VERSION ""

NS_ :

BS_:

BU_: SteeringControlModule SteeringController SteeringColumnUnit RearAxleSteeringController Engine ChassisController

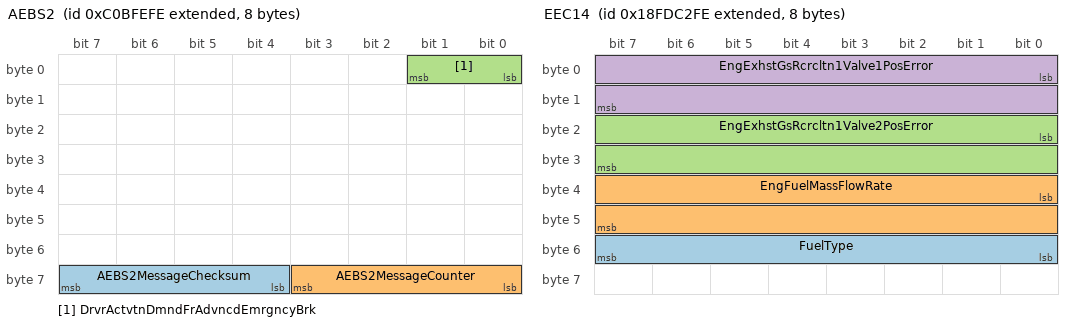
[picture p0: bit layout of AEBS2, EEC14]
BO_ 2349596414 AEBS2: 8 Vector__XXX
 SG_ AEBS2MessageChecksum : 60|4@1+ (1,0) [0|15] "" Vector__XXX
 SG_ AEBS2MessageCounter : 56|4@1+ (1,0) [0|15] "" Vector__XXX
 SG_ DrvrActvtnDmndFrAdvncdEmrgncyBrk : 0|2@1+ (1,0) [0|3] "" Vector__XXX

BO_ 2566767358 EEC14: 8 Vector__XXX
 SG_ FuelType : 48|8@1+ (1,0) [0|255] "" Vector__XXX
 SG_ EngFuelMassFlowRate : 32|16@1+ (0.005,0) [0|321.275] "g/s" Vector__XXX
 SG_ EngExhstGsRcrcltn1Valve2PosError : 16|16@1+ (0.004,-125) [-125|132.02] "%" Vector__XXX
 SG_ EngExhstGsRcrcltn1Valve1PosError : 0|16@1+ (0.004,-125) [-125|132.02] "%" Vector__XXX

BO_ 2566706686 AT1P1I: 8 Vector__XXX
 SG_ Aftrtrtmnt1DslExhstFldPumpHeater : 0|8@1+ (0.4,0) [0|100] "%" Vector__XXX

BO_ 2566705406 EPSI: 8 Vector__XXX
 SG_ Aftertreatment2ParticulateSensor : 16|16@1+ (0.0125,0) [0|803.1875] "mg/m^3" Vector__XXX
 SG_ Aftertreatment1ParticulateSensor : 0|16@1+ (0.0125,0) [0|803.1875] "mg/m^3" Vector__XXX

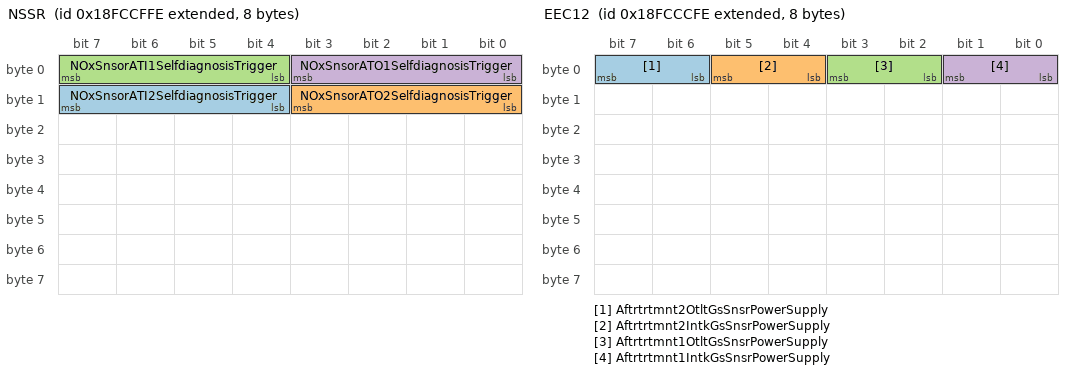
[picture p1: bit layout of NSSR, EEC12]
BO_ 2566705150 NSSR: 8 Vector__XXX
 SG_ NOxSnsorATI2SelfdiagnosisTrigger : 12|4@1+ (1,0) [0|15] "" Vector__XXX
 SG_ NOxSnsorATO2SelfdiagnosisTrigger : 8|4@1+ (1,0) [0|15] "" Vector__XXX
 SG_ NOxSnsorATI1SelfdiagnosisTrigger : 4|4@1+ (1,0) [0|15] "" Vector__XXX
 SG_ NOxSnsorATO1SelfdiagnosisTrigger : 0|4@1+ (1,0) [0|15] "" Vector__XXX

BO_ 2566704382 EEC12: 8 Vector__XXX
 SG_ Aftrtrtmnt2OtltGsSnsrPowerSupply : 6|2@1+ (1,0) [0|3] "" Vector__XXX
 SG_ Aftrtrtmnt2IntkGsSnsrPowerSupply : 4|2@1+ (1,0) [0|3] "" Vector__XXX
 SG_ Aftrtrtmnt1OtltGsSnsrPowerSupply : 2|2@1+ (1,0) [0|3] "" Vector__XXX
 SG_ Aftrtrtmnt1IntkGsSnsrPowerSupply : 0|2@1+ (1,0) [0|3] "" Vector__XXX

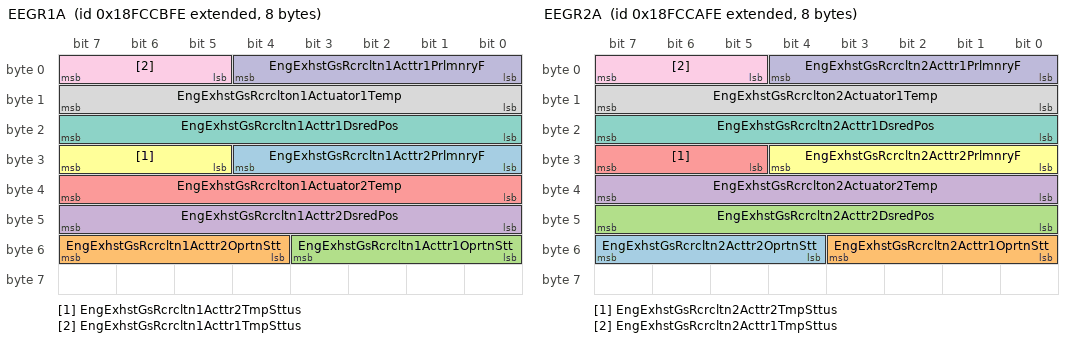
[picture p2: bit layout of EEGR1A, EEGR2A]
BO_ 2566704126 EEGR1A: 8 Vector__XXX
 SG_ EngExhstGsRcrcltn1Acttr2PrlmnryF : 24|5@1+ (1,0) [0|31] "" Vector__XXX
 SG_ EngExhstGsRcrcltn1Acttr2OprtnStt : 52|4@1+ (1,0) [0|15] "" Vector__XXX
 SG_ EngExhstGsRcrcltn1Acttr1OprtnStt : 48|4@1+ (1,0) [0|15] "" Vector__XXX
 SG_ EngExhstGsRcrcltn1Acttr2DsredPos : 40|8@1+ (0.4,0) [0|100] "%" Vector__XXX
 SG_ EngExhstGsRcrclton1Actuator2Temp : 32|8@1+ (1,-40) [-40|210] "deg C" Vector__XXX
 SG_ EngExhstGsRcrcltn1Acttr2TmpSttus : 29|3@1+ (1,0) [0|7] "" Vector__XXX
 SG_ EngExhstGsRcrcltn1Acttr1DsredPos : 16|8@1+ (0.4,0) [0|100] "%" Vector__XXX
 SG_ EngExhstGsRcrclton1Actuator1Temp : 8|8@1+ (1,-40) [-40|210] "deg C" Vector__XXX
 SG_ EngExhstGsRcrcltn1Acttr1TmpSttus : 5|3@1+ (1,0) [0|7] "" Vector__XXX
 SG_ EngExhstGsRcrcltn1Acttr1PrlmnryF : 0|5@1+ (1,0) [0|31] "" Vector__XXX

BO_ 2566703870 EEGR2A: 8 Vector__XXX
 SG_ EngExhstGsRcrcltn2Acttr2OprtnStt : 52|4@1+ (1,0) [0|15] "" Vector__XXX
 SG_ EngExhstGsRcrcltn2Acttr1OprtnStt : 48|4@1+ (1,0) [0|15] "" Vector__XXX
 SG_ EngExhstGsRcrcltn2Acttr2DsredPos : 40|8@1+ (0.4,0) [0|100] "%" Vector__XXX
 SG_ EngExhstGsRcrclton2Actuator2Temp : 32|8@1+ (1,-40) [-40|210] "deg C" Vector__XXX
 SG_ EngExhstGsRcrcltn2Acttr2TmpSttus : 29|3@1+ (1,0) [0|7] "" Vector__XXX
 SG_ EngExhstGsRcrcltn2Acttr2PrlmnryF : 24|5@1+ (1,0) [0|31] "" Vector__XXX
 SG_ EngExhstGsRcrcltn2Acttr1DsredPos : 16|8@1+ (0.4,0) [0|100] "%" Vector__XXX
 SG_ EngExhstGsRcrclton2Actuator1Temp : 8|8@1+ (1,-40) [-40|210] "deg C" Vector__XXX
 SG_ EngExhstGsRcrcltn2Acttr1TmpSttus : 5|3@1+ (1,0) [0|7] "" Vector__XXX
 SG_ EngExhstGsRcrcltn2Acttr1PrlmnryF : 0|5@1+ (1,0) [0|31] "" Vector__XXX

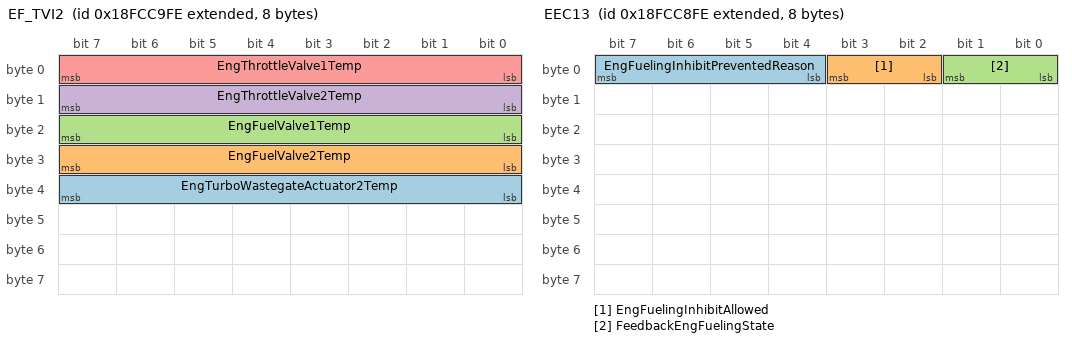
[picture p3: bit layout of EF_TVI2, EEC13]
BO_ 2566703614 EF_TVI2: 8 Vector__XXX
 SG_ EngTurboWastegateActuator2Temp : 32|8@1+ (1,-40) [-40|210] "deg C" Vector__XXX
 SG_ EngFuelValve2Temp : 24|8@1+ (1,-40) [-40|210] "deg C" Vector__XXX
 SG_ EngFuelValve1Temp : 16|8@1+ (1,-40) [-40|210] "deg C" Vector__XXX
 SG_ EngThrottleValve2Temp : 8|8@1+ (1,-40) [-40|210] "deg C" Vector__XXX
 SG_ EngThrottleValve1Temp : 0|8@1+ (1,-40) [-40|210] "deg C" Vector__XXX

BO_ 2566703358 EEC13: 8 Vector__XXX
 SG_ EngFuelingInhibitPreventedReason : 4|4@1+ (1,0) [0|15] "" Vector__XXX
 SG_ EngFuelingInhibitAllowed : 2|2@1+ (1,0) [0|3] "" Vector__XXX
 SG_ FeedbackEngFuelingState : 0|2@1+ (1,0) [0|3] "" Vector__XXX

BO_ 2566702590 A1SCREGT2: 8 Vector__XXX
 SG_ Aftrtrtmnt1SCRIntrmdtGsTmpPrlmnr : 16|5@1+ (1,0) [0|31] "" Vector__XXX
 SG_ Aftrtrtmnt1SCRIntrmediateGasTemp : 0|16@1+ (0.03125,-273) [-273|1734.96875] "deg C" Vector__XXX

BO_ 2566702334 A2SCREGT2: 8 Vector__XXX
 SG_ Aftrtrtmnt2SCRIntrmdtGsTmpPrlmnr : 16|5@1+ (1,0) [0|31] "" Vector__XXX
 SG_ Aftrtrtmnt2SCRIntrmediateGasTemp : 0|16@1+ (0.03125,-273) [-273|1734.96875] "deg C" Vector__XXX

BO_ 2566702078 GFI4: 8 Vector__XXX
 SG_ SupplyGasMethanePercentage : 0|16@1+ (0.0025,0) [0|160.6375] "%" Vector__XXX

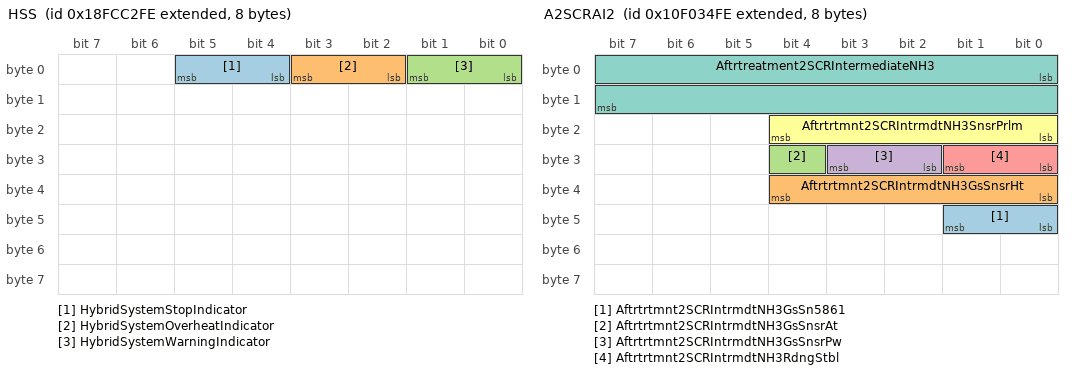
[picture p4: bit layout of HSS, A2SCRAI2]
BO_ 2566701822 HSS: 8 Vector__XXX
 SG_ HybridSystemStopIndicator : 4|2@1+ (1,0) [0|3] "" Vector__XXX
 SG_ HybridSystemOverheatIndicator : 2|2@1+ (1,0) [0|3] "" Vector__XXX
 SG_ HybridSystemWarningIndicator : 0|2@1+ (1,0) [0|3] "" Vector__XXX

BO_ 2431661310 A2SCRAI2: 8 Vector__XXX
 SG_ Aftrtrtmnt2SCRIntrmdtNH3GsSn5861 : 40|2@1+ (1,0) [0|3] "" Vector__XXX
 SG_ Aftrtrtmnt2SCRIntrmdtNH3GsSnsrHt : 32|5@1+ (1,0) [0|31] "" Vector__XXX
 SG_ Aftrtrtmnt2SCRIntrmdtNH3GsSnsrAt : 28|1@1+ (1,0) [0|1] "" Vector__XXX
 SG_ Aftrtrtmnt2SCRIntrmdtNH3GsSnsrPw : 26|2@1+ (1,0) [0|3] "" Vector__XXX
 SG_ Aftrtrtmnt2SCRIntrmdtNH3RdngStbl : 24|2@1+ (1,0) [0|3] "" Vector__XXX
 SG_ Aftrtrtmnt2SCRIntrmdtNH3SnsrPrlm : 16|5@1+ (1,0) [0|31] "" Vector__XXX
 SG_ Aftrtreatment2SCRIntermediateNH3 : 0|16@1+ (0.1,0) [0|6425.5] "m^3/h" Vector__XXX

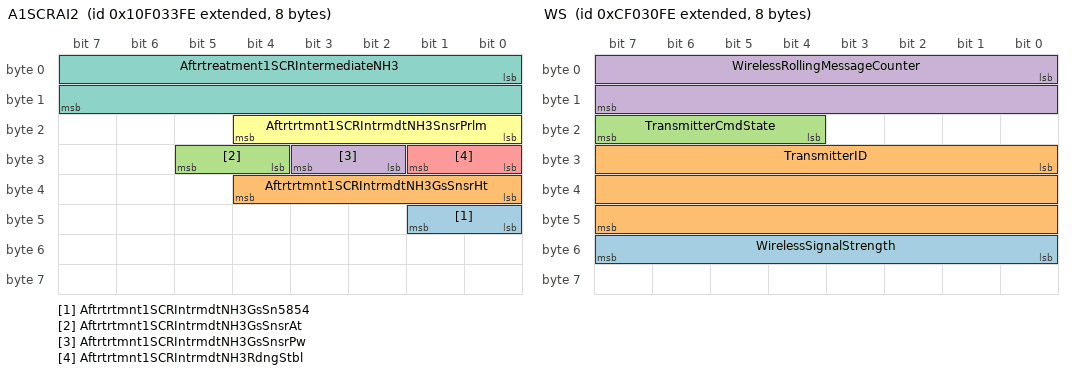
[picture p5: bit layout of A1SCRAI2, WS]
BO_ 2431661054 A1SCRAI2: 8 Vector__XXX
 SG_ Aftrtrtmnt1SCRIntrmdtNH3GsSn5854 : 40|2@1+ (1,0) [0|3] "" Vector__XXX
 SG_ Aftrtrtmnt1SCRIntrmdtNH3GsSnsrHt : 32|5@1+ (1,0) [0|31] "" Vector__XXX
 SG_ Aftrtrtmnt1SCRIntrmdtNH3GsSnsrAt : 28|2@1+ (1,0) [0|3] "" Vector__XXX
 SG_ Aftrtrtmnt1SCRIntrmdtNH3GsSnsrPw : 26|2@1+ (1,0) [0|3] "" Vector__XXX
 SG_ Aftrtrtmnt1SCRIntrmdtNH3RdngStbl : 24|2@1+ (1,0) [0|3] "" Vector__XXX
 SG_ Aftrtrtmnt1SCRIntrmdtNH3SnsrPrlm : 16|5@1+ (1,0) [0|31] "" Vector__XXX
 SG_ Aftrtreatment1SCRIntermediateNH3 : 0|16@1+ (0.3,0) [0|19276.5] "g/h" Vector__XXX

BO_ 2230334206 LDISP: 8 Vector__XXX
 SG_ LnrDsplcmntSnsrSnsrFigureOfMerit : 16|2@1+ (1,0) [0|3] "" Vector__XXX
 SG_ MeasuredLinearDisplacement : 0|16@1+ (0.1,0) [0|6425.5] "mm" Vector__XXX

BO_ 2230333950 WAND: 8 Vector__XXX
 SG_ WandSensorFigureOfMerit : 16|2@1+ (1,0) [0|3] "" Vector__XXX
 SG_ WandAngle : 0|16@1+ (0.002,-64) [-64|64.51] "deg" Vector__XXX

BO_ 2364551422 WS: 8 Vector__XXX
 SG_ WirelessSignalStrength : 48|8@1+ (0.5,0) [-125|0] "dBm" Vector__XXX
 SG_ TransmitterID : 24|24@1+ (1,0) [0|16449635] "" Vector__XXX
 SG_ TransmitterCmdState : 20|4@1+ (1,0) [0|15] "" Vector__XXX
 SG_ WirelessRollingMessageCounter : 0|16@1+ (1,0) [0|64255] "" Vector__XXX

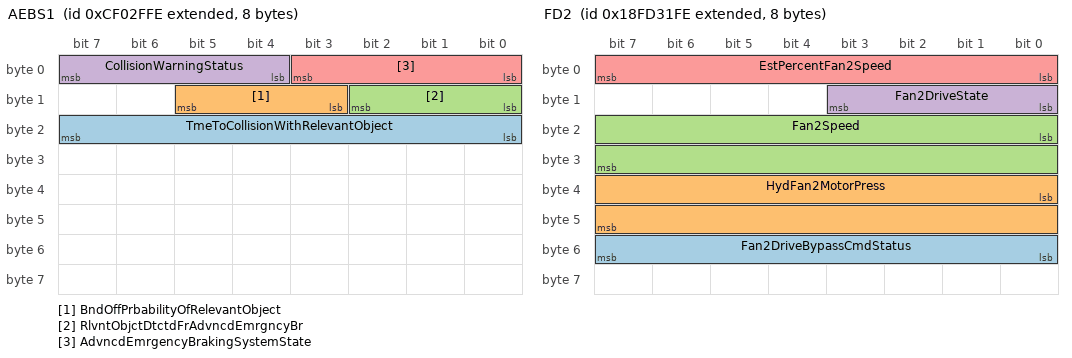
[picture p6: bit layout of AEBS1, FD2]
BO_ 2364551166 AEBS1: 8 Vector__XXX
 SG_ TmeToCollisionWithRelevantObject : 16|8@1+ (0.05,0) [0|12.5] "s" Vector__XXX
 SG_ BndOffPrbabilityOfRelevantObject : 11|3@1+ (1,0) [0|7] "" Vector__XXX
 SG_ RlvntObjctDtctdFrAdvncdEmrgncyBr : 8|3@1+ (1,0) [0|7] "" Vector__XXX
 SG_ CollisionWarningStatus : 4|4@1+ (1,0) [0|15] "" Vector__XXX
 SG_ AdvncdEmrgencyBrakingSystemState : 0|4@1+ (1,0) [0|15] "" Vector__XXX

BO_ 2566730238 FD2: 8 Vector__XXX
 SG_ Fan2DriveBypassCmdStatus : 48|8@1+ (0.4,0) [0|100] "%" Vector__XXX
 SG_ HydFan2MotorPress : 32|16@1+ (0.5,0) [0|32127.5] "kPa" Vector__XXX
 SG_ Fan2Speed : 16|16@1+ (0.125,0) [0|8031.875] "rpm" Vector__XXX
 SG_ Fan2DriveState : 8|4@1+ (1,0) [0|15] "" Vector__XXX
 SG_ EstPercentFan2Speed : 0|8@1+ (0.4,0) [0|100] "%" Vector__XXX

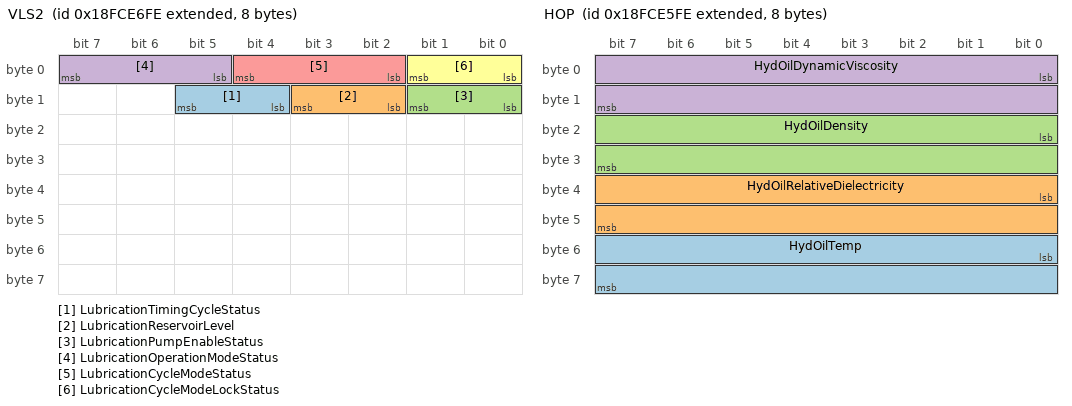
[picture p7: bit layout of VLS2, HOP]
BO_ 2566711038 VLS2: 8 Vector__XXX
 SG_ LubricationTimingCycleStatus : 12|2@1+ (1,0) [0|3] "" Vector__XXX
 SG_ LubricationReservoirLevel : 10|2@1+ (1,0) [0|3] "" Vector__XXX
 SG_ LubricationPumpEnableStatus : 8|2@1+ (1,0) [0|3] "" Vector__XXX
 SG_ LubricationOperationModeStatus : 5|3@1+ (1,0) [0|7] "" Vector__XXX
 SG_ LubricationCycleModeStatus : 2|3@1+ (1,0) [0|7] "" Vector__XXX
 SG_ LubricationCycleModeLockStatus : 0|2@1+ (1,0) [0|3] "" Vector__XXX

BO_ 2566710782 HOP: 8 Vector__XXX
 SG_ HydOilTemp : 48|16@1+ (0.03125,-273) [-273|1734.96875] "deg C" Vector__XXX
 SG_ HydOilRelativeDielectricity : 32|16@1+ (0.0001220703125,0) [0|7.844] "" Vector__XXX
 SG_ HydOilDensity : 16|16@1+ (3.052E-005,0) [0|1.961] "g/cc" Vector__XXX
 SG_ HydOilDynamicViscosity : 0|16@1+ (0.015625,0) [0|1003.984375] "Cp" Vector__XXX

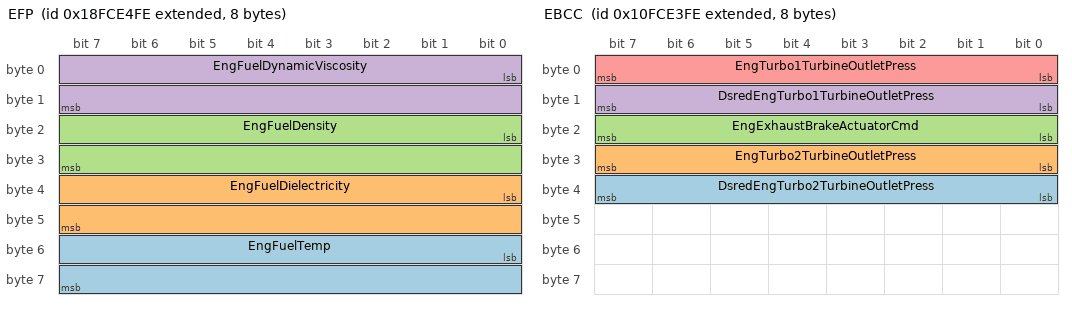
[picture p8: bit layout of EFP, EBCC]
BO_ 2566710526 EFP: 8 Vector__XXX
 SG_ EngFuelTemp : 48|16@1+ (0.03125,-273) [-273|1734.96875] "deg C" Vector__XXX
 SG_ EngFuelDielectricity : 32|16@1+ (0.0001220703125,0) [0|7.844] "" Vector__XXX
 SG_ EngFuelDensity : 16|16@1+ (3.052E-005,0) [0|1.961] "g/cc" Vector__XXX
 SG_ EngFuelDynamicViscosity : 0|16@1+ (0.015625,0) [0|1003.984375] "Cp" Vector__XXX

BO_ 2432492542 EBCC: 8 Vector__XXX
 SG_ DsredEngTurbo2TurbineOutletPress : 32|8@1+ (2,0) [0|500] "kPa" Vector__XXX
 SG_ EngTurbo2TurbineOutletPress : 24|8@1+ (2,0) [0|500] "kPa" Vector__XXX
 SG_ EngExhaustBrakeActuatorCmd : 16|8@1+ (0.4,0) [0|100] "%" Vector__XXX
 SG_ DsredEngTurbo1TurbineOutletPress : 8|8@1+ (2,0) [0|500] "kPa" Vector__XXX
 SG_ EngTurbo1TurbineOutletPress : 0|8@1+ (2,0) [0|500] "kPa" Vector__XXX

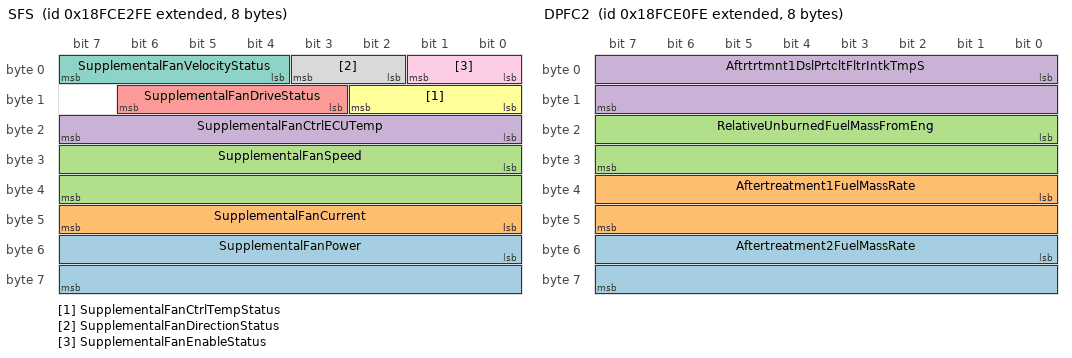
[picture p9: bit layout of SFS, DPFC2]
BO_ 2566710014 SFS: 8 Vector__XXX
 SG_ SupplementalFanPower : 48|16@1+ (0.5,0) [0|32127.5] "W" Vector__XXX
 SG_ SupplementalFanCurrent : 40|8@1+ (1,-125) [-125|125] "A" Vector__XXX
 SG_ SupplementalFanSpeed : 24|16@1+ (0.5,0) [0|32127.5] "rpm" Vector__XXX
 SG_ SupplementalFanCtrlECUTemp : 16|8@1+ (1,-40) [-40|210] "deg C" Vector__XXX
 SG_ SupplementalFanDriveStatus : 11|4@1+ (1,0) [0|15] "" Vector__XXX
 SG_ SupplementalFanCtrlTempStatus : 8|3@1+ (1,0) [0|7] "" Vector__XXX
 SG_ SupplementalFanVelocityStatus : 4|4@1+ (1,0) [0|15] "" Vector__XXX
 SG_ SupplementalFanDirectionStatus : 2|2@1+ (1,0) [0|3] "" Vector__XXX
 SG_ SupplementalFanEnableStatus : 0|2@1+ (1,0) [0|3] "" Vector__XXX

BO_ 2566709758 LFE2: 8 Vector__XXX
 SG_ HighResolutionEngFuelRate : 0|32@1+ (0.001,0) [0|4211081.215] "L/h" Vector__XXX

BO_ 2566709502 DPFC2: 8 Vector__XXX
 SG_ Aftertreatment2FuelMassRate : 48|16@1+ (0.05,0) [0|3212.75] "g/m" Vector__XXX
 SG_ Aftertreatment1FuelMassRate : 32|16@1+ (0.05,0) [0|3212.75] "g/m" Vector__XXX
 SG_ RelativeUnburnedFuelMassFromEng : 16|16@1+ (0.0025,0) [0|160.6375] "%" Vector__XXX
 SG_ Aftrtrtmnt1DslPrtcltFltrIntkTmpS : 0|16@1+ (0.03125,-273) [-273|1734.96875] "deg C" Vector__XXX

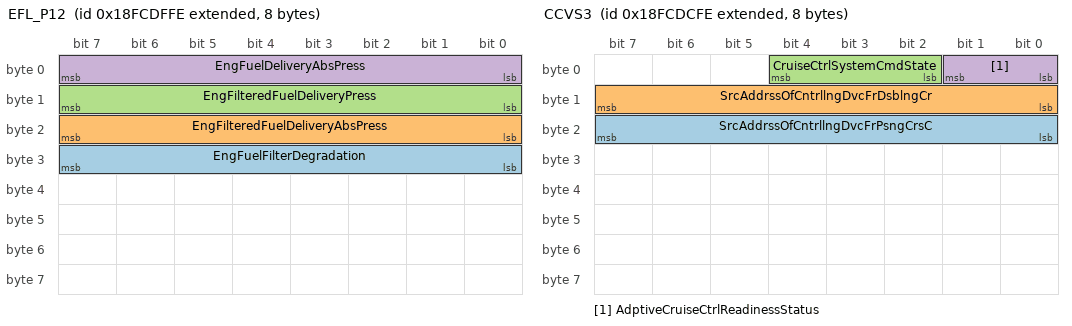
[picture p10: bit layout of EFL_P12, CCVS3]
BO_ 2566709246 EFL_P12: 8 Vector__XXX
 SG_ EngFuelFilterDegradation : 24|8@1+ (1,0) [0|250] "%" Vector__XXX
 SG_ EngFilteredFuelDeliveryAbsPress : 16|8@1+ (4,0) [0|1000] "kPa" Vector__XXX
 SG_ EngFilteredFuelDeliveryPress : 8|8@1+ (4,0) [0|1000] "kPa" Vector__XXX
 SG_ EngFuelDeliveryAbsPress : 0|8@1+ (4,0) [0|1000] "kPa" Vector__XXX

BO_ 2566708990 AT1AC3: 8 Vector__XXX
 SG_ Aftertreatment1SecondAirAbsPress : 0|16@1+ (0.1,0) [0|6425.5] "kPa" Vector__XXX

BO_ 2566708734 AT2AC3: 8 Vector__XXX
 SG_ Aftertreatment2SecondAirAbsPress : 0|16@1+ (0.1,0) [0|6425.5] "kPa" Vector__XXX

BO_ 2566708478 CCVS3: 8 Vector__XXX
 SG_ SrcAddrssOfCntrllngDvcFrPsngCrsC : 16|8@1+ (1,0) [0|255] "" Vector__XXX
 SG_ SrcAddrssOfCntrllngDvcFrDsblngCr : 8|8@1+ (1,0) [0|255] "" Vector__XXX
 SG_ CruiseCtrlSystemCmdState : 2|3@1+ (1,0) [0|7] "" Vector__XXX
 SG_ AdptiveCruiseCtrlReadinessStatus : 0|2@1+ (1,0) [0|3] "" Vector__XXX

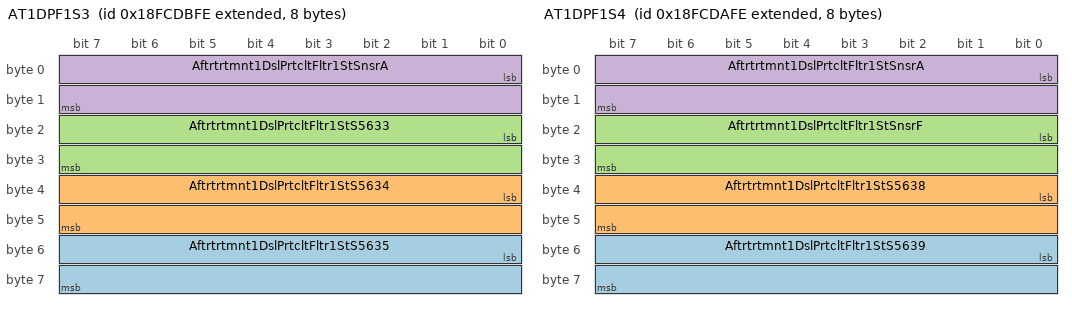
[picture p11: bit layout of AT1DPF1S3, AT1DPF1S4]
BO_ 2566708222 AT1DPF1S3: 8 Vector__XXX
 SG_ Aftrtrtmnt1DslPrtcltFltr1StS5635 : 48|16@1+ (0.1,0) [0|6425.5] "MHz" Vector__XXX
 SG_ Aftrtrtmnt1DslPrtcltFltr1StS5634 : 32|16@1+ (0.1,0) [0|6425.5] "MHz" Vector__XXX
 SG_ Aftrtrtmnt1DslPrtcltFltr1StS5633 : 16|16@1+ (0.1,0) [0|6425.5] "MHz" Vector__XXX
 SG_ Aftrtrtmnt1DslPrtcltFltr1StSnsrA : 0|16@1+ (0.1,0) [0|6425.5] "MHz" Vector__XXX

BO_ 2566707966 AT1DPF1S4: 8 Vector__XXX
 SG_ Aftrtrtmnt1DslPrtcltFltr1StS5639 : 48|16@1+ (0.0025,0) [0|160.6375] "%" Vector__XXX
 SG_ Aftrtrtmnt1DslPrtcltFltr1StS5638 : 32|16@1+ (0.1,0) [0|6425.5] "MHz" Vector__XXX
 SG_ Aftrtrtmnt1DslPrtcltFltr1StSnsrF : 16|16@1+ (0.0025,0) [0|160.6375] "%" Vector__XXX
 SG_ Aftrtrtmnt1DslPrtcltFltr1StSnsrA : 0|16@1+ (0.1,0) [0|6425.5] "MHz" Vector__XXX

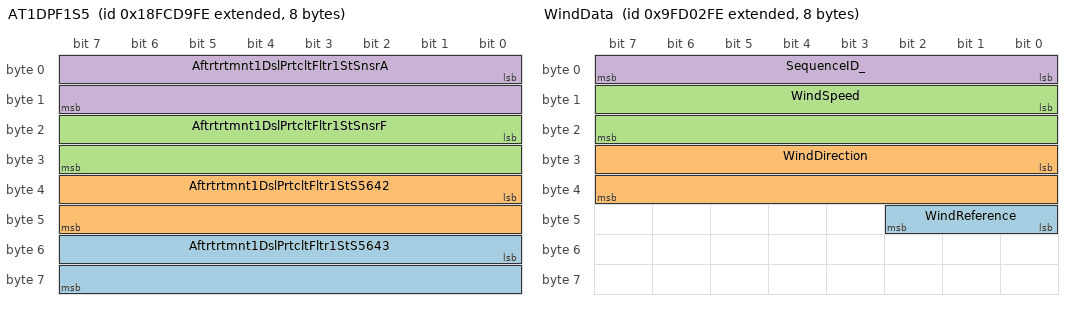
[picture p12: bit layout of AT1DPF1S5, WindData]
BO_ 2566707710 AT1DPF1S5: 8 Vector__XXX
 SG_ Aftrtrtmnt1DslPrtcltFltr1StS5643 : 48|16@1+ (0.0025,0) [0|160.6375] "%" Vector__XXX
 SG_ Aftrtrtmnt1DslPrtcltFltr1StS5642 : 32|16@1+ (0.1,0) [0|6425.5] "MHz" Vector__XXX
 SG_ Aftrtrtmnt1DslPrtcltFltr1StSnsrF : 16|16@1+ (0.0025,0) [0|160.6375] "%" Vector__XXX
 SG_ Aftrtrtmnt1DslPrtcltFltr1StSnsrA : 0|16@1+ (0.1,0) [0|6425.5] "MHz" Vector__XXX

BO_ 2315059966 WindData: 8 Vector__XXX
 SG_ WindReference : 40|3@1+ (1,0) [0|7] "" Vector__XXX
 SG_ WindDirection : 24|16@1+ (0.0001,0) [0|6.28318] "rad" Vector__XXX
 SG_ WindSpeed : 8|16@1+ (0.01,0) [0|655.32] "m/s" Vector__XXX
 SG_ SequenceID_ : 0|8@1+ (1,0) [0|252] "" Vector__XXX

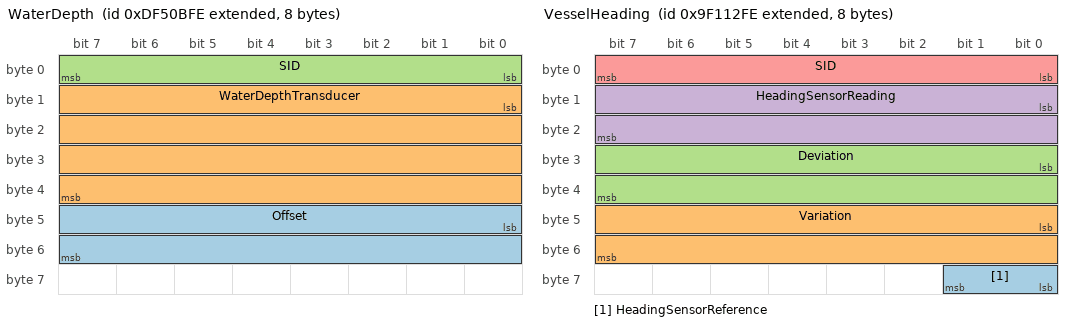
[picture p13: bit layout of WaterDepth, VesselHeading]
BO_ 2381646846 WaterDepth: 8 Vector__XXX
 SG_ Offset : 40|16@1- (0.001,0) [-32.764|32.764] "m" Vector__XXX
 SG_ WaterDepthTransducer : 8|32@1+ (0.01,0) [0|42950000] "m" Vector__XXX
 SG_ SID : 0|8@1+ (1,0) [0|252] "" Vector__XXX

BO_ 2315129598 VesselSpeedComponents: 12 Vector__XXX
 SG_ SternSpeedGroundreferenced : 80|16@1- (0.001,0) [-32.764|32.764] "m/s" Vector__XXX
 SG_ SternSpeedWaterreferenced : 64|16@1- (0.001,0) [-32.764|32.764] "m/s" Vector__XXX
 SG_ TransverseSpeedGroundreferenced : 48|16@1- (0.001,0) [-32.764|32.764] "m/s" Vector__XXX
 SG_ LngtudinalSpeedGroundreferenced : 32|16@1- (0.001,0) [-32.764|32.764] "m/s" Vector__XXX
 SG_ TransverseSpeedWaterreferenced : 16|16@1- (0.001,0) [-32.764|32.764] "m/s" Vector__XXX
 SG_ LngitudinalSpeedWaterreferenced : 0|16@1- (0.001,0) [-32.764|32.764] "m/s" Vector__XXX

BO_ 2314277630 VesselHeading: 8 Vector__XXX
 SG_ HeadingSensorReference : 56|2@1+ (1,0) [0|3] "" Vector__XXX
 SG_ Variation : 40|16@1- (0.0001,0) [-3.14159|3.14159] "rad" Vector__XXX
 SG_ Deviation : 24|16@1- (0.0001,0) [-3.14159|3.14159] "rad" Vector__XXX
 SG_ HeadingSensorReading : 8|16@1+ (0.0001,0) [0|6.28318] "rad" Vector__XXX
 SG_ SID : 0|8@1+ (1,0) [0|252] "" Vector__XXX

BO_ 2583172606 UserDatumSettings: 37 Vector__XXX
 SG_ DatumName : 288|8@1+ (1,0) [0|255] "ASCII" Vector__XXX
 SG_ EllipsoidFlatteningInverse : 256|32@1- (1,0) [-3.4E+038|3.4E+038] "" Vector__XXX
 SG_ EllipsoidSemimajorAxis : 224|32@1- (0.01,0) [-21470000|21470000] "m" Vector__XXX
 SG_ Scale : 192|32@1- (1,0) [-3.4E+038|3.4E+038] "" Vector__XXX
 SG_ RotationInZ : 160|32@1- (1,0) [-3.4E+038|3.4E+038] "" Vector__XXX
 SG_ RotationInY : 128|32@1- (1,0) [-3.4E+038|3.4E+038] "" Vector__XXX
 SG_ RotationInX : 96|32@1- (1,0) [-3.4E+038|3.4E+038] "" Vector__XXX
 SG_ DeltaZ : 64|32@1- (0.01,0) [-21470000|21470000] "m" Vector__XXX
 SG_ DeltaY : 32|32@1- (0.01,0) [-21470000|21470000] "m" Vector__XXX
 SG_ DeltaX : 0|32@1- (0.01,0) [-21470000|21470000] "m" Vector__XXX

BO_ 2515667198 TripParametersVessel: 14 Vector__XXX
 SG_ TripRunTime : 80|32@1+ (0.001,0) [0|4295000] "sec" Vector__XXX
 SG_ EstFuelRemaining : 64|16@1+ (0.001,0) [0|65.532] "cu m" Vector__XXX
 SG_ DistanceToEmpty : 32|32@1+ (0.01,0) [0|42950000] "m" Vector__XXX
 SG_ TimeToEmpty : 0|32@1+ (0.001,0) [0|4295000] "sec" Vector__XXX

BO_ 2515667454 TripParametersEng: 9 Vector__XXX
 SG_ InstantaneousFuelEconomy : 56|16@1- (0.0001,0) [-3.2764|3.2764] "(cu m)/hr" Vector__XXX
 SG_ FuelRateEconomy : 40|16@1- (0.0001,0) [-3.2764|3.2764] "(cu m)/hr" Vector__XXX
 SG_ FuelRateAverage : 24|16@1- (0.0001,0) [-3.2764|3.2764] "(cu m)/hr" Vector__XXX
 SG_ TripFuelUsed : 8|16@1+ (0.001,0) [0|65.532] "cu m" Vector__XXX
 SG_ EngInstance : 0|8@1+ (1,0) [0|255] "" Vector__XXX

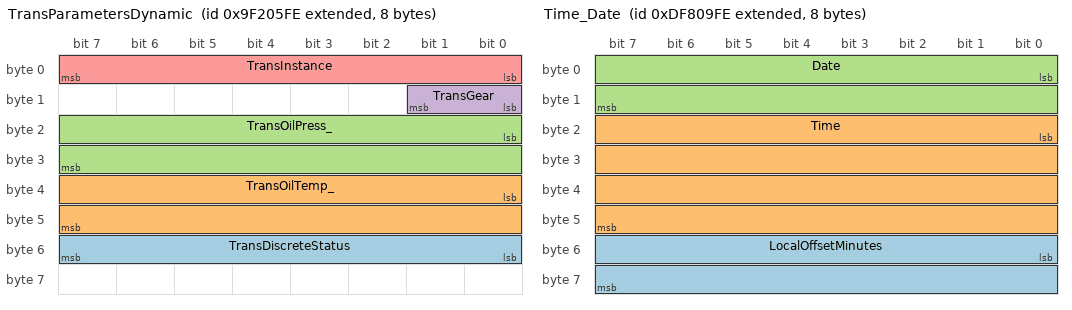
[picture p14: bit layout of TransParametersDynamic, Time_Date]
BO_ 2314339838 TransParametersDynamic: 8 Vector__XXX
 SG_ TransDiscreteStatus : 48|8@1+ (1,0) [0|255] "" Vector__XXX
 SG_ TransOilTemp_ : 32|16@1+ (0.1,0) [0|6553.2] "°K" Vector__XXX
 SG_ TransOilPress_ : 16|16@1+ (100,0) [0|6553200] "Pa" Vector__XXX
 SG_ TransGear : 8|2@1+ (1,0) [0|3] "" Vector__XXX
 SG_ TransInstance : 0|8@1+ (1,0) [0|255] "" Vector__XXX

BO_ 2314602750 TrackedTargetData: 27 Vector__XXX
 SG_ CPA : 112|32@1- (0.01,0) [-21470000|21470000] "m" Vector__XXX
 SG_ Speed : 96|16@1+ (0.01,0) [0|655.32] "m/s" Vector__XXX
 SG_ Course : 80|16@1+ (0.0001,0) [0|6.28318] "rad" Vector__XXX
 SG_ Distance : 48|32@1- (0.01,0) [-21470000|21470000] "m" Vector__XXX
 SG_ Bearing : 32|16@1+ (0.0001,0) [0|6.28318] "rad" Vector__XXX
 SG_ BearingReference : 28|2@1+ (1,0) [0|3] "" Vector__XXX
 SG_ TrackStatus : 24|4@1+ (1,0) [0|15] "" Vector__XXX
 SG_ TargetID : 8|16@1+ (1,0) [0|65532] "" Vector__XXX
 SG_ SequenceID_ : 0|8@1+ (1,0) [0|252] "" Vector__XXX
 SG_ Name : 208|8@1+ (1,0) [0|255] "ASCII" Vector__XXX
 SG_ UTCOfFix : 176|32@1+ (0.0001,0) [0|86401] "sec" Vector__XXX
 SG_ TCPA : 144|32@1- (0.001,0) [-2148000|2148000] "sec" Vector__XXX

BO_ 2381842942 Time_Date: 8 Vector__XXX
 SG_ LocalOffsetMinutes : 48|16@1- (1,0) [-32764|32764] "mins" Vector__XXX
 SG_ Time : 16|32@1+ (0.0001,0) [0|86401] "sec" Vector__XXX
 SG_ Date : 0|16@1+ (1,0) [0|65532] "day" Vector__XXX

BO_ 2381911550 TimeTo_FromMark: 10 Vector__XXX
 SG_ MarkID : 48|32@1+ (1,0) [0|4294967292] "" Vector__XXX
 SG_ MarkType : 40|4@1+ (1,0) [0|15] "" Vector__XXX
 SG_ TimeElapsedTogoToMark : 8|32@1- (0.001,0) [-2148000|2148000] "sec" Vector__XXX
 SG_ SID : 0|8@1+ (1,0) [0|252] "" Vector__XXX

BO_ 2583499006 TideStationData: 20 Vector__XXX
 SG_ StationIDString : 152|8@1+ (1,0) [0|255] "ASCII" Vector__XXX
 SG_ TideLevelStandardDeviation : 136|16@1+ (0.01,0) [0|655.32] "m" Vector__XXX
 SG_ TideLevel : 120|16@1- (0.001,0) [-32.764|32.764] "m" Vector__XXX
 SG_ StationLocationLongitude : 88|32@1- (1E-007,0) [-180|180] "deg" Vector__XXX
 SG_ StationLocationLatitude : 56|32@1- (1E-007,0) [-90|90] "deg" Vector__XXX
 SG_ MeasurementTime : 24|32@1+ (0.0001,0) [0|86401] "sec" Vector__XXX
 SG_ MeasurementDate : 8|16@1+ (1,0) [0|65532] "day" Vector__XXX
 SG_ TideTendency : 4|2@1+ (1,0) [0|3] "" Vector__XXX
 SG_ Mode : 0|4@1+ (1,0) [0|15] "" Vector__XXX

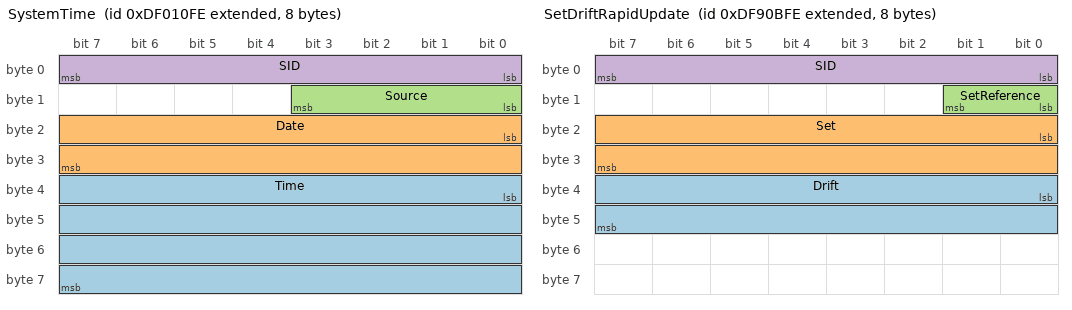
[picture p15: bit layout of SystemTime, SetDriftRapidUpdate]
BO_ 2381320446 SystemTime: 8 Vector__XXX
 SG_ Time : 32|32@1+ (0.0001,0) [0|86401] "sec" Vector__XXX
 SG_ Date : 16|16@1+ (1,0) [0|65532] "day" Vector__XXX
 SG_ Source : 8|4@1+ (1,0) [0|15] "" Vector__XXX
 SG_ SID : 0|8@1+ (1,0) [0|252] "" Vector__XXX

BO_ 2381451006 SwitchBankCtrl: 8 Vector__XXX
 SG_ Switch28 : 62|2@1+ (1,0) [0|3] "" Vector__XXX
 SG_ Switch27 : 60|2@1+ (1,0) [0|3] "" Vector__XXX
 SG_ Switch26 : 58|2@1+ (1,0) [0|3] "" Vector__XXX
 SG_ Switch25 : 56|2@1+ (1,0) [0|3] "" Vector__XXX
 SG_ Switch24 : 54|2@1+ (1,0) [0|3] "" Vector__XXX
 SG_ Switch23 : 52|2@1+ (1,0) [0|3] "" Vector__XXX
 SG_ Switch22 : 50|2@1+ (1,0) [0|3] "" Vector__XXX
 SG_ Switch21 : 48|2@1+ (1,0) [0|3] "" Vector__XXX
 SG_ Switch20 : 46|2@1+ (1,0) [0|3] "" Vector__XXX
 SG_ Switch19 : 44|2@1+ (1,0) [0|3] "" Vector__XXX
 SG_ Switch18 : 42|2@1+ (1,0) [0|3] "" Vector__XXX
 SG_ Switch17 : 40|2@1+ (1,0) [0|3] "" Vector__XXX
 SG_ Switch16 : 38|2@1+ (1,0) [0|3] "" Vector__XXX
 SG_ Switch15 : 36|2@1+ (1,0) [0|3] "" Vector__XXX
 SG_ Switch14 : 34|2@1+ (1,0) [0|3] "" Vector__XXX
 SG_ Switch13 : 32|2@1+ (1,0) [0|3] "" Vector__XXX
 SG_ Switch12 : 30|2@1+ (1,0) [0|3] "" Vector__XXX
 SG_ Switch11 : 28|2@1+ (1,0) [0|3] "" Vector__XXX
 SG_ Switch10 : 26|2@1+ (1,0) [0|3] "" Vector__XXX
 SG_ Switch9 : 24|2@1+ (1,0) [0|3] "" Vector__XXX
 SG_ Switch8 : 22|2@1+ (1,0) [0|3] "" Vector__XXX
 SG_ Switch7 : 20|2@1+ (1,0) [0|3] "" Vector__XXX
 SG_ Switch6 : 18|2@1+ (1,0) [0|3] "" Vector__XXX
 SG_ Switch5 : 16|2@1+ (1,0) [0|3] "" Vector__XXX
 SG_ Switch4 : 14|2@1+ (1,0) [0|3] "" Vector__XXX
 SG_ Switch3 : 12|2@1+ (1,0) [0|3] "" Vector__XXX
 SG_ Switch2 : 10|2@1+ (1,0) [0|3] "" Vector__XXX
 SG_ Switch1 : 8|2@1+ (1,0) [0|3] "" Vector__XXX
 SG_ SwitchBankInstance : 0|8@1+ (1,0) [0|252] "" Vector__XXX

BO_ 2314535934 Speed: 9 Vector__XXX
 SG_ SpeedGroundReferenced : 24|22@1+ (0.01,0) [0|655.32] "m/s" Vector__XXX
 SG_ SpeedWaterReferenced : 8|16@1+ (0.01,0) [0|655.32] "m/s" Vector__XXX
 SG_ SequenceID_ : 0|8@1+ (1,0) [0|252] "" Vector__XXX

BO_ 2315129086 SmallCraftStatus: 8 Vector__XXX
 SG_ StarboardTrimTab : 8|8@1- (1,0) [-124|124] "" Vector__XXX
 SG_ PortTrimTab : 0|8@1- (1,0) [-124|124] "" Vector__XXX

BO_ 2381908990 SetDriftRapidUpdate: 8 Vector__XXX
 SG_ Drift : 32|16@1+ (0.01,0) [0|655.32] "m/s" Vector__XXX
 SG_ Set : 16|16@1+ (0.0001,0) [0|6.28318] "rad" Vector__XXX
 SG_ SetReference : 8|2@1+ (1,0) [0|3] "" Vector__XXX
 SG_ SID : 0|8@1+ (1,0) [0|252] "" Vector__XXX

BO_ 2583499262 SalinityStationData: 22 Vector__XXX
 SG_ StationIDString : 168|8@1+ (1,0) [0|255] "ASCII" Vector__XXX
 SG_ WaterTemp : 152|16@1+ (0.01,0) [0|655.32] "°K" Vector__XXX
 SG_ Salinity : 120|32@1- (1,0) [-3.4E+038|3.4E+038] "" Vector__XXX
 SG_ StationLocationLongitude : 88|32@1- (1E-007,0) [-180|180] "deg" Vector__XXX
 SG_ StationLocationLatitude : 56|32@1- (1E-007,0) [-90|90] "deg" Vector__XXX
 SG_ MeasurementTime : 24|32@1+ (0.0001,0) [0|86401] "sec" Vector__XXX
 SG_ MeasurementDate : 8|16@1+ (1,0) [0|65532] "day" Vector__XXX
 SG_ Mode : 0|4@1+ (1,0) [0|15] "" Vector__XXX

BO_ 2650544894 RuteAndWPServiceWPListWPNamePos: 13 Vector__XXX
 SG_ WPName : 96|8@1+ (1,0) [0|255] "ASCII" Vector__XXX
 SG_ WPID : 80|16@1+ (1,0) [0|65532] "" Vector__XXX
 SG_ reserved : 64|16@1+ (1,0) [0|65532] "" Vector__XXX
 SG_ DatabaseID : 48|16@1+ (1,0) [0|65532] "" Vector__XXX
 SG_ NumberOfValidWPsInWPList : 32|16@1+ (1,0) [0|65532] "" Vector__XXX
 SG_ nItems : 16|16@1+ (1,0) [0|65532] "" Vector__XXX
 SG_ StartWPID : 0|16@1+ (1,0) [0|65532] "" Vector__XXX

BO_ 2650544382 RuteAndWPServiceDatabaseComment: 9 Vector__XXX
 SG_ CommentText : 64|8@1+ (1,0) [0|255] "ASCII" Vector__XXX
 SG_ DatabaseID : 48|16@1+ (1,0) [0|65532] "" Vector__XXX
 SG_ NumberOfDatabasesWithComments : 32|16@1+ (1,0) [0|65532] "" Vector__XXX
 SG_ nItems : 16|16@1+ (1,0) [0|65532] "" Vector__XXX
 SG_ StartDatabaseID : 0|16@1+ (1,0) [0|65532] "" Vector__XXX

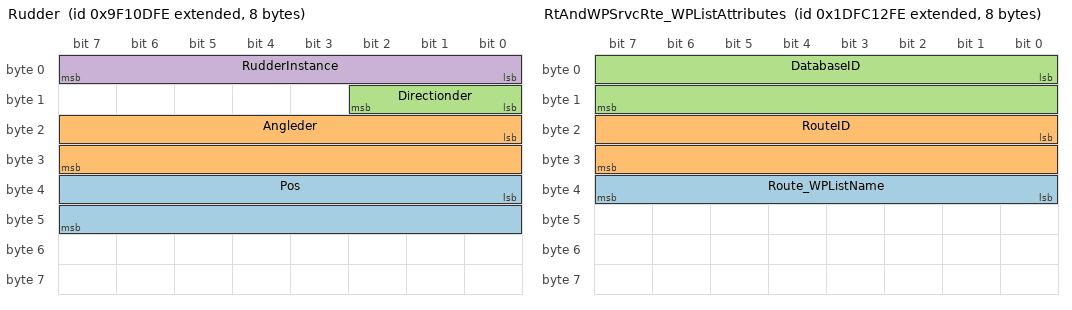
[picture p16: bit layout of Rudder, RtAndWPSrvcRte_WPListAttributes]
BO_ 2314276350 Rudder: 8 Vector__XXX
 SG_ Pos : 32|16@1- (0.0001,0) [-3.14159|3.14159] "rad" Vector__XXX
 SG_ Angleder : 16|16@1- (0.0001,0) [-3.14159|3.14159] "rad" Vector__XXX
 SG_ Directionder : 8|3@1+ (1,0) [0|7] "" Vector__XXX
 SG_ RudderInstance : 0|8@1+ (1,0) [0|255] "" Vector__XXX

BO_ 2650543614 RtAndWPSrvcXTELmtNvgationMethod: 15 Vector__XXX
 SG_ NavMethodInLegAfterWP : 112|2@1+ (1,0) [0|3] "" Vector__XXX
 SG_ XTELimitInLegAfterWP : 96|16@1- (1,0) [-32764|32764] "m" Vector__XXX
 SG_ RPS : 80|16@1+ (1,0) [0|65532] "" Vector__XXX
 SG_ RouteID : 64|16@1+ (1,0) [0|65532] "" Vector__XXX
 SG_ DatabaseID : 48|16@1+ (1,0) [0|65532] "" Vector__XXX
 SG_ NmbrOfWypntsWthASpcfcXTELmtNvMth : 32|16@1+ (1,0) [0|65532] "" Vector__XXX
 SG_ nItems : 16|16@1+ (1,0) [0|65532] "" Vector__XXX
 SG_ StartRPS : 0|16@1+ (1,0) [0|65532] "" Vector__XXX

BO_ 2650542846 RtAndWPSrvcRte_WPListAttributes: 8 Vector__XXX
 SG_ Route_WPListName : 32|8@1+ (1,0) [0|255] "ASCII" Vector__XXX
 SG_ RouteID : 16|16@1+ (1,0) [0|65532] "" Vector__XXX
 SG_ DatabaseID : 0|16@1+ (1,0) [0|65532] "" Vector__XXX

BO_ 2650543870 RouteAndWPServiceWPComment: 13 Vector__XXX
 SG_ Comment : 96|8@1+ (1,0) [0|255] "ASCII" Vector__XXX
 SG_ WPID_RPS : 80|16@1+ (1,0) [0|65532] "" Vector__XXX
 SG_ RouteID : 64|16@1+ (1,0) [0|65532] "" Vector__XXX
 SG_ DatabaseID : 48|16@1+ (1,0) [0|65532] "" Vector__XXX
 SG_ NumberOfWPsWithComments : 32|16@1+ (1,0) [0|65532] "" Vector__XXX
 SG_ nItems : 16|16@1+ (1,0) [0|65532] "" Vector__XXX
 SG_ StartID : 0|16@1+ (1,0) [0|65532] "" Vector__XXX

BO_ 2650543102 RouteAndWPServiceRouteWPNamePos: 13 Vector__XXX
 SG_ WPName : 96|8@1+ (1,0) [0|255] "ASCII" Vector__XXX
 SG_ WPID : 80|16@1+ (1,0) [0|65532] "" Vector__XXX
 SG_ RouteID : 64|16@1+ (1,0) [0|65532] "" Vector__XXX
 SG_ DatabaseID : 48|16@1+ (1,0) [0|65532] "" Vector__XXX
 SG_ NumberOfWPsInRoute : 32|16@1+ (1,0) [0|65532] "" Vector__XXX
 SG_ nItems : 16|16@1+ (1,0) [0|65532] "" Vector__XXX
 SG_ StartRPS : 0|16@1+ (1,0) [0|65532] "" Vector__XXX

BO_ 2650543358 RouteAndWPServiceRouteWPName: 13 Vector__XXX
 SG_ WPName : 96|8@1+ (1,0) [0|255] "ASCII" Vector__XXX
 SG_ WPID : 80|16@1+ (1,0) [0|65532] "" Vector__XXX
 SG_ RouteID : 64|16@1+ (1,0) [0|65532] "" Vector__XXX
 SG_ DatabaseID : 48|16@1+ (1,0) [0|65532] "" Vector__XXX
 SG_ NumberOfWPsInRoute : 32|16@1+ (1,0) [0|65532] "" Vector__XXX
 SG_ nItems : 16|16@1+ (1,0) [0|65532] "" Vector__XXX
 SG_ StartRPS : 0|16@1+ (1,0) [0|65532] "" Vector__XXX

BO_ 2650542590 RouteAndWPServiceRouteList: 11 Vector__XXX
 SG_ RouteName : 80|8@1+ (1,0) [0|255] "ASCII" Vector__XXX
 SG_ RouteID : 64|16@1+ (1,0) [0|65532] "" Vector__XXX
 SG_ DatabaseID : 48|16@1+ (1,0) [0|65532] "" Vector__XXX
 SG_ NmbrOfRoutesAvailableInDatabase : 32|16@1+ (1,0) [0|65532] "" Vector__XXX
 SG_ nItems : 16|16@1+ (1,0) [0|65532] "" Vector__XXX
 SG_ StartRouteID : 0|16@1+ (1,0) [0|65532] "" Vector__XXX

BO_ 2650544126 RouteAndWPServiceRouteComment: 11 Vector__XXX
 SG_ Comment : 80|8@1+ (1,0) [0|255] "ASCII" Vector__XXX
 SG_ RouteID : 64|16@1+ (1,0) [0|65532] "" Vector__XXX
 SG_ DatabaseID : 48|16@1+ (1,0) [0|65532] "" Vector__XXX
 SG_ NumberOfRoutesWithComments : 32|16@1+ (1,0) [0|65532] "" Vector__XXX
 SG_ nItems : 16|16@1+ (1,0) [0|65532] "" Vector__XXX
 SG_ StartRouteID : 0|16@1+ (1,0) [0|65532] "" Vector__XXX

BO_ 2650544638 RouteAndWPServiceRadiusOfTurn: 14 Vector__XXX
 SG_ RadiusOfTurn : 96|16@1- (1,0) [-32764|32764] "m" Vector__XXX
 SG_ RPS : 80|16@1+ (1,0) [0|65532] "" Vector__XXX
 SG_ RouteID : 64|16@1+ (1,0) [0|65532] "" Vector__XXX
 SG_ DatabaseID : 48|16@1+ (1,0) [0|65532] "" Vector__XXX
 SG_ NmbrOfWypntsWthASpcfcRdusOfTurn : 32|16@1+ (1,0) [0|65532] "" Vector__XXX
 SG_ nItems : 16|16@1+ (1,0) [0|65532] "" Vector__XXX
 SG_ StartRPS : 0|16@1+ (1,0) [0|65532] "" Vector__XXX

BO_ 2650542334 RouteAndWPServiceDatabaseList: 9 Vector__XXX
 SG_ DatabaseName : 64|8@1+ (1,0) [0|255] "ASCII" Vector__XXX
 SG_ DatabaseID : 48|16@1+ (1,0) [0|65532] "" Vector__XXX
 SG_ NumberOfDatabasesAvailable : 32|16@1+ (1,0) [0|65532] "" Vector__XXX
 SG_ nItems : 16|16@1+ (1,0) [0|65532] "" Vector__XXX
 SG_ StartDatabaseID : 0|16@1+ (1,0) [0|65532] "" Vector__XXX

BO_ 2314277886 RateOfTurn: 8 Vector__XXX
 SG_ RateOfTurn : 8|16@1- (1,0) [-32768|32767] "rad/s" Vector__XXX
 SG_ SequenceID_ : 0|8@1+ (1,0) [0|252] "" Vector__XXX

BO_ 2382039038 RadioFrequency_Mode_Power: 9 Vector__XXX
 SG_ RadioChannel : 64|8@1+ (1,0) [0|255] "ASCII" Vector__XXX
 SG_ TxFrequency : 32|32@1+ (10,0) [0|327040] "Hz" Vector__XXX
 SG_ RxFrequency : 0|32@1+ (10,0) [0|327040] "Hz" Vector__XXX

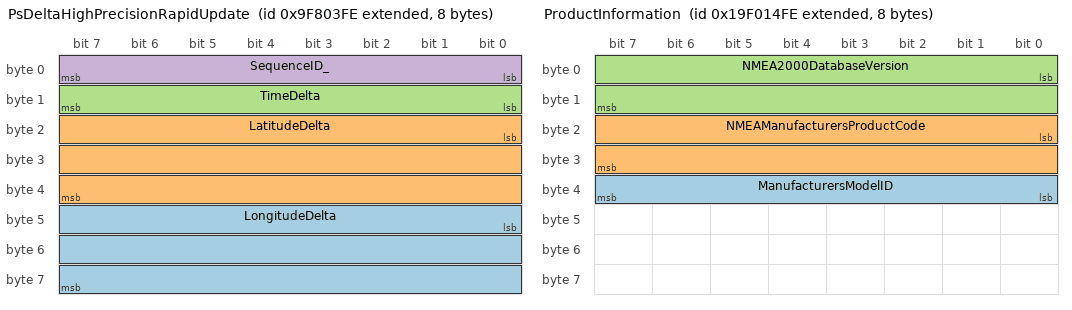
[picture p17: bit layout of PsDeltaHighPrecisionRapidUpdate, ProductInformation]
BO_ 2314732542 PsDeltaHighPrecisionRapidUpdate: 8 Vector__XXX
 SG_ LongitudeDelta : 40|24@1- (1E-005,0) [-83|83] "s('')" Vector__XXX
 SG_ LatitudeDelta : 16|24@1- (1E-005,0) [-83|83] "s('')" Vector__XXX
 SG_ TimeDelta : 8|8@1+ (0.005,0) [0|1.26] "sec" Vector__XXX
 SG_ SequenceID_ : 0|8@1+ (1,0) [0|252] "" Vector__XXX

BO_ 2582648062 ProductInformation: 8 Vector__XXX
 SG_ ManufacturersModelID : 32|8@1+ (1,0) [0|255] "ASCII" Vector__XXX
 SG_ NMEAManufacturersProductCode : 16|16@1+ (1,0) [0|65532] "" Vector__XXX
 SG_ NMEA2000DatabaseVersion : 0|16@1+ (1,0) [0|65532] "" Vector__XXX

BO_ 2314732030 PosRapidUpdate: 8 Vector__XXX
 SG_ Longitude_ : 32|32@1- (1E-007,0) [-180|180] "deg" Vector__XXX
 SG_ Latitude_ : 0|32@1- (1E-007,0) [-90|90] "deg" Vector__XXX

BO_ 2582576894 PGNLstTransmitPGNsGroupFunction: 8 Vector__XXX
 SG_ VrblNmbrOfFldsFldNmber2Repeated2 m1 : 32|24@1+ (1,0) [0|16777215] "" Vector__XXX
 SG_ FirstPGNSupported2 m1 : 8|24@1+ (1,0) [0|16777215] "" Vector__XXX
 SG_ VrblNmbrOfFldsFldNmber2Repeated m0 : 32|24@1+ (1,0) [0|16777215] "" Vector__XXX
 SG_ FirstPGNSupported m0 : 8|24@1+ (1,0) [0|16777215] "" Vector__XXX
 SG_ GrpFnctnTrnsmtAndReceivePGNList M : 0|8@1+ (1,0) [0|252] "" Vector__XXX

BO_ 2583234046 NavigationRoute_WPInformation: 11 Vector__XXX
 SG_ RouteName : 73|8@1+ (1,0) [0|255] "ASCII" Vector__XXX
 SG_ SpplmntaryRoute_WPDataAvailable : 68|2@1+ (1,0) [0|3] "" Vector__XXX
 SG_ NavigationDirectionInRoute : 64|4@1+ (1,0) [0|15] "" Vector__XXX
 SG_ RouteID : 48|16@1+ (1,0) [0|65532] "" Vector__XXX
 SG_ DatabaseID : 32|16@1+ (1,0) [0|65532] "" Vector__XXX
 SG_ nItems : 16|16@1+ (1,0) [0|65532] "" Vector__XXX
 SG_ StartRPS : 0|16@1+ (1,0) [0|65532] "" Vector__XXX

BO_ 2381907198 NavigationData: 34 Vector__XXX
 SG_ WaypointClosingVelocity : 256|16@1- (0.01,0) [-327.66|327.66] "m/s" Vector__XXX
 SG_ DestinationWptLongitude : 224|32@1- (1E-007,0) [-180|180] "deg" Vector__XXX
 SG_ DestinationWptLatitude : 192|32@1- (1E-007,0) [-90|90] "deg" Vector__XXX
 SG_ DestinationWaypointNumber : 160|32@1+ (1,0) [0|4294967292] "" Vector__XXX
 SG_ OriginWaypointNumber : 128|32@1+ (1,0) [0|4294967292] "" Vector__XXX
 SG_ BearingPosToDestinationWaypoint : 112|16@1+ (0.0001,0) [0|6.28318] "rad" Vector__XXX
 SG_ BaringiginToDestinationWaypoint : 96|16@1+ (0.0001,0) [0|6.28318] "rad" Vector__XXX
 SG_ ETADate : 80|16@1+ (1,0) [0|65532] "day" Vector__XXX
 SG_ ETATime : 48|32@1+ (0.0001,0) [0|86401] "sec" Vector__XXX
 SG_ CalculationType : 46|2@1+ (1,0) [0|3] "" Vector__XXX
 SG_ ArrivalCircleEntered : 44|2@1+ (1,0) [0|3] "" Vector__XXX
 SG_ PerpendicularCrossed : 42|2@1+ (1,0) [0|3] "" Vector__XXX
 SG_ Course_BearingRef : 40|2@1+ (1,0) [0|3] "" Vector__XXX
 SG_ DistanceToDestinationWaypoint : 8|32@1+ (0.01,0) [0|42950000] "m" Vector__XXX
 SG_ SID : 0|8@1+ (1,0) [0|252] "" Vector__XXX

BO_ 2381184766 NMEARqGroupFunction: 15 Vector__XXX
 SG_ NumberOfRqedCmdedParameters m2 : 48|8@1+ (1,0) [0|252] "" Vector__XXX
 SG_ VrblNmbrOfFldsFldNmber6Repeated3 m2 : 44|4@1+ (1,0) [0|15] "" Vector__XXX
 SG_ FirstParameterErrorCode m2 : 40|4@1+ (1,0) [0|15] "" Vector__XXX
 SG_ TransInterval_PriorityErrorCode m2 : 36|4@1+ (1,0) [0|15] "" Vector__XXX
 SG_ RqedCmdedPGNBeingAcknowledged m2 : 12|24@1+ (1,0) [0|16777215] "" Vector__XXX
 SG_ PGNErrorCode m2 : 8|4@1+ (1,0) [0|15] "" Vector__XXX
 SG_ VrblNmbrOfFldsFldNmber6Repeated2 m1 : 56|8@1+ (1,0) [0|252] "" Vector__XXX
 SG_ FeldNumberOfFirstCmdedParameter m1 : 48|8@1+ (1,0) [0|252] "" Vector__XXX
 SG_ NmbrOfPrsOfCmddPrmetersToFollow m1 : 40|8@1+ (1,0) [0|252] "" Vector__XXX
 SG_ PrioritySetting m1 : 32|4@1+ (1,0) [0|15] "" Vector__XXX
 SG_ CmdedPGN m1 : 8|24@1+ (1,0) [0|16777215] "" Vector__XXX
 SG_ VrblNmbrOfFldsFldNmber6Repeated m0 : 96|8@1+ (1,0) [0|252] "" Vector__XXX
 SG_ FieldNumberOfFirstRqedParameter m0 : 88|8@1+ (1,0) [0|252] "" Vector__XXX
 SG_ NmbrOfPrsOfRqParametersToFollow m0 : 80|8@1+ (1,0) [0|252] "" Vector__XXX
 SG_ TransIntervalOffset m0 : 64|16@1+ (0.01,0) [0|655.32] "sec" Vector__XXX
 SG_ TransInterval m0 : 32|32@1+ (0.001,0) [0|4295000] "sec" Vector__XXX
 SG_ RqedPGN m0 : 8|24@1+ (1,0) [0|16777215] "" Vector__XXX
 SG_ GroupFunctionRq_Cmd_Acknowledge M : 0|8@1+ (1,0) [0|252] "" Vector__XXX

BO_ 2583500030 MooredBuoyStationData: 35 Vector__XXX
 SG_ StationIDString : 272|8@1+ (1,0) [0|255] "ASCII" Vector__XXX
 SG_ WaterTemp : 256|16@1+ (0.01,0) [0|655.32] "°K" Vector__XXX
 SG_ AirTemp : 240|16@1+ (0.01,0) [0|655.32] "°K" Vector__XXX
 SG_ PressTendencyRate : 224|16@1- (10,0) [-327640|327640] "Pa/hr" Vector__XXX
 SG_ AtmosphericPress : 208|16@1+ (100,0) [0|6553200] "Pa" Vector__XXX
 SG_ DominateWavePeriod : 192|16@1+ (0.01,0) [0|655.32] "sec" Vector__XXX
 SG_ WaveHeight : 176|16@1+ (0.01,0) [0|655.32] "m" Vector__XXX
 SG_ WindGusts : 160|16@1+ (0.01,0) [0|655.32] "m/s" Vector__XXX
 SG_ WindReference : 152|3@1+ (1,0) [0|7] "" Vector__XXX
 SG_ WindDirection : 136|16@1+ (0.0001,0) [0|6.28318] "rad" Vector__XXX
 SG_ WindSpeed : 120|16@1+ (0.01,0) [0|655.32] "m/s" Vector__XXX
 SG_ StationLocationLongitude : 88|32@1- (1E-007,0) [-180|180] "deg" Vector__XXX
 SG_ StationLocationLatitude : 56|32@1- (1E-007,0) [-90|90] "deg" Vector__XXX
 SG_ MeasurementTime : 24|32@1+ (0.0001,0) [0|86401] "sec" Vector__XXX
 SG_ MeasurementDate : 8|16@1+ (1,0) [0|65532] "day" Vector__XXX
 SG_ Mode : 0|4@1+ (1,0) [0|15] "" Vector__XXX

BO_ 2583499774 MeteorologicalStationData: 27 Vector__XXX
 SG_ StationIDString : 203|8@1+ (1,0) [0|255] "ASCII" Vector__XXX
 SG_ AirTemp : 187|16@1+ (0.01,0) [0|655.32] "°K" Vector__XXX
 SG_ AtmosphericPress : 171|16@1+ (100,0) [0|6553200] "Pa" Vector__XXX
 SG_ WindGusts : 155|16@1+ (0.01,0) [0|655.32] "m/s" Vector__XXX
 SG_ WindReference : 152|3@1+ (1,0) [0|7] "" Vector__XXX
 SG_ WindDirection : 136|16@1+ (0.0001,0) [0|6.28318] "rad" Vector__XXX
 SG_ WindSpeed : 120|16@1+ (0.01,0) [0|655.32] "m/s" Vector__XXX
 SG_ StationLocationLongitude : 88|32@1- (1E-007,0) [-180|180] "deg" Vector__XXX
 SG_ StationLocationLatitude : 56|32@1- (1E-007,0) [-90|90] "deg" Vector__XXX
 SG_ MeasurementTime : 24|32@1+ (0.0001,0) [0|86401] "sec" Vector__XXX
 SG_ MeasurementDate : 8|16@1+ (1,0) [0|65532] "day" Vector__XXX
 SG_ Mode : 0|4@1+ (1,0) [0|15] "" Vector__XXX

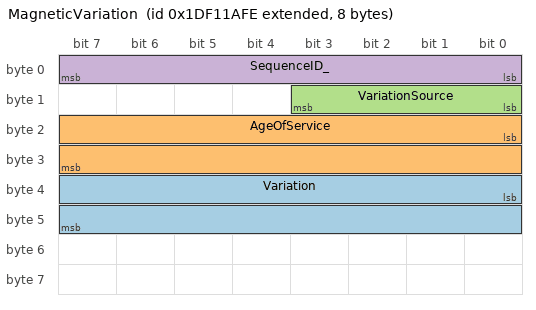
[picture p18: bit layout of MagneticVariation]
BO_ 2649823998 MagneticVariation: 8 Vector__XXX
 SG_ Variation : 32|16@1- (0.0001,0) [-3.14159|3.14159] "rad" Vector__XXX
 SG_ AgeOfService : 16|16@1+ (1,0) [0|65532] "day" Vector__XXX
 SG_ VariationSource : 8|4@1+ (1,0) [0|15] "" Vector__XXX
 SG_ SequenceID_ : 0|8@1+ (1,0) [0|252] "" Vector__XXX

BO_ 2382103806 LoranCTDData: 32 Vector__XXX
 SG_ Mode : 248|4@1+ (1,0) [0|15] "" Vector__XXX
 SG_ StationStatusZ : 244|4@1+ (1,0) [0|15] "" Vector__XXX
 SG_ StationStatusY : 240|4@1+ (1,0) [0|15] "" Vector__XXX
 SG_ StationStatusX : 236|4@1+ (1,0) [0|15] "" Vector__XXX
 SG_ StationStatusW : 232|4@1+ (1,0) [0|15] "" Vector__XXX
 SG_ StationStatusV : 228|4@1+ (1,0) [0|15] "" Vector__XXX
 SG_ StationStatusMaster : 224|4@1+ (1,0) [0|15] "" Vector__XXX
 SG_ ZSecondTD : 192|32@1- (1E-009,0) [-2.14|2.14] "sec" Vector__XXX
 SG_ YSecondTD : 160|32@1- (1E-009,0) [-2.14|2.14] "sec" Vector__XXX
 SG_ XSecondTD : 128|32@1- (1E-009,0) [-2.14|2.14] "sec" Vector__XXX
 SG_ WSecondTD : 96|32@1- (1E-009,0) [-2.14|2.14] "sec" Vector__XXX
 SG_ VSecondTD : 64|32@1- (1E-009,0) [-2.14|2.14] "sec" Vector__XXX
 SG_ MasterRange : 32|32@1- (1E-009,0) [-2.14|2.14] "sec" Vector__XXX
 SG_ GroupRepetitionInterval : 0|32@1- (1E-009,0) [-2.14|2.14] "sec" Vector__XXX

BO_ 2382104318 LoranCSignalData: 8 Vector__XXX
 SG_ StationIdentifier : 32|8@1+ (1,0) [0|255] "ASCII" Vector__XXX
 SG_ GroupRepetitionInterval : 0|32@1- (1E-009,0) [-2.14|2.14] "sec" Vector__XXX

BO_ 2382104062 LoranCRangeData: 32 Vector__XXX
 SG_ Mode : 248|4@1+ (1,0) [0|15] "" Vector__XXX
 SG_ StationStatusZ : 244|4@1+ (1,0) [0|15] "" Vector__XXX
 SG_ StationStatusY : 240|4@1+ (1,0) [0|15] "" Vector__XXX
 SG_ StationStatusX : 236|4@1+ (1,0) [0|15] "" Vector__XXX
 SG_ StationStatusW : 232|4@1+ (1,0) [0|15] "" Vector__XXX
 SG_ StationStatusV : 228|4@1+ (1,0) [0|15] "" Vector__XXX
 SG_ StationStatusMaster : 224|4@1+ (1,0) [0|15] "" Vector__XXX
 SG_ ZSecondRange : 192|32@1- (1E-009,0) [-2.14|2.14] "sec" Vector__XXX
 SG_ YSecondRange : 160|32@1- (1E-009,0) [-2.14|2.14] "sec" Vector__XXX
 SG_ XSecondRange : 128|32@1- (1E-009,0) [-2.14|2.14] "sec" Vector__XXX
 SG_ WSecondRange : 96|32@1- (1E-009,0) [-2.14|2.14] "sec" Vector__XXX
 SG_ VSecondRange : 64|32@1- (1E-009,0) [-2.14|2.14] "sec" Vector__XXX
 SG_ MasterRange : 32|32@1- (1E-009,0) [-2.14|2.14] "sec" Vector__XXX
 SG_ GroupRepetitionInterval : 0|32@1- (1E-009,0) [-2.14|2.14] "sec" Vector__XXX

BO_ 2314274302 Heading_TrackCtrl: 21 Vector__XXX
 SG_ VesselHeading : 152|16@1+ (0.0001,0) [0|6.28318] "rad" Vector__XXX
 SG_ OffTrackLimit : 136|16@1- (1,0) [-32764|32764] "m" Vector__XXX
 SG_ RateOfTurnder : 120|16@1- (1,0) [-1|1] "rad/s" Vector__XXX
 SG_ RadiusOfTurnder : 104|16@1- (1,0) [-32764|32764] "m" Vector__XXX
 SG_ OffHeadingLimit : 88|16@1+ (0.0001,0) [0|6.28318] "rad" Vector__XXX
 SG_ RudderLimit : 72|16@1+ (0.0001,0) [0|6.28318] "rad" Vector__XXX
 SG_ Track : 56|16@1+ (0.0001,0) [0|6.28318] "rad" Vector__XXX
 SG_ HeadingToSteer : 40|16@1+ (0.0001,0) [0|6.28318] "rad" Vector__XXX
 SG_ CmdedRudderAngle : 24|16@1- (0.0001,0) [-3.14159|3.14159] "rad" Vector__XXX
 SG_ CmdedRudderDirection : 21|3@1+ (1,0) [0|7] "" Vector__XXX
 SG_ HeadingReference : 14|2@1+ (1,0) [0|3] "" Vector__XXX
 SG_ TurnMode : 11|3@1+ (1,0) [0|7] "" Vector__XXX
 SG_ SteerMode : 8|3@1+ (1,0) [0|7] "" Vector__XXX
 SG_ Override : 6|2@1+ (1,0) [0|3] "" Vector__XXX
 SG_ OffTrackLimitExceeded : 4|2@1+ (1,0) [0|3] "" Vector__XXX
 SG_ OffHeadingLimitExceeded : 2|2@1+ (1,0) [0|3] "" Vector__XXX
 SG_ RudderLimitExceeded : 0|2@1+ (1,0) [0|3] "" Vector__XXX

BO_ 2583299582 GPSAlmanacData: 26 Vector__XXX
 SG_ ClockParameter2 : 195|11@1+ (1,0) [0|2047] "" Vector__XXX
 SG_ ClockParameter1 : 184|11@1+ (1,0) [0|2047] "" Vector__XXX
 SG_ MeanAnomaly : 160|24@1+ (1,0) [0|16777215] "" Vector__XXX
 SG_ LongitudeOfAscensionNode : 136|24@1+ (1,0) [0|16777215] "" Vector__XXX
 SG_ ArgumentOfPerigee : 112|24@1+ (1,0) [0|16777215] "" Vector__XXX
 SG_ RootOfSemimajorAxis : 88|24@1+ (1,0) [0|16777215] "" Vector__XXX
 SG_ RateOfRightAscension : 72|16@1+ (1,0) [0|65535] "" Vector__XXX
 SG_ InclinationAngle : 56|16@1+ (1,0) [0|65535] "" Vector__XXX
 SG_ AlmanacReferenceTime : 48|8@1+ (1,0) [0|255] "" Vector__XXX
 SG_ Eccentricity : 32|16@1+ (1,0) [0|65535] "" Vector__XXX
 SG_ SVHealthBits : 24|8@1+ (1,0) [0|255] "" Vector__XXX
 SG_ GPSWeekNumber : 8|16@1+ (1,0) [0|65532] "" Vector__XXX
 SG_ PRN : 0|8@1+ (1,0) [0|252] "" Vector__XXX

CM_ BO_ 2349596414 "Advanced Emergency Braking System message 2.";
CM_ SG_ 2349596414 AEBS2MessageChecksum "Used to check the message checksum of the transmitting (HMI) unit within the AEBS2 system.";
CM_ SG_ 2349596414 AEBS2MessageCounter "The message counter is increased with every transmitted AEBS2 message.  After reaching a value of 0xF the next value ...";
CM_ SG_ 2349596414 DrvrActvtnDmndFrAdvncdEmrgncyBrk "According to the Vienna world convetion on road traffic the driver must be provided with means to deactivate an ...";
CM_ SG_ 2566767358 FuelType "Type of fuel currently being utilized by the vehicle ...";
CM_ SG_ 2566767358 EngFuelMassFlowRate "Mass of fuel consumed by engine per unit of time.";
CM_ SG_ 2566767358 EngExhstGsRcrcltn1Valve2PosError "The position error of the Exhaust Gas Recirculation 1 valve 2, determined as the actual position (SPN 3821) minus the ...";
CM_ SG_ 2566767358 EngExhstGsRcrcltn1Valve1PosError "The position error of the Exhaust Gas Recirculation 1 valve, determined as the actual position (SPN 2791) minus the ...";
CM_ BO_ 2566706686 "Contains information on Diesel Exhaust Fluid Pumps ...";
CM_ SG_ 2566706686 Aftrtrtmnt1DslExhstFldPumpHeater "Percentage of heating applied to the aftertreatment 1 diesel exhaust fluid pump heater. A value of 0% means no heating ...";
CM_ SG_ 2566705406 Aftertreatment2ParticulateSensor "The particulate sensor measures the mass concentration of particulate matter in the exhaust downstream of the DPF in ...";
CM_ SG_ 2566705406 Aftertreatment1ParticulateSensor "The particulate sensor measures the mass concentration of particulate matter in the exhaust downstream of the DPF in ...";
CM_ BO_ 2566705150 "Request to initiate the self-diagnosis of the NOx sensors implemented in the system.";
CM_ SG_ 2566705150 NOxSnsorATI2SelfdiagnosisTrigger "Signal to trigger the self-diagnosis of NOx sensor ATI2 ...";
CM_ SG_ 2566705150 NOxSnsorATO2SelfdiagnosisTrigger "Signal to trigger the self-diagnosis of NOx sensor ATO2 ...";
CM_ SG_ 2566705150 NOxSnsorATI1SelfdiagnosisTrigger "Signal to trigger the self-diagnosis of NOx sensor ATI1 ...";
CM_ SG_ 2566705150 NOxSnsorATO1SelfdiagnosisTrigger "Signal to trigger the self-diagnosis of NOx sensor ATO1 ...";
CM_ BO_ 2566704382 "Engine Related Parameters ...";
CM_ SG_ 2566704382 Aftrtrtmnt2OtltGsSnsrPowerSupply "State signal which indicates when the Aftertreatment 2 Outlet Gas Sensor driver output is being driven.  On means the ...";
CM_ SG_ 2566704382 Aftrtrtmnt2IntkGsSnsrPowerSupply "State signal which indicates when the Aftertreatment 2 Intake Gas Sensor driver output is being driven.  On means the ...";
CM_ SG_ 2566704382 Aftrtrtmnt1OtltGsSnsrPowerSupply "State signal which indicates when the Aftertreatment 1 Outlet Gas Sensor driver output is being driven.  On means the ...";
CM_ SG_ 2566704382 Aftrtrtmnt1IntkGsSnsrPowerSupply "State signal which indicates when the Aftertreatment 1 Intake Gas Sensor driver output is being driven.  On means the ...";
CM_ BO_ 2566704126 "Engine Exhaust Gas Recirculation 1 Actuator related parameters ...";
CM_ SG_ 2566704126 EngExhstGsRcrcltn1Acttr2PrlmnryF "Used to identify the applicable J1939-73 FMI detected in the Engine Exhaust Gas Recirculation 1 Actuator 2 by the ...";
CM_ SG_ 2566704126 EngExhstGsRcrcltn1Acttr2OprtnStt "Used to identify the status of Exhaust Gas Recirculation 1 Actuator 2 ...";
CM_ SG_ 2566704126 EngExhstGsRcrcltn1Acttr1OprtnStt "Used to identify the status of Exhaust Gas Recirculation 1 Actuator 1 ...";
CM_ SG_ 2566704126 EngExhstGsRcrcltn1Acttr2DsredPos "The requested position of the Engine Exhaust Gas Recirculation 1 Actuator 2 by the engine ECU, where 0% represents ...";
CM_ SG_ 2566704126 EngExhstGsRcrclton1Actuator2Temp "Temperature of the Engine Exhaust Gas Recirculation 1 Actuator 2 drive circuitry.  Temperature excursions may affect ...";
CM_ SG_ 2566704126 EngExhstGsRcrcltn1Acttr2TmpSttus "Used to identify the status of the Engine Exhaust Gas Recirculation 1 Actuator 2 drive circuitry temperature.  Temperature ...";
CM_ SG_ 2566704126 EngExhstGsRcrcltn1Acttr1DsredPos "The requested position of the Engine Exhaust Gas Recirculation 1 Actuator 1 by the engine ECU, where 0% represents ...";
CM_ SG_ 2566704126 EngExhstGsRcrclton1Actuator1Temp "Temperature of the Engine Exhaust Gas Recirculation 1 Actuator 1 drive circuitry.  Temperature excursions may affect ...";
CM_ SG_ 2566704126 EngExhstGsRcrcltn1Acttr1TmpSttus "Used to identify the status of the Engine Exhaust Gas Recirculation 1 Actuator 1 drive circuitry temperature.  Temperature ...";
CM_ SG_ 2566704126 EngExhstGsRcrcltn1Acttr1PrlmnryF "Used to identify the applicable J1939-73 FMI detected in the Engine Exhaust Gas Recirculation 1 Actuator 1 by the ...";
CM_ BO_ 2566703870 "Engine Exhaust Gas Recirculation 2 Actuator related parameters ...";
CM_ SG_ 2566703870 EngExhstGsRcrcltn2Acttr2OprtnStt "Used to identify the status of Exhaust Gas Recirculation 2 Actuator 2 ...";
CM_ SG_ 2566703870 EngExhstGsRcrcltn2Acttr1OprtnStt "Used to identify the status of Exhaust Gas Recirculation 2 Actuator 1 ...";
CM_ SG_ 2566703870 EngExhstGsRcrcltn2Acttr2DsredPos "The requested position of the Engine Exhaust Gas Recirculation 2 Actuator 2 by the engine ECU, where 0% represents ...";
CM_ SG_ 2566703870 EngExhstGsRcrclton2Actuator2Temp "Temperature of the Engine Exhaust Gas Recirculation 2 Actuator 2 drive circuitry.  Temperature excursions may affect ...";
CM_ SG_ 2566703870 EngExhstGsRcrcltn2Acttr2TmpSttus "Used to identify the status of the Engine Exhaust Gas Recirculation 2 Actuator 2 drive circuitry temperature.  Temperature ...";
CM_ SG_ 2566703870 EngExhstGsRcrcltn2Acttr2PrlmnryF "Used to identify the applicable J1939-73 FMI detected in the Engine Exhaust Gas Recirculation 2 Actuator 2 by the ...";
CM_ SG_ 2566703870 EngExhstGsRcrcltn2Acttr1DsredPos "The requested position of the Engine Exhaust Gas Recirculation 2 Actuator 1 by the engine ECU, where 0% represents ...";
CM_ SG_ 2566703870 EngExhstGsRcrclton2Actuator1Temp "Temperature of the Engine Exhaust Gas Recirculation 2 Actuator 1 drive circuitry.  Temperature excursions may affect ...";
CM_ SG_ 2566703870 EngExhstGsRcrcltn2Acttr1TmpSttus "Used to identify the status of the Engine Exhaust Gas Recirculation 2 Actuator 1 drive circuitry temperature.  Temperature ...";
CM_ SG_ 2566703870 EngExhstGsRcrcltn2Acttr1PrlmnryF "Used to identify the applicable J1939-73 FMI detected in the Engine Exhaust Gas Recirculation 2 Actuator 1 by the ...";
CM_ BO_ 2566703614 "This PGN will be used to transmit the Feedback information from the Engine Throttle and Fuel Actuator.";
CM_ SG_ 2566703614 EngTurboWastegateActuator2Temp "Temperature of the Engine Turbocharger Wastegate Actuator 2 drive circuitry.  Temperature excursions may affect the ...";
CM_ SG_ 2566703614 EngFuelValve2Temp "Temperature of the Engine Fuel Valve 2 drive circuitry. Temperature excursions may affect the torque output.";
CM_ SG_ 2566703614 EngFuelValve1Temp "Temperature of the Engine Fuel Valve 1 drive circuitry. Temperature excursions may affect the torque output.";
CM_ SG_ 2566703614 EngThrottleValve2Temp "Temperature of the Engine Throttle Valve 2 drive circuitry.  Temperature excursions may affect the torque output.";
CM_ SG_ 2566703614 EngThrottleValve1Temp "Temperature of the Engine Throttle Valve 1 drive circuitry.  Temperature excursions may affect the torque output.";
CM_ SG_ 2566703358 EngFuelingInhibitPreventedReason "If Engine Fueling Inhibit Allowed (SPN 5795) indicates that the engine will not inhibit fueling, then this parameter will ...";
CM_ SG_ 2566703358 EngFuelingInhibitAllowed "This parameter is broadcast by the engine control system, and indicates to other devices on the network whether or not it ...";
CM_ SG_ 2566703358 FeedbackEngFuelingState "This parameter provides feedback to the network that SPN 5793 Desired Engine Fueling State was honored.";
CM_ BO_ 2566702590 "This message contains SCR catalyst gas temperature information for aftertreatment system 1 (or bank 1).";
CM_ SG_ 2566702590 Aftrtrtmnt1SCRIntrmdtGsTmpPrlmnr "Used to identify the applicable J1939-73 FMI detected in the aftertreatment SCR intermediate gas temperature sensor by ...";
CM_ SG_ 2566702590 Aftrtrtmnt1SCRIntrmediateGasTemp "Temperature of engine combustion byproducts at an intermediate point in the SCR component in exhaust bank 1.";
CM_ BO_ 2566702334 "This message contains SCR catalyst gas temperature information for aftertreatment system 2 (or bank 2).";
CM_ SG_ 2566702334 Aftrtrtmnt2SCRIntrmdtGsTmpPrlmnr "Used to identify the applicable J1939-73 FMI detected in the aftertreatment SCR intermediate gas temperature sensor by ...";
CM_ SG_ 2566702334 Aftrtrtmnt2SCRIntrmediateGasTemp "Temperature of engine combustion byproducts at an intermediate point in the SCR component in exhaust bank 2.";
CM_ BO_ 2566702078 "Gaseous fuel information 4 ...";
CM_ SG_ 2566702078 SupplyGasMethanePercentage "The percentage of methane in the gas supplied to the engine.";
CM_ BO_ 2566701822 "Status information of a hybrid system.";
CM_ SG_ 2566701822 HybridSystemStopIndicator "Signal from a hybrid system indicating that some aspect of its operation is not functioning correctly, and as a result, the ...";
CM_ SG_ 2566701822 HybridSystemOverheatIndicator "Signal from a hybrid system indicating that at least one of its monitored temperatures is above normal acceptable limits, ...";
CM_ SG_ 2566701822 HybridSystemWarningIndicator "Signal from a hybrid system indicating that some aspect of its operation is not functioning correctly, and as a result, hybrid ...";
CM_ BO_ 2431661310 "This message contains aftertreatment outlet ammonia information for aftertreatment system 2 (or bank 2).";
CM_ SG_ 2431661310 Aftrtrtmnt2SCRIntrmdtNH3GsSn5861 "Indicates the heater status in the warm-up process. Upon receiving a power-up command, the NH3 gas sensor ramps up ...";
CM_ SG_ 2431661310 Aftrtrtmnt2SCRIntrmdtNH3GsSnsrHt "Used to identify the applicable J1939-73 FMI detected in the heater of the SCR intermediate NH3 exhaust gas sensor by ...";
CM_ SG_ 2431661310 Aftrtrtmnt2SCRIntrmdtNH3GsSnsrAt "Indicates that the heater element of the aftertreatment SCR intermediate NH3 gas sensor is within the manufacturer’s ...";
CM_ SG_ 2431661310 Aftrtrtmnt2SCRIntrmdtNH3GsSnsrPw "Indicates that the power supplied to the aftertreatment SCR intermediate NH3 gas sensor is within the manufacturer’s ...";
CM_ SG_ 2431661310 Aftrtrtmnt2SCRIntrmdtNH3RdngStbl "Indicates that the NH3 reading of the aftertreatment SCR intermediate NH3 sensor is stable as determined by the ...";
CM_ SG_ 2431661310 Aftrtrtmnt2SCRIntrmdtNH3SnsrPrlm "Used to identify the applicable J1939-73 FMI detected in the aftertreatment SCR intermediate NH3 sensor by the ...";
CM_ SG_ 2431661310 Aftrtreatment2SCRIntermediateNH3 "The amount of NH3 in the exhaust exiting the aftertreatment system measured by a NH3 sensor at an intermediate point ...";
CM_ BO_ 2431661054 "This message contains aftertreatment outlet ammonia information for aftertreatment system 1 (or bank 1).";
CM_ SG_ 2431661054 Aftrtrtmnt1SCRIntrmdtNH3GsSn5854 "Indicates the heater status in the warm-up process. Upon receiving a power-up command, the NH3 gas sensor ramps up ...";
CM_ SG_ 2431661054 Aftrtrtmnt1SCRIntrmdtNH3GsSnsrHt "Used to identify the applicable J1939-73 FMI detected in the heater of the outlet NH3 exhaust gas sensor by the ...";
CM_ SG_ 2431661054 Aftrtrtmnt1SCRIntrmdtNH3GsSnsrAt "Indicates that the heater element of the aftertreatment SCR intermediate NH3 gas sensor is within the manufacturer’s ...";
CM_ SG_ 2431661054 Aftrtrtmnt1SCRIntrmdtNH3GsSnsrPw "Indicates that the power supplied to the aftertreatment SCR intermediate NH3 gas sensor is within the manufacturer’s ...";
CM_ SG_ 2431661054 Aftrtrtmnt1SCRIntrmdtNH3RdngStbl "Indicates that the NH3 reading of the aftertreatment SCR intermediate NH3 sensor is stable as determined by the ...";
CM_ SG_ 2431661054 Aftrtrtmnt1SCRIntrmdtNH3SnsrPrlm "Used to identify the applicable J1939-73 FMI detected in the aftertreatment SCR intermediate NH3 sensor by the ...";
CM_ SG_ 2431661054 Aftrtreatment1SCRIntermediateNH3 "The amount of NH3 in the exhaust aftertreatment system measured by a NH3 sensor at an intermediate point in the SCR ...";
CM_ BO_ 2230334206 "The Linear Displacement Sensor is an electromechanical sensor that detects the distance of an object from the body of ...";
CM_ SG_ 2230334206 LnrDsplcmntSnsrSnsrFigureOfMerit "Figure of Merit sensor status of Linear Displacement Sensor.";
CM_ SG_ 2230334206 MeasuredLinearDisplacement "Distance to target as measured by the Linear Displacement Sensor.";
CM_ BO_ 2230333950 "The wand sensor is an electromechanical sensor that detects the angle of deflection of a wand.";
CM_ SG_ 2230333950 WandSensorFigureOfMerit "Figure of Merit sensor status for a wand sensor.";
CM_ SG_ 2230333950 WandAngle "A wand sensor measures the angle of deflection of a wand from its null position. This parameter reports the measured ...";
CM_ BO_ 2364551422 "Carries commands received by the wireless transceiver from an off-board transmitter and conveys ...";
CM_ SG_ 2364551422 WirelessSignalStrength "The absolute received signal strength of the signal received from the off-board transmitter. The signal strength is reported ...";
CM_ SG_ 2364551422 TransmitterID "The ID of the off-board transmitter that sent the incoming message received by the wireless transceiver.";
CM_ SG_ 2364551422 TransmitterCmdState "The command contained in the signal received by the wireless transceiver from an off-board transmitter.";
CM_ SG_ 2364551422 WirelessRollingMessageCounter "A counter incremented with each instance of the Wireless Status message. The counter shall increment from 0 to 64255, ...";
CM_ BO_ 2364551166 "Advanced Emergency Braking System message 1.";
CM_ SG_ 2364551166 TmeToCollisionWithRelevantObject "The time to collision is the duration after which the predicted travelling paths of host vehicle and relevant object lead to a ...";
CM_ SG_ 2364551166 BndOffPrbabilityOfRelevantObject "Probabilty if monitored relevant object might start a turning maneuver, which could clear the travelling path of the host ...";
CM_ SG_ 2364551166 RlvntObjctDtctdFrAdvncdEmrgncyBr "Indication if the advanced emergency braking system (AEBS) is monitoring a relevant object ...";
CM_ SG_ 2364551166 CollisionWarningStatus "To implement different HMI (human machine interface) concepts, e.g. visual only, visual/audible, different warning tones ...";
CM_ SG_ 2364551166 AdvncdEmrgencyBrakingSystemState "Current operational state of advanced emergency braking system ...";
CM_ BO_ 2566730238 "This parameter group transfers status and measured information for a second engine coolant fan.  For systems with a ...";
CM_ SG_ 2566730238 Fan2DriveBypassCmdStatus "Status of the Fan Drive Bypass Command for the second fan as being commanded by the ECU.  The fan drive bypass ...";
CM_ SG_ 2566730238 HydFan2MotorPress "The hydraulic pressure used to drive the second fan system, sensed before the hydraulic fan motor.";
CM_ SG_ 2566730238 Fan2Speed "The speed of the second fan associated with engine coolant system.";
CM_ SG_ 2566730238 Fan2DriveState "This parameter is used to indicate the current state or mode of operation by the second fan drive.";
CM_ SG_ 2566730238 EstPercentFan2Speed "Estimated fan speed as a ratio of the fan drive (current speed) to the fully engaged fan drive (maximum fan speed).  A two ...";
CM_ BO_ 2566711038 "Reports vehicle/chassis lubrication systems status ...";
CM_ SG_ 2566711038 LubricationTimingCycleStatus "Reports the status of the lubrication activation clock.";
CM_ SG_ 2566711038 LubricationReservoirLevel "Reports the status of the lubrication system reservior level.  The lubrication reservoir stores the grease for the lubrication ...";
CM_ SG_ 2566711038 LubricationPumpEnableStatus "Reports the operational status of the lubrication system pump.  In the disabled state, the lubrication pump will not run a ...";
CM_ SG_ 2566711038 LubricationOperationModeStatus "Reports the current operational mode status of the lubrication system.";
CM_ SG_ 2566711038 LubricationCycleModeStatus "Reports the current lubrication cycle mode of the lubrication system ...";
CM_ SG_ 2566711038 LubricationCycleModeLockStatus "Reports status of the ability to change the lubrication cycle mode.  Locking the lubrication mode would prevent the ...";
CM_ BO_ 2566710782 "Hydraulic Oil Properties.  This hydraulic fluid is for the entire hydraulics system of a piece of equipment.";
CM_ SG_ 2566710782 HydOilTemp "Hydraulic Oil Temperature.  This hydraulic fluid is for the entire hydraulics system of a piece of equipment.";
CM_ SG_ 2566710782 HydOilRelativeDielectricity "Hydraulic oil relative dielectricity used to describe the hydraulic oil quality.  This hydraulic fluid is for the entire hydraulics ...";
CM_ SG_ 2566710782 HydOilDensity "Density of hydraulic oil.  This hydraulic fluid is for the entire hydraulics system of a piece of equipment.";
CM_ SG_ 2566710782 HydOilDynamicViscosity "Dynamic viscosity of hydraulic oil.  This hydraulic fluid is for the entire hydraulics system of a piece of equipment.";
CM_ BO_ 2566710526 "Engine Fuel Properties ...";
CM_ SG_ 2566710526 EngFuelTemp "Engine Fuel Temperature.  See also SPNs 174 or 3468 for alternate resolution.";
CM_ SG_ 2566710526 EngFuelDielectricity "Engine fuel relative dielectricity.";
CM_ SG_ 2566710526 EngFuelDensity "Density of engine fuel ...";
CM_ SG_ 2566710526 EngFuelDynamicViscosity "Dynamic viscosity of engine fuel ...";
CM_ BO_ 2432492542 "Contains information about the engine exhaust brake system control.";
CM_ SG_ 2432492542 DsredEngTurbo2TurbineOutletPress "The desired gage pressure of the combustion by-products exiting the turbine side of the turbocharger 5 at the current ...";
CM_ SG_ 2432492542 EngTurbo2TurbineOutletPress "Gage pressure of the combustion by-products exiting the turbine side of the turbocharger 2.";
CM_ SG_ 2432492542 EngExhaustBrakeActuatorCmd "The control command applied to the engine exhaust brake actuator, where 0% represents no braking and 100% ...";
CM_ SG_ 2432492542 DsredEngTurbo1TurbineOutletPress "The desired gage pressure of the combustion by-products exiting the turbine side of the turbocharger 1 at the current ...";
CM_ SG_ 2432492542 EngTurbo1TurbineOutletPress "Gage pressure of the combustion by-products exiting the turbine side of the turbocharger 1.";
CM_ BO_ 2566710014 "The status of Supplemental Fan. This is a supplemental fan used for additional cooling beyond that of the primary cooling ...";
CM_ SG_ 2566710014 SupplementalFanPower "Estimated Power output of Supplemental Fan ...";
CM_ SG_ 2566710014 SupplementalFanCurrent "Measured electrical current of supplemental fan drive.";
CM_ SG_ 2566710014 SupplementalFanSpeed "Measured speed of supplemental fan.";
CM_ SG_ 2566710014 SupplementalFanCtrlECUTemp "Measured temperature of Supplemental Fan Controller ECU.";
CM_ SG_ 2566710014 SupplementalFanDriveStatus "The drive status of the Supplemental Fan. This status parameter indicates the overall health of the fan drive. It will ...";
CM_ SG_ 2566710014 SupplementalFanCtrlTempStatus "Internal Controller Temperature Status of Supplemental Fan.";
CM_ SG_ 2566710014 SupplementalFanVelocityStatus "Status of the rotational velocity of Supplemental Fan. Used to indicate if the fan is spinning at the desired speed. If fan is ...";
CM_ SG_ 2566710014 SupplementalFanDirectionStatus "Rotational Direction of Supplemental Fan. Fan could be spinning forward or reverse.";
CM_ SG_ 2566710014 SupplementalFanEnableStatus "Enable/Disable Status of Supplemental Fan.";
CM_ SG_ 2566709758 HighResolutionEngFuelRate "Amount of fuel consumed by engine per unit of time.";
CM_ BO_ 2566709502 "The purpose of this PGN is to group parameters about the diesel particulate filter regeneration control.";
CM_ SG_ 2566709502 Aftertreatment2FuelMassRate "Mass rate of total fuel being delivered to Atertreatment 2 for DPF regeneration.";
CM_ SG_ 2566709502 Aftertreatment1FuelMassRate "Mass rate of total fuel being delivered to aftertreatment 1 for DPF regeneration.";
CM_ SG_ 2566709502 RelativeUnburnedFuelMassFromEng "The unburned amount of diesel fuel coming out of the engine. This fuel increases the temperature while oxidated in the ...";
CM_ SG_ 2566709502 Aftrtrtmnt1DslPrtcltFltrIntkTmpS "Set point temperature for the particulate filter (DPF) regeneration at the intake to the DPF for Exhaust bank 1.";
CM_ BO_ 2566709246 "12th PGN which identifies parameters that are either measuring various pressures within the engine or identifying engine ...";
CM_ SG_ 2566709246 EngFuelFilterDegradation "The estimated percentage relative to the useful life of the engine fuel filter.";
CM_ SG_ 2566709246 EngFilteredFuelDeliveryAbsPress "Absolute pressure of fuel in system as delivered from supply pump to the injection pump after the pressure side fuel filter.";
CM_ SG_ 2566709246 EngFilteredFuelDeliveryPress "Gage pressure of fuel in system as delivered from supply pump to the injection pump after the pressure side fuel filter.";
CM_ SG_ 2566709246 EngFuelDeliveryAbsPress "Absolute pressure of fuel in system as delivered from supply pump to the injection pump.  See also SPN 94 for Fuel ...";
CM_ BO_ 2566708990 "This PGN contains information about the Aftertreatment 1 Air Control.";
CM_ SG_ 2566708990 Aftertreatment1SecondAirAbsPress "Absolute pressure of the secondary air for aftertreatment 1. Secondary air is air provided to the exhaust system (per SAE ...";
CM_ BO_ 2566708734 "This PGN contains information about the Aftertreatment 2 Air Control.";
CM_ SG_ 2566708734 Aftertreatment2SecondAirAbsPress "Absolute pressure of the secondary air for aftertreatment 2. Secondary air is air provided to the exhaust system (per SAE ...";
CM_ BO_ 2566708478 "Cruise Control / Vehicle Speed 3 ...";
CM_ SG_ 2566708478 SrcAddrssOfCntrllngDvcFrPsngCrsC "The source address of the SAE J1939 device that is currently sending the Cruise Control Pause Command (SPN 5605).";
CM_ SG_ 2566708478 SrcAddrssOfCntrllngDvcFrDsblngCr "The source address of the SAE J1939 device that is currently sending the Cruise Control Disable Command (SPN 5603).";
CM_ SG_ 2566708478 CruiseCtrlSystemCmdState "Indicates the current state of the cruise control system due to the Cruise Control System Commands, which include ...";
CM_ SG_ 2566708478 AdptiveCruiseCtrlReadinessStatus "This parameter is used to indicate an application's state of readiness for responding to commands from an adaptive ...";
CM_ BO_ 2566708222 "This message is used to specify up to 4 soot sensor analysis frequencies to request the soot sensor signal data ...";
CM_ SG_ 2566708222 Aftrtrtmnt1DslPrtcltFltr1StS5635 "Fourth requested analysis frequency for the diesel particulate filter 1 soot sensor.";
CM_ SG_ 2566708222 Aftrtrtmnt1DslPrtcltFltr1StS5634 "Third requested analysis frequency for the diesel particulate filter 1 soot sensor.";
CM_ SG_ 2566708222 Aftrtrtmnt1DslPrtcltFltr1StS5633 "Second requested analysis frequency for the diesel particulate filter 1 soot sensor.";
CM_ SG_ 2566708222 Aftrtrtmnt1DslPrtcltFltr1StSnsrA "The analysis frequency associated with the frequency 3 soot signal for the diesel particulate filter 1 soot sensor.  See ...";
CM_ BO_ 2566707966 "This message is used report the analysis frequency and associated soot sensor signal data for two of the requested ...";
CM_ SG_ 2566707966 Aftrtrtmnt1DslPrtcltFltr1StS5639 "The soot signal attenuation measurement for analysis frequency 2 for the diesel particulate filter 1 soot sensor.  See SPN ...";
CM_ SG_ 2566707966 Aftrtrtmnt1DslPrtcltFltr1StS5638 "The analysis frequency associated with the frequency 2 soot signal for the diesel particulate filter 1 soot sensor.  See ...";
CM_ SG_ 2566707966 Aftrtrtmnt1DslPrtcltFltr1StSnsrF "The soot signal attenuation measurement for analysis frequency 3 for the diesel particulate filter 1 soot sensor.  See SPN ...";
CM_ SG_ 2566707966 Aftrtrtmnt1DslPrtcltFltr1StSnsrA "The analysis frequency associated with the frequency 3 soot signal for the diesel particulate filter 1 soot sensor.  See ...";
CM_ BO_ 2566707710 "This message is used report the analysis frequency and associated soot sensor signal data for two of the requested ...";
CM_ SG_ 2566707710 Aftrtrtmnt1DslPrtcltFltr1StS5643 "The soot signal attenuation measurement for analysis frequency 4 for the diesel particulate filter 1 soot sensor.  See SPN ...";
CM_ SG_ 2566707710 Aftrtrtmnt1DslPrtcltFltr1StS5642 "The analysis frequency associated with the frequency 4 soot signal for the diesel particulate filter 1 soot sensor.  See ...";
CM_ SG_ 2566707710 Aftrtrtmnt1DslPrtcltFltr1StSnsrF "The soot signal attenuation measurement for analysis frequency 3 for the diesel particulate filter 1 soot sensor.  See SPN ...";
CM_ SG_ 2566707710 Aftrtrtmnt1DslPrtcltFltr1StSnsrA "The analysis frequency associated with the frequency 3 soot signal for the diesel particulate filter 1 soot sensor.  See ...";
CM_ BO_ 2315059966 "Direction and speed of Wind.True wind can be referenced to vessel to ground.Apparent Wind is what is felt standing on the(moving)ship,I.e.,wind measured by typical mast head instruments.
boat referenced true wind is given by vector sum of Apparent wind a";
CM_ SG_ 2315059966 WindReference "0x00 = True (referenced to North)
0x01 = Magnetic
0x02 = Apparent
0x03 = True (boat referenced)
0x04 = Reserved
0x05 = Reserved
0x06 = Error
0x07 = Null";
CM_ SG_ 2315059966 SequenceID_ "An upward counting number used to tie related information together between different PGNs.For example,SID would be used to tie together COG,SOG and RAIM values to a given Pos.255=no valid Pos fix to tie it to.Range 0 to 250 for valid Pos fixes.";
CM_ BO_ 2381646846 "Water depth relative to transducer and offset of measuring transducer.Positive offset numbers provide distance from transducer to waterline.Negative offset numbers provide distance from transducer to part of keel of interest.";
CM_ SG_ 2381646846 Offset "Positive values represent distance from transducer to water line and negative values represent distance from the transducer to the keel.";
CM_ SG_ 2381646846 WaterDepthTransducer "Depth relative to the transducer location.  Range of value specified in 'Maximum Range' field.";
CM_ SG_ 2381646846 SID "An upward counting number used to tie related information together between different PGNs.For example,SID would be used to tie together COG,SOG and RAIM values to a given Pos.255=no valid Pos fix to tie it to.Range 0 to 250 for valid Pos fixes.";
CM_ BO_ 2315129598 "This PGN provides a single Trans that accurately describes speed of a vessel by component vectors.

This information is relevant for large vessels and would typically be provided by a product that interfaces to sensors such as dual axis logs.Products th";
CM_ SG_ 2315129598 SternSpeedGroundreferenced "Positive values represent ahead or starboard transverse speed and negative values represent astern or port transverse speed.";
CM_ SG_ 2315129598 SternSpeedWaterreferenced "Positive values represent ahead or starboard transverse speed and negative values represent astern or port transverse speed.";
CM_ SG_ 2315129598 TransverseSpeedGroundreferenced "Positive values represent ahead or starboard transverse speed and negative values represent astern or port transverse speed.";
CM_ SG_ 2315129598 LngtudinalSpeedGroundreferenced "Positive values represent ahead or starboard transverse speed and negative values represent astern or port transverse speed.";
CM_ SG_ 2315129598 TransverseSpeedWaterreferenced "Positive values represent ahead or starboard transverse speed and negative values represent astern or port transverse speed.";
CM_ SG_ 2315129598 LngitudinalSpeedWaterreferenced "Positive values represent ahead or starboard transverse speed and negative values represent astern or port transverse speed.";
CM_ BO_ 2314277630 "Heading sensor value with a flag for True Magnetic.If sensor value is Magnetic,deviation field can be used to produce a Magnetic heading,and variation field can be used to correct Magnetic heading to produce a True heading.

To obtain Magnetic Heading f";
CM_ SG_ 2314277630 HeadingSensorReference "0 = True, 
1 = Magnetic, 
2 = Error, 
3 = Null";
CM_ SG_ 2314277630 Variation "Positive values are Easterly and negative values are Westerly.";
CM_ SG_ 2314277630 Deviation "Positive values are Easterly and negative values are Westerly.";
CM_ SG_ 2314277630 HeadingSensorReading "Primary output of heading as indicated by the heading sensor.";
CM_ SG_ 2314277630 SID "An upward counting number used to tie related information together between different PGNs.For example,SID would be used to tie together COG,SOG and RAIM values to a given Pos.255=no valid Pos fix to tie it to.Range 0 to 250 for valid Pos fixes.";
CM_ BO_ 2583172606 "Transformation parameters for converting from WGS-84 to other Datums.";
CM_ SG_ 2583172606 DatumName "4-character code for datum currently being output for Pos solution.datum's are defined in IHO Publication S-60,Appendices B and C.first three chars are datum ID as per IHO tables.fourth char is local datum subdivision code.A null char indicates datum subd";
CM_ SG_ 2583172606 EllipsoidFlatteningInverse "Flattening (1/f) of the user Datum ellipsoid.";
CM_ SG_ 2583172606 EllipsoidSemimajorAxis "Semi-major axis (a) of the User Datum ellipsoid.";
CM_ SG_ 2583172606 Scale "Scale factor expressed in parts-per-million";
CM_ SG_ 2583172606 RotationInZ "Rotational shift in X, Y, or Z axis from WGS 84.  Rotations presented use the geodetic sign convention.  When looking along the positive axis towards the origin, counter-clockwise rotations are positive.";
CM_ SG_ 2583172606 RotationInY "Rotational shift in X, Y, or Z axis from WGS 84.  Rotations presented use the geodetic sign convention.  When looking along the positive axis towards the origin, counter-clockwise rotations are positive.";
CM_ SG_ 2583172606 RotationInX "Rotational shift in X, Y, or Z axis from WGS 84.  Rotations presented use the geodetic sign convention.  When looking along the positive axis towards the origin, counter-clockwise rotations are positive.";
CM_ SG_ 2583172606 DeltaZ "Delta Shift in X, Y, or Z axis from WGS 84.";
CM_ SG_ 2583172606 DeltaY "Delta Shift in X, Y, or Z axis from WGS 84.";
CM_ SG_ 2583172606 DeltaX "Delta Shift in X, Y, or Z axis from WGS 84.";
CM_ BO_ 2515667198 "Trip parameters relative to Vessel";
CM_ BO_ 2515667454 "Engine related trip information.";
CM_ SG_ 2515667454 EngInstance "For Engs:
0 = Instance 0;          0 = Single Eng Dual Eng Port
1 = Instance 1;          1 = Dual Eng StarBoard  
                                  (for Multiple Engs,Instances will start 
        thru                            from Bow,Port(0)to Ste";
CM_ BO_ 2314339838 "Used to provide operational state and internal operating parameters of a specific Trans,indicated by Trans instance field.This Msg would normally be broadcasted periodically to provide information for instrumentation Ctrl functions.";
CM_ SG_ 2314339838 TransDiscreteStatus "xxxx xxx1 = Check Tranmission,
xxxx xx1x = Over Temp,
xxxx x1xx = Low Oil Press,
xxxx 1xxx = Low Oil Level,
xxx1 xxxx = Sail Drive,
xx1x xxxx = reserved,
x1xx xxxx = reserved,
1xxx xxxx = reserved,
                    where x = don't care";
CM_ SG_ 2314339838 TransGear "0 = Forward.
1 = Neutral,
2 = Reverse,
3 = [Unavailable, Unknown]";
CM_ SG_ 2314339838 TransInstance "For Engs:
0 = Instance 0;          0 = Single Eng Dual Eng Port
1 = Instance 1;          1 = Dual Eng StarBoard  
                                  (for Multiple Engs,Instances will start 
        thru                            from Bow,Port(0)to Ste";
CM_ BO_ 2314602750 "Message for reporting status and target data from tracking radar external devices.  The reporting interval will vary by the values for target status and quantity of track data files.";
CM_ SG_ 2314602750 Course "Degrees clockwise relative to True North.";
CM_ SG_ 2314602750 Bearing "Degrees clockwise relative to True North.";
CM_ SG_ 2314602750 BearingReference "0 = True, 
1 = Magnetic, 
2 = Error, 
3 = Releative";
CM_ SG_ 2314602750 TrackStatus "xx00 = Cancelled Not Available,
xx01 = Initial Acquisition Target,
xx10 = Tracking Target,
xx11 = Lost Target,
x0xx = Reported Target No,
x1xx = Reported Target Yes,
0xxx = Acquision Manual,
1xxx = Acquision Auto,
                    where x = don";
CM_ SG_ 2314602750 TargetID "Number of route, waypoint, event, mark, etc.";
CM_ SG_ 2314602750 SequenceID_ "An upward counting number used to tie related information together between different PGNs.For example,SID would be used to tie together COG,SOG and RAIM values to a given Pos.255=no valid Pos fix to tie it to.Range 0 to 250 for valid Pos fixes.";
CM_ SG_ 2314602750 Name "Name of place, route, waypoint, destination, vessel, vehicle, etc.";
CM_ SG_ 2314602750 UTCOfFix "24 hour clock, 0 =  midnight,  time is in UTC";
CM_ SG_ 2314602750 TCPA "Time interval in milli-sec.  '-'  = time elapsed since event, '+' = time to go before event.";
CM_ BO_ 2381842942 "This PGN has a single transmission that provides:

- UTC Time
- UTC Date
- Local offset

Products that can maintain or have a method of calculating or manually providing local offset should transmit this PGN.";
CM_ SG_ 2381842942 LocalOffsetMinutes "Local time zone offset in minutes.  Local time zone is added to local time to obtain UTC.  Local zone is generally negative for East longitudes, with local exceptions near the International Date Line.";
CM_ SG_ 2381842942 Time "24 hour clock, 0 =  midnight,  time is in UTC";
CM_ SG_ 2381842942 Date "Days since January 1, 1970,   Date is relative to UTC Time.";
CM_ BO_ 2381911550 "Time to go to elapsed from a generic mark,that may be non-fixed.mark is not generally a specific geographic point but may vary continuously and is most often determined by calculation(recommended turning tacking point for sailing vessels,wheel-over point ";
CM_ SG_ 2381911550 MarkID "Number of route, waypoint, event, mark, etc.";
CM_ SG_ 2381911550 MarkType "0   = Collision, 
  1   = Turning Point, 
  2   = Reference (general), 
  3   = Wheelover, 
  4   = Waypoint, 
5-13 = Reserved, 
 14  = Error, 
 15  = Null";
CM_ SG_ 2381911550 TimeElapsedTogoToMark "Time interval in milli-sec.  '-'  = time elapsed since event, '+' = time to go before event.";
CM_ SG_ 2381911550 SID "An upward counting number used to tie related information together between different PGNs.For example,SID would be used to tie together COG,SOG and RAIM values to a given Pos.255=no valid Pos fix to tie it to.Range 0 to 250 for valid Pos fixes.";
CM_ BO_ 2583499006 "Tide station measurement data including station location, numeric identifier, and name.";
CM_ SG_ 2583499006 StationIDString "Name of place, route, waypoint, destination, vessel, vehicle, etc.";
CM_ SG_ 2583499006 TideLevelStandardDeviation "following text is from NOAA and is placed here to convey an understanding of expected magnitude of values.'tide gage processes 181 water level samples,1 second apart,centered on 6 minute mark.It then computes standard deviation of Samples.Samples more tha";
CM_ SG_ 2583499006 TideLevel "This value is relative to mean lower low water (MLLW).";
CM_ SG_ 2583499006 MeasurementTime "24 hour clock, 0 =  midnight,  time is in UTC";
CM_ SG_ 2583499006 MeasurementDate "Days since January 1, 1970,   Date is relative to UTC Time.";
CM_ SG_ 2583499006 TideTendency "msb/lsb: 
00 = Falling, 
01 = Rising, 
10 = Error, 
11 = Unavailable, Unknown";
CM_ SG_ 2583499006 Mode "Range Residual used in position calculation or range residuals were calculated after the position.  
0=range residuals were used to calculate data; 
1=range residuals were calculated after the position., 
2=Error, 
3=Null";
CM_ BO_ 2381320446 "The purpose of this PGN is twofold:

- To provide a regular transmission of UTC time and date
- To provide synchronism for measurement data";
CM_ SG_ 2381320446 Time "24 hour clock, 0 =  midnight,  time is in UTC";
CM_ SG_ 2381320446 Date "Days since January 1, 1970,   Date is relative to UTC Time.";
CM_ SG_ 2381320446 Source "0x0 = GPS, 
0x1 =GLONASS, 
0x2 = WWV or equivalent Radio Station Time Sync, 
0x3 = Local Cesium clock, 
0x4 = Local Rubidium clock, 
0x5 = Local Crystal clock, 
0x6 - 0xE = reserved, 
0xF = Null";
CM_ SG_ 2381320446 SID "An upward counting number used to tie related information together between different PGNs.For example,SID would be used to tie together COG,SOG and RAIM values to a given Pos.255=no valid Pos fix to tie it to.Range 0 to 250 for valid Pos fixes.";
CM_ BO_ 2381451006 "Universal commands to multiple banks of two-state devices.";
CM_ SG_ 2381451006 Switch28 "00 = [Turn Off, Disable, Reset, Make '0'],
01 = [Turn On, Enable, Set, Make '1'],
02  = Reserved,
03  = No action";
CM_ SG_ 2381451006 Switch27 "00 = [Turn Off, Disable, Reset, Make '0'],
01 = [Turn On, Enable, Set, Make '1'],
02  = Reserved,
03  = No action";
CM_ SG_ 2381451006 Switch26 "00 = [Turn Off, Disable, Reset, Make '0'],
01 = [Turn On, Enable, Set, Make '1'],
02  = Reserved,
03  = No action";
CM_ SG_ 2381451006 Switch25 "00 = [Turn Off, Disable, Reset, Make '0'],
01 = [Turn On, Enable, Set, Make '1'],
02  = Reserved,
03  = No action";
CM_ SG_ 2381451006 Switch24 "00 = [Turn Off, Disable, Reset, Make '0'],
01 = [Turn On, Enable, Set, Make '1'],
02  = Reserved,
03  = No action";
CM_ SG_ 2381451006 Switch23 "00 = [Turn Off, Disable, Reset, Make '0'],
01 = [Turn On, Enable, Set, Make '1'],
02  = Reserved,
03  = No action";
CM_ SG_ 2381451006 Switch22 "00 = [Turn Off, Disable, Reset, Make '0'],
01 = [Turn On, Enable, Set, Make '1'],
02  = Reserved,
03  = No action";
CM_ SG_ 2381451006 Switch21 "00 = [Turn Off, Disable, Reset, Make '0'],
01 = [Turn On, Enable, Set, Make '1'],
02  = Reserved,
03  = No action";
CM_ SG_ 2381451006 Switch20 "00 = [Turn Off, Disable, Reset, Make '0'],
01 = [Turn On, Enable, Set, Make '1'],
02  = Reserved,
03  = No action";
CM_ SG_ 2381451006 Switch19 "00 = [Turn Off, Disable, Reset, Make '0'],
01 = [Turn On, Enable, Set, Make '1'],
02  = Reserved,
03  = No action";
CM_ SG_ 2381451006 Switch18 "00 = [Turn Off, Disable, Reset, Make '0'],
01 = [Turn On, Enable, Set, Make '1'],
02  = Reserved,
03  = No action";
CM_ SG_ 2381451006 Switch17 "00 = [Turn Off, Disable, Reset, Make '0'],
01 = [Turn On, Enable, Set, Make '1'],
02  = Reserved,
03  = No action";
CM_ SG_ 2381451006 Switch16 "00 = [Turn Off, Disable, Reset, Make '0'],
01 = [Turn On, Enable, Set, Make '1'],
02  = Reserved,
03  = No action";
CM_ SG_ 2381451006 Switch15 "00 = [Turn Off, Disable, Reset, Make '0'],
01 = [Turn On, Enable, Set, Make '1'],
02  = Reserved,
03  = No action";
CM_ SG_ 2381451006 Switch14 "00 = [Turn Off, Disable, Reset, Make '0'],
01 = [Turn On, Enable, Set, Make '1'],
02  = Reserved,
03  = No action";
CM_ SG_ 2381451006 Switch13 "00 = [Turn Off, Disable, Reset, Make '0'],
01 = [Turn On, Enable, Set, Make '1'],
02  = Reserved,
03  = No action";
CM_ SG_ 2381451006 Switch12 "00 = [Turn Off, Disable, Reset, Make '0'],
01 = [Turn On, Enable, Set, Make '1'],
02  = Reserved,
03  = No action";
CM_ SG_ 2381451006 Switch11 "00 = [Turn Off, Disable, Reset, Make '0'],
01 = [Turn On, Enable, Set, Make '1'],
02  = Reserved,
03  = No action";
CM_ SG_ 2381451006 Switch10 "00 = [Turn Off, Disable, Reset, Make '0'],
01 = [Turn On, Enable, Set, Make '1'],
02  = Reserved,
03  = No action";
CM_ SG_ 2381451006 Switch9 "00 = [Turn Off, Disable, Reset, Make '0'],
01 = [Turn On, Enable, Set, Make '1'],
02  = Reserved,
03  = No action";
CM_ SG_ 2381451006 Switch8 "00 = [Turn Off, Disable, Reset, Make '0'],
01 = [Turn On, Enable, Set, Make '1'],
02  = Reserved,
03  = No action";
CM_ SG_ 2381451006 Switch7 "00 = [Turn Off, Disable, Reset, Make '0'],
01 = [Turn On, Enable, Set, Make '1'],
02  = Reserved,
03  = No action";
CM_ SG_ 2381451006 Switch6 "00 = [Turn Off, Disable, Reset, Make '0'],
01 = [Turn On, Enable, Set, Make '1'],
02  = Reserved,
03  = No action";
CM_ SG_ 2381451006 Switch5 "00 = [Turn Off, Disable, Reset, Make '0'],
01 = [Turn On, Enable, Set, Make '1'],
02  = Reserved,
03  = No action";
CM_ SG_ 2381451006 Switch4 "00 = [Turn Off, Disable, Reset, Make '0'],
01 = [Turn On, Enable, Set, Make '1'],
02  = Reserved,
03  = No action";
CM_ SG_ 2381451006 Switch3 "00 = [Turn Off, Disable, Reset, Make '0'],
01 = [Turn On, Enable, Set, Make '1'],
02  = Reserved,
03  = No action";
CM_ SG_ 2381451006 Switch2 "00 = [Turn Off, Disable, Reset, Make '0'],
01 = [Turn On, Enable, Set, Make '1'],
02  = Reserved,
03  = No action";
CM_ SG_ 2381451006 Switch1 "00 = [Turn Off, Disable, Reset, Make '0'],
01 = [Turn On, Enable, Set, Make '1'],
02  = Reserved,
03  = No action";
CM_ SG_ 2381451006 SwitchBankInstance "Number of route, waypoint, event, mark, etc.";
CM_ BO_ 2314535934 "The purpose of this PGN is to provide a single transmission that describes the motion of a vessel.";
CM_ SG_ 2314535934 SequenceID_ "An upward counting number used to tie related information together between different PGNs.For example,SID would be used to tie together COG,SOG and RAIM values to a given Pos.255=no valid Pos fix to tie it to.Range 0 to 250 for valid Pos fixes.";
CM_ BO_ 2315129086 "Provides data on various small craft control surfaces and speed through the water. Used primarily by display or instrumentation devices.";
CM_ BO_ 2381908990 "Set and Drift effect on Vessel is direction and speed of  a current.Course&Speed(through water)vector added to Set&Drift vector is COG&SOG vector.bearings may be True Magnetic referenced.
When Set&Drift is calculated from data from a GPS,a compass and a ";
CM_ SG_ 2381908990 Set "Direction towards which current flows.  Degrees relative to True North.";
CM_ SG_ 2381908990 SetReference "0 = True, 
1 = Magnetic, 
2 = Error, 
3 = Null";
CM_ SG_ 2381908990 SID "An upward counting number used to tie related information together between different PGNs.For example,SID would be used to tie together COG,SOG and RAIM values to a given Pos.255=no valid Pos fix to tie it to.Range 0 to 250 for valid Pos fixes.";
CM_ BO_ 2583499262 "Salinity station measurement data including station location, numeric identifier, and name.";
CM_ SG_ 2583499262 StationIDString "Name of place, route, waypoint, destination, vessel, vehicle, etc.";
CM_ SG_ 2583499262 Salinity "The average Salinity of ocean water is about 35 grams of salts per kilogram of sea water (g/kg), usually written as 35 ppt which is read as 35 parts per thousand.";
CM_ SG_ 2583499262 MeasurementTime "24 hour clock, 0 =  midnight,  time is in UTC";
CM_ SG_ 2583499262 MeasurementDate "Days since January 1, 1970,   Date is relative to UTC Time.";
CM_ SG_ 2583499262 Mode "Range Residual used in position calculation or range residuals were calculated after the position.  
0=range residuals were used to calculate data; 
1=range residuals were calculated after the position., 
2=Error, 
3=Null";
CM_ BO_ 2650544894 "Complex Rq of this PGN should return Waypoints of a WP-List.

WARNING:Route Track may not be defined by Waypoint Poss only:Navigation Method(GC/RL)and Radius of Turn at each Waypoint are optional additional parameters defining Track.
PGN 130066 field #";
CM_ SG_ 2650544894 WPName "Name of place, route, waypoint, destination, vessel, vehicle, etc.";
CM_ SG_ 2650544894 WPID "Number of route, waypoint, event, mark, etc.";
CM_ SG_ 2650544894 reserved "Number of route, waypoint, event, mark, etc.";
CM_ SG_ 2650544894 DatabaseID "Number of route, waypoint, event, mark, etc.";
CM_ SG_ 2650544894 NumberOfValidWPsInWPList "Number of route, waypoint, event, mark, etc.";
CM_ SG_ 2650544894 nItems "Number of route, waypoint, event, mark, etc.";
CM_ SG_ 2650544894 StartWPID "Number of route, waypoint, event, mark, etc.";
CM_ BO_ 2650544382 "Complex Rq of this PGN should return supplementary Comments attached to Databases in navigation Device.

Databases without a Comment shall not be included in this PGN.

reply should use same transfer Protcl as Rq.
ISO Rq for this PGN shall return 059";
CM_ SG_ 2650544382 DatabaseID "Number of route, waypoint, event, mark, etc.";
CM_ SG_ 2650544382 NumberOfDatabasesWithComments "Number of route, waypoint, event, mark, etc.";
CM_ SG_ 2650544382 nItems "Number of route, waypoint, event, mark, etc.";
CM_ SG_ 2650544382 StartDatabaseID "Number of route, waypoint, event, mark, etc.";
CM_ BO_ 2314276350 "Rudderder Cmd in direction angle with current rudder angle reading.Directionder field is for non-follow-up rudderders and Angleder field is for follow-up rudderders.When used as a Cmd,Directionder field and Angleder field shall never containder values at ";
CM_ SG_ 2314276350 Pos "Rudder angle where positive values are starboard and negative values are port";
CM_ SG_ 2314276350 Angleder "Rudder angle where positive values are starboard and negative values are port";
CM_ SG_ 2314276350 Directionder "MSB/LSB: 
000 = No Order, 
001 = Move to starboard, 
010 = Move to port.";
CM_ SG_ 2314276350 RudderInstance "For Engs:
0 = Instance 0;          0 = Single Eng Dual Eng Port
1 = Instance 1;          1 = Dual Eng StarBoard  
                                  (for Multiple Engs,Instances will start 
        thru                            from Bow,Port(0)to Ste";
CM_ BO_ 2650543614 "Complex Rq of this PGN will return XTE Limit and/or Navigation Method specific to individual legs of a Route.

Database ID and Route ID shall be specified in Rq/reply.

parameters apply to one leg after Waypoint identified with RPS# in Forward Directi";
CM_ SG_ 2650543614 NavMethodInLegAfterWP "0 = Great Circle calculations, 
1 = Rhumb Line calculations, 
2 = Error, 
3 = Null";
CM_ SG_ 2650543614 XTELimitInLegAfterWP "A commanded distance like radius order, off-track limit, etc.";
CM_ SG_ 2650543614 RPS "Number of route, waypoint, event, mark, etc.";
CM_ SG_ 2650543614 RouteID "Number of route, waypoint, event, mark, etc.";
CM_ SG_ 2650543614 DatabaseID "Number of route, waypoint, event, mark, etc.";
CM_ SG_ 2650543614 NmbrOfWypntsWthASpcfcXTELmtNvMth "Number of route, waypoint, event, mark, etc.";
CM_ SG_ 2650543614 nItems "Number of route, waypoint, event, mark, etc.";
CM_ SG_ 2650543614 StartRPS "Number of route, waypoint, event, mark, etc.";
CM_ BO_ 2650542846 "Complex Rq for this PGN should return attributes of a Route WP-List.

WARNING:Route Track may not be defined by Waypoint Poss only:Navigation Method(GC/RL)and Radius of Turn at each Waypoint are optional additional parameters defining Track.
PGN 130066";
CM_ SG_ 2650542846 Route_WPListName "Name of place, route, waypoint, destination, vessel, vehicle, etc.";
CM_ SG_ 2650542846 RouteID "Number of route, waypoint, event, mark, etc.";
CM_ SG_ 2650542846 DatabaseID "Number of route, waypoint, event, mark, etc.";
CM_ BO_ 2650543870 "Complex Rq of this PGN should return supplementary Comments attached to Waypoints in a Route a WP-List.

Waypoints without a Commment shall not be included in this PGN.

If Route ID is set to 65535(NA),Comments will be for Waypoints in WP-List.
Datab";
CM_ SG_ 2650543870 WPID_RPS "Number of route, waypoint, event, mark, etc.";
CM_ SG_ 2650543870 RouteID "Number of route, waypoint, event, mark, etc.";
CM_ SG_ 2650543870 DatabaseID "Number of route, waypoint, event, mark, etc.";
CM_ SG_ 2650543870 NumberOfWPsWithComments "Number of route, waypoint, event, mark, etc.";
CM_ SG_ 2650543870 nItems "Number of route, waypoint, event, mark, etc.";
CM_ SG_ 2650543870 StartID "Number of route, waypoint, event, mark, etc.";
CM_ BO_ 2650543102 "Complex Rq of this PGN should return Waypoints belonging to a Route.

WARNING:Route Track may not be defined by Waypoint Poss only:Navigation Method(GC/RL)and Radius of Turn at each Waypoint are optional additional parameters defining Track.
PGN 130066";
CM_ SG_ 2650543102 WPName "Name of place, route, waypoint, destination, vessel, vehicle, etc.";
CM_ SG_ 2650543102 WPID "Number of route, waypoint, event, mark, etc.";
CM_ SG_ 2650543102 RouteID "Number of route, waypoint, event, mark, etc.";
CM_ SG_ 2650543102 DatabaseID "Number of route, waypoint, event, mark, etc.";
CM_ SG_ 2650543102 NumberOfWPsInRoute "Number of route, waypoint, event, mark, etc.";
CM_ SG_ 2650543102 nItems "Number of route, waypoint, event, mark, etc.";
CM_ SG_ 2650543102 StartRPS "Number of route, waypoint, event, mark, etc.";
CM_ BO_ 2650543358 "Complex Rq of this PGN should return Waypoints belonging to a Route.

WARNING:Route Track may not be defined by Waypoint Poss only:Navigation Method(GC/RL)and Radius of Turn at each Waypoint are optional additional parameters defining Track.
PGN 130066";
CM_ SG_ 2650543358 WPName "Name of place, route, waypoint, destination, vessel, vehicle, etc.";
CM_ SG_ 2650543358 WPID "Number of route, waypoint, event, mark, etc.";
CM_ SG_ 2650543358 RouteID "Number of route, waypoint, event, mark, etc.";
CM_ SG_ 2650543358 DatabaseID "Number of route, waypoint, event, mark, etc.";
CM_ SG_ 2650543358 NumberOfWPsInRoute "Number of route, waypoint, event, mark, etc.";
CM_ SG_ 2650543358 nItems "Number of route, waypoint, event, mark, etc.";
CM_ SG_ 2650543358 StartRPS "Number of route, waypoint, event, mark, etc.";
CM_ BO_ 2650542590 "Complex Rq for this PGN should return a list of Routes in a Database.

A Database may contain Routes identified with Route ID in range 0-65532.There may be empty gaps(Route ID does not represent a valid/existent Route)anywhere in this range.This PGN sha";
CM_ SG_ 2650542590 RouteName "Name of place, route, waypoint, destination, vessel, vehicle, etc.";
CM_ SG_ 2650542590 RouteID "Number of route, waypoint, event, mark, etc.";
CM_ SG_ 2650542590 DatabaseID "Number of route, waypoint, event, mark, etc.";
CM_ SG_ 2650542590 NmbrOfRoutesAvailableInDatabase "Number of route, waypoint, event, mark, etc.";
CM_ SG_ 2650542590 nItems "Number of route, waypoint, event, mark, etc.";
CM_ SG_ 2650542590 StartRouteID "Number of route, waypoint, event, mark, etc.";
CM_ BO_ 2650544126 "Complex Rq of this PGN should return supplementary Comments attached to Routes.

Database ID shall be specified in Rq/reply.
Routes without a comment shall not be included in this PGN.

reply should use same transfer Protcl as Rq.
ISO Rq for this PG";
CM_ SG_ 2650544126 RouteID "Number of route, waypoint, event, mark, etc.";
CM_ SG_ 2650544126 DatabaseID "Number of route, waypoint, event, mark, etc.";
CM_ SG_ 2650544126 NumberOfRoutesWithComments "Number of route, waypoint, event, mark, etc.";
CM_ SG_ 2650544126 nItems "Number of route, waypoint, event, mark, etc.";
CM_ SG_ 2650544126 StartRouteID "Number of route, waypoint, event, mark, etc.";
CM_ BO_ 2650544638 "Complex Rq of this PGN should return Radius of Turn at specific Waypoints of a Route.

For a complete description of Route and WP PGNs,see App note in Appendix D.Radius of Turn is described in Appendix D.5.15.6.

Database ID and Route ID shall be spec";
CM_ SG_ 2650544638 RadiusOfTurn "A commanded distance like radius order, off-track limit, etc.";
CM_ SG_ 2650544638 RPS "Number of route, waypoint, event, mark, etc.";
CM_ SG_ 2650544638 RouteID "Number of route, waypoint, event, mark, etc.";
CM_ SG_ 2650544638 DatabaseID "Number of route, waypoint, event, mark, etc.";
CM_ SG_ 2650544638 NmbrOfWypntsWthASpcfcRdusOfTurn "Number of route, waypoint, event, mark, etc.";
CM_ SG_ 2650544638 nItems "Number of route, waypoint, event, mark, etc.";
CM_ SG_ 2650544638 StartRPS "Number of route, waypoint, event, mark, etc.";
CM_ BO_ 2650542334 "Complex Rq for this PGN should return a list of Databases in which a navigation Deviceganizes its Routes and WPs.

A Database may contain one WP-List and multiple Routes.

A device need not support concept of multiple Databases.support of this PGN is ";
CM_ SG_ 2650542334 DatabaseName "Name of place, route, waypoint, destination, vessel, vehicle, etc.";
CM_ SG_ 2650542334 DatabaseID "Number of route, waypoint, event, mark, etc.";
CM_ SG_ 2650542334 NumberOfDatabasesAvailable "Number of route, waypoint, event, mark, etc.";
CM_ SG_ 2650542334 nItems "Number of route, waypoint, event, mark, etc.";
CM_ SG_ 2650542334 StartDatabaseID "Number of route, waypoint, event, mark, etc.";
CM_ BO_ 2314277886 "Rate of Turn is the rate of change of the Heading.

Heading is defined as the direction of the vertical projection of the fore-and-aft line of the ship onto the horizontal plane.";
CM_ SG_ 2314277886 RateOfTurn "+ = Bow turning to starboard, 1 deg/min = .00029 rad/sec";
CM_ SG_ 2314277886 SequenceID_ "An upward counting number used to tie related information together between different PGNs.For example,SID would be used to tie together COG,SOG and RAIM values to a given Pos.255=no valid Pos fix to tie it to.Range 0 to 250 for valid Pos fixes.";
CM_ BO_ 2382039038 "This PGN provides status and control for a Radiotelephone, connected to a NMEA 2000 network.

The Radiotelephone will transmit and receive status along with remote control and repeater products.";
CM_ SG_ 2382039038 RadioChannel "MF/HF telephone channels to have first digit 3 followed by ITU channel numbers with leading zeros as required.MF/HF teletype channels to have first digit 4; second and third digit give frequency bands; and fourth to sixth digits ITU channel numbers; each ";
CM_ BO_ 2314732542 "The'Pos Delta,High Precision Rapid Update'Parameter Group is intended for Apps where very high precision and very fast update rates are needed for Pos data.This PG can provide delta Pos changes down to 1 millimeter with a delta time period accurate to 5 m";
CM_ SG_ 2314732542 SequenceID_ "An upward counting number used to tie related information together between different PGNs.For example,SID would be used to tie together COG,SOG and RAIM values to a given Pos.255=no valid Pos fix to tie it to.Range 0 to 250 for valid Pos fixes.";
CM_ BO_ 2582648062 "Provides product information onto network that could be important for determining quality of data coming from this product.Each field must be provided if data is typically available from such a product.At Min NMEA 2000 Version,NMEA Manufacturer’s Product ";
CM_ SG_ 2582648062 ManufacturersModelID "Length specified by PGN field definition.";
CM_ SG_ 2582648062 NMEAManufacturersProductCode "Number of route, waypoint, event, mark, etc.";
CM_ SG_ 2582648062 NMEA2000DatabaseVersion "Number of route, waypoint, event, mark, etc.";
CM_ BO_ 2314732030 "This PGN provides latitude and longitude referenced to WGS84.Being defined as single frame Msg,as opposed to other PGNs that include latitude and longitude and are defined as fast multi-packet,this PGN lends itself to being transmitted more frequently wit";
CM_ BO_ 2582576894 "Transmit/Receive PGN List Group type of function is defined by first field.Msg will be a Transmit Receive PGN List group function.These are defined as follows:

Transmit PGN List group function:This Msg contains a list of Transmitted PGNs that are suppo";
CM_ SG_ 2582576894 VrblNmbrOfFldsFldNmber2Repeated2 "24-bit Parameter Group Number (PGN) expressed in binary, LSB is transmitted first";
CM_ SG_ 2582576894 FirstPGNSupported2 "24-bit Parameter Group Number (PGN) expressed in binary, LSB is transmitted first";
CM_ SG_ 2582576894 VrblNmbrOfFldsFldNmber2Repeated "24-bit Parameter Group Number (PGN) expressed in binary, LSB is transmitted first";
CM_ SG_ 2582576894 FirstPGNSupported "24-bit Parameter Group Number (PGN) expressed in binary, LSB is transmitted first";
CM_ SG_ 2582576894 GrpFnctnTrnsmtAndReceivePGNList "0 = Transmit PGN List Message, 
1 = Receive PGN List Message";
CM_ BO_ 2583234046 "This PGN shall return Route and WP data ahead in Active Route.
It can be Rqed may be transmitted without a Rq,typically at each Waypoint advance.
 
When navigating Route in Forward direction,Waypoints shall be included inder of increasing RPS#s.When na";
CM_ SG_ 2583234046 RouteName "Name of place, route, waypoint, destination, vessel, vehicle, etc.";
CM_ SG_ 2583234046 SpplmntaryRoute_WPDataAvailable "MSB/LSB: 
00 = [No, Off, Disabled, Reset, '0'], 
01 = [Yes, On, Enabled, Set, '1'], 
10 = Error, 
11= [Unavailable, Unknown]";
CM_ SG_ 2583234046 NavigationDirectionInRoute "0=Forward, 
1=Reverse, 
2-5 Reserved, 
6= Error, 
7=Null (info not available)";
CM_ SG_ 2583234046 RouteID "Number of route, waypoint, event, mark, etc.";
CM_ SG_ 2583234046 DatabaseID "Number of route, waypoint, event, mark, etc.";
CM_ SG_ 2583234046 nItems "Number of route, waypoint, event, mark, etc.";
CM_ SG_ 2583234046 StartRPS "Number of route, waypoint, event, mark, etc.";
CM_ BO_ 2381907198 "This PGN provides essential navigation data for following a route.

Transmissions will originate from products that can create and manage routes using waypoints.  This information is intended for navigational repeaters.";
CM_ SG_ 2381907198 WaypointClosingVelocity "Positive values represent ahead or starboard transverse speed and negative values represent astern or port transverse speed.";
CM_ SG_ 2381907198 DestinationWaypointNumber "Number of route, waypoint, event, mark, etc.";
CM_ SG_ 2381907198 OriginWaypointNumber "Number of route, waypoint, event, mark, etc.";
CM_ SG_ 2381907198 BearingPosToDestinationWaypoint "The horizontal direction of one terrestrial point from another, expressed as the angular distance from a reference direction, measured from 000 at the reference direction clockwise through 359 degrees.";
CM_ SG_ 2381907198 BaringiginToDestinationWaypoint "The horizontal direction of one terrestrial point from another, expressed as the angular distance from a reference direction, measured from 000 at the reference direction clockwise through 359 degrees.";
CM_ SG_ 2381907198 ETADate "Days since January 1, 1970,   Date is relative to UTC Time.";
CM_ SG_ 2381907198 ETATime "24 hour clock, 0 =  midnight,  time is in UTC";
CM_ SG_ 2381907198 CalculationType "0 = Great Circle calculations, 
1 = Rhumb Line calculations, 
2 = Error, 
3 = Null";
CM_ SG_ 2381907198 ArrivalCircleEntered "MSB/LSB: 
00 = [No, Off, Disabled, Reset, '0'], 
01 = [Yes, On, Enabled, Set, '1'], 
10 = Error, 
11= [Unavailable, Unknown]";
CM_ SG_ 2381907198 PerpendicularCrossed "MSB/LSB: 
00 = [No, Off, Disabled, Reset, '0'], 
01 = [Yes, On, Enabled, Set, '1'], 
10 = Error, 
11= [Unavailable, Unknown]";
CM_ SG_ 2381907198 Course_BearingRef "0 = True, 
1 = Magnetic, 
2 = Error, 
3 = Null";
CM_ SG_ 2381907198 SID "An upward counting number used to tie related information together between different PGNs.For example,SID would be used to tie together COG,SOG and RAIM values to a given Pos.255=no valid Pos fix to tie it to.Range 0 to 250 for valid Pos fixes.";
CM_ BO_ 2381184766 "Rq/Cmd/Acknowledge Group type of function is defined by first field.Msg will be a Rq,Cmd,or Acknowledge Group Function.These are defined as follows:

Rq Group Function:This Msg Rqs Trans of a specific set of data in a Parameter Group by setting variable";
CM_ SG_ 2381184766 NumberOfRqedCmdedParameters "Numeric count, event counter, sequence counter";
CM_ SG_ 2381184766 VrblNmbrOfFldsFldNmber6Repeated3 "0x0 = No Error/Acknowledge; 
0x1 = Invalid request or command parameter field; 
0x2 = Temporarily unable to comply; 
0x3 = Request or command parameter out-of-range; 
0x4 = Access denied; 
0x5 = Request or Command Group Function not supported";
CM_ SG_ 2381184766 FirstParameterErrorCode "0x0 = No Error/Acknowledge; 
0x1 = Invalid request or command parameter field; 
0x2 = Temporarily unable to comply; 
0x3 = Request or command parameter out-of-range; 
0x4 = Access denied; 
0x5 = Request or Command Group Function not supported";
CM_ SG_ 2381184766 TransInterval_PriorityErrorCode "0x0 = No Error/Acknowledge, 
0x1 = Transmit Interval /Priority not supported,
0x2 = Transmit interval is less than measurement/calculation interval, 
0x3 = Access denied.
0x4 = Request is not supported.";
CM_ SG_ 2381184766 RqedCmdedPGNBeingAcknowledged "24-bit Parameter Group Number (PGN) expressed in binary, LSB is transmitted first";
CM_ SG_ 2381184766 PGNErrorCode "0x0 = No Error/Acknowledge, 
0x1 = PGN not supported, 
0x2 = PGN temporarily not available, 
0x3 = Access denied,
0x4 = Request is not supported.";
CM_ SG_ 2381184766 VrblNmbrOfFldsFldNmber6Repeated2 "Number of route, waypoint, event, mark, etc.";
CM_ SG_ 2381184766 FeldNumberOfFirstCmdedParameter "Number of route, waypoint, event, mark, etc.";
CM_ SG_ 2381184766 NmbrOfPrsOfCmddPrmetersToFollow "Numeric count, event counter, sequence counter";
CM_ SG_ 2381184766 PrioritySetting "0x0 to 0x7 = commanded priority value; 
0x8 = do not change priority; 
0x9 = return priority to default; 
0xA to 0xF = reserved";
CM_ SG_ 2381184766 CmdedPGN "24-bit Parameter Group Number (PGN) expressed in binary, LSB is transmitted first";
CM_ SG_ 2381184766 VrblNmbrOfFldsFldNmber6Repeated "Number of route, waypoint, event, mark, etc.";
CM_ SG_ 2381184766 FieldNumberOfFirstRqedParameter "Number of route, waypoint, event, mark, etc.";
CM_ SG_ 2381184766 NmbrOfPrsOfRqParametersToFollow "Numeric count, event counter, sequence counter";
CM_ SG_ 2381184766 TransIntervalOffset "Offset in transmit time from time of request command: 0x0 = transmit immediately, 0xFFFF = Do not change offset.";
CM_ SG_ 2381184766 TransInterval "Time interval between data transmissions: 0x0 = Turn-off transmission  0xFFFF FFFF = Do not change interval";
CM_ SG_ 2381184766 RqedPGN "24-bit Parameter Group Number (PGN) expressed in binary, LSB is transmitted first";
CM_ SG_ 2381184766 GroupFunctionRq_Cmd_Acknowledge "0 = Request Message, 
1 = Command Message, 
2 = Acknowledge Message";
CM_ BO_ 2583500030 "Moored buoy measurement data including station location and numeric identifier.";
CM_ SG_ 2583500030 StationIDString "Name of place, route, waypoint, destination, vessel, vehicle, etc.";
CM_ SG_ 2583500030 PressTendencyRate "Positive value indicates Rising, Negative value indicates Falling.";
CM_ SG_ 2583500030 DominateWavePeriod "Average wave period of all waves during a 20-minute period. Dominant wave period is the period with the maximum wave energy.  Note: See DD50 note.";
CM_ SG_ 2583500030 WaveHeight "Wave height is calculated as highest one-third of all of wave heights during a 20-minute sampling period.Note:Accelerometers inclinometers on board buoys measure heave acceleration vertical displacement of buoy hull during wave acquisition time.A Fast Fou";
CM_ SG_ 2583500030 WindGusts "Peak wind gust speed.  Sustained wind over an interval of 5 seconds.";
CM_ SG_ 2583500030 WindReference "0x00 = True (referenced to North)
0x01 = Magnetic
0x02 = Apparent
0x03 = True (boat referenced)
0x04 = Reserved
0x05 = Reserved
0x06 = Error
0x07 = Null";
CM_ SG_ 2583500030 MeasurementTime "24 hour clock, 0 =  midnight,  time is in UTC";
CM_ SG_ 2583500030 MeasurementDate "Days since January 1, 1970,   Date is relative to UTC Time.";
CM_ SG_ 2583500030 Mode "Range Residual used in position calculation or range residuals were calculated after the position.  
0=range residuals were used to calculate data; 
1=range residuals were calculated after the position., 
2=Error, 
3=Null";
CM_ BO_ 2583499774 "Meteorological station measurement data including station location, numeric identifier, and name.";
CM_ SG_ 2583499774 StationIDString "Name of place, route, waypoint, destination, vessel, vehicle, etc.";
CM_ SG_ 2583499774 WindGusts "Peak wind gust speed.  Sustained wind over an interval of 5 seconds.";
CM_ SG_ 2583499774 WindReference "0x00 = True (referenced to North)
0x01 = Magnetic
0x02 = Apparent
0x03 = True (boat referenced)
0x04 = Reserved
0x05 = Reserved
0x06 = Error
0x07 = Null";
CM_ SG_ 2583499774 MeasurementTime "24 hour clock, 0 =  midnight,  time is in UTC";
CM_ SG_ 2583499774 MeasurementDate "Days since January 1, 1970,   Date is relative to UTC Time.";
CM_ SG_ 2583499774 Mode "Range Residual used in position calculation or range residuals were calculated after the position.  
0=range residuals were used to calculate data; 
1=range residuals were calculated after the position., 
2=Error, 
3=Null";
CM_ BO_ 2649823998 "Msg for transmitting variation.Msg contains a sequence number to allow synchronization of other Msgs such as Heading Course over Ground.quality of service and age of service are provided to enable recipients to determine an appropriate level of service if";
CM_ SG_ 2649823998 Variation "Positive values are Easterly and negative values are Westerly.";
CM_ SG_ 2649823998 AgeOfService "Days since January 1, 1970,   Date is relative to UTC Time.";
CM_ SG_ 2649823998 VariationSource "0x00 = Manual Entry,
0x01 = Automatic-Chart,
0x02 = Automatic Table,
0x03 = Automatic Calculation,
0x04 = WMM 2000,
0x05 = WMM 2005,
0x06 = WMM 2010,
0x07 = WMM 2015,
0x08 = WMM 2020,
0x09 = Reserve,
 thru
0x3E = Reserve,
0x3F = Data Not Avail";
CM_ SG_ 2649823998 SequenceID_ "An upward counting number used to tie related information together between different PGNs.For example,SID would be used to tie together COG,SOG and RAIM values to a given Pos.255=no valid Pos fix to tie it to.Range 0 to 250 for valid Pos fixes.";
CM_ BO_ 2382103806 "This provides Time Difference(TD)lines of Pos of Loran-C signals relative to a single Group Repetition Interval.

Field #1,Group Repetition Interval(GRI),is identified as a Rq parameter for this Parameter Group.All providers of this PGN shall accept and";
CM_ SG_ 2382103806 Mode "Range Residual used in position calculation or range residuals were calculated after the position.  
0=range residuals were used to calculate data; 
1=range residuals were calculated after the position., 
2=Error, 
3=Null";
CM_ SG_ 2382103806 StationStatusZ "MSB: to LSB:
xxx1 = Station in use, 
xx1x = Low SNR, 
x1xx = Cycle error, 
1xxx = Blink
            where x = don't care";
CM_ SG_ 2382103806 StationStatusY "MSB: to LSB:
xxx1 = Station in use, 
xx1x = Low SNR, 
x1xx = Cycle error, 
1xxx = Blink
            where x = don't care";
CM_ SG_ 2382103806 StationStatusX "MSB: to LSB:
xxx1 = Station in use, 
xx1x = Low SNR, 
x1xx = Cycle error, 
1xxx = Blink
            where x = don't care";
CM_ SG_ 2382103806 StationStatusW "MSB: to LSB:
xxx1 = Station in use, 
xx1x = Low SNR, 
x1xx = Cycle error, 
1xxx = Blink
            where x = don't care";
CM_ SG_ 2382103806 StationStatusV "MSB: to LSB:
xxx1 = Station in use, 
xx1x = Low SNR, 
x1xx = Cycle error, 
1xxx = Blink
            where x = don't care";
CM_ SG_ 2382103806 StationStatusMaster "MSB: to LSB:
xxx1 = Station in use, 
xx1x = Low SNR, 
x1xx = Cycle error, 
1xxx = Blink
            where x = don't care";
CM_ SG_ 2382103806 ZSecondTD "Loran-C Time difference (TD) in nano-sec.  The arrival time of a Loran-C secondary station signal minus the arrival time of the master station signal.";
CM_ SG_ 2382103806 YSecondTD "Loran-C Time difference (TD) in nano-sec.  The arrival time of a Loran-C secondary station signal minus the arrival time of the master station signal.";
CM_ SG_ 2382103806 XSecondTD "Loran-C Time difference (TD) in nano-sec.  The arrival time of a Loran-C secondary station signal minus the arrival time of the master station signal.";
CM_ SG_ 2382103806 WSecondTD "Loran-C Time difference (TD) in nano-sec.  The arrival time of a Loran-C secondary station signal minus the arrival time of the master station signal.";
CM_ SG_ 2382103806 VSecondTD "Loran-C Time difference (TD) in nano-sec.  The arrival time of a Loran-C secondary station signal minus the arrival time of the master station signal.";
CM_ SG_ 2382103806 MasterRange "The actual propagation time of a Loran-C signal from the station to a receiver in nano-sec.";
CM_ SG_ 2382103806 GroupRepetitionInterval "Group Repetition Interval (GRI) in nano-sec.  Often cited in units of 10 micro-sec. (i.e., 9960 = 99,600,000 ns)";
CM_ BO_ 2382104318 "SNR,ECD,and ASF values of Loran-C signals

Field #1,Group Repetition Interval(GRI),is identified as a Rq parameter for this Parameter Group.All providers of this PGN shall accept and process Rqs based upon Rqed value of Field #1.A device receiving an IS";
CM_ SG_ 2382104318 StationIdentifier "1-character code for the Loran-C station: M = master, V, W, X, Y, Z";
CM_ SG_ 2382104318 GroupRepetitionInterval "Group Repetition Interval (GRI) in nano-sec.  Often cited in units of 10 micro-sec. (i.e., 9960 = 99,600,000 ns)";
CM_ BO_ 2382104062 "This provides Propagation times(Ranges)of Loran-C signals relative to a single Group Repetition Interval.

Field #1,Group Repetition Interval(GRI),is identified as a Rq parameter for this Parameter Group.All providers of this PGN shall accept and proces";
CM_ SG_ 2382104062 Mode "Range Residual used in position calculation or range residuals were calculated after the position.  
0=range residuals were used to calculate data; 
1=range residuals were calculated after the position., 
2=Error, 
3=Null";
CM_ SG_ 2382104062 StationStatusZ "MSB: to LSB:
xxx1 = Station in use, 
xx1x = Low SNR, 
x1xx = Cycle error, 
1xxx = Blink
            where x = don't care";
CM_ SG_ 2382104062 StationStatusY "MSB: to LSB:
xxx1 = Station in use, 
xx1x = Low SNR, 
x1xx = Cycle error, 
1xxx = Blink
            where x = don't care";
CM_ SG_ 2382104062 StationStatusX "MSB: to LSB:
xxx1 = Station in use, 
xx1x = Low SNR, 
x1xx = Cycle error, 
1xxx = Blink
            where x = don't care";
CM_ SG_ 2382104062 StationStatusW "MSB: to LSB:
xxx1 = Station in use, 
xx1x = Low SNR, 
x1xx = Cycle error, 
1xxx = Blink
            where x = don't care";
CM_ SG_ 2382104062 StationStatusV "MSB: to LSB:
xxx1 = Station in use, 
xx1x = Low SNR, 
x1xx = Cycle error, 
1xxx = Blink
            where x = don't care";
CM_ SG_ 2382104062 StationStatusMaster "MSB: to LSB:
xxx1 = Station in use, 
xx1x = Low SNR, 
x1xx = Cycle error, 
1xxx = Blink
            where x = don't care";
CM_ SG_ 2382104062 ZSecondRange "The actual propagation time of a Loran-C signal from the station to a receiver in nano-sec.";
CM_ SG_ 2382104062 YSecondRange "The actual propagation time of a Loran-C signal from the station to a receiver in nano-sec.";
CM_ SG_ 2382104062 XSecondRange "The actual propagation time of a Loran-C signal from the station to a receiver in nano-sec.";
CM_ SG_ 2382104062 WSecondRange "The actual propagation time of a Loran-C signal from the station to a receiver in nano-sec.";
CM_ SG_ 2382104062 VSecondRange "The actual propagation time of a Loran-C signal from the station to a receiver in nano-sec.";
CM_ SG_ 2382104062 MasterRange "The actual propagation time of a Loran-C signal from the station to a receiver in nano-sec.";
CM_ SG_ 2382104062 GroupRepetitionInterval "Group Repetition Interval (GRI) in nano-sec.  Often cited in units of 10 micro-sec. (i.e., 9960 = 99,600,000 ns)";
CM_ BO_ 2314274302 "Sends Cmds to,and receives data from,heading Ctrl systems.Allows for navigational(remote)Ctrl of a heading Ctrl system and direct rudder Ctrl.When used as a Cmd,Cmded Rudder Direction field and Cmded Rudder Angle should never containder values at same tim";
CM_ SG_ 2314274302 VesselHeading "The horizontal direction in which a ship actually points or heads at any instant, expressed in angular units from a reference direction, usually from 000 at the reference direction clockwise through 359 degrees.";
CM_ SG_ 2314274302 OffTrackLimit "A commanded distance like radius order, off-track limit, etc.";
CM_ SG_ 2314274302 RateOfTurnder "+ = Bow turning to starboard, 1 deg/min = .00029 rad/sec";
CM_ SG_ 2314274302 RadiusOfTurnder "A commanded distance like radius order, off-track limit, etc.";
CM_ SG_ 2314274302 Track "intended desired horizontal direction of travel with respect to earth.track expressed in degrees of compass may differ from course due to allowances made in course for such factors as sea and weather conditions inder to achieve desired track.This field re";
CM_ SG_ 2314274302 HeadingToSteer "The horizontal direction in which a vessel is steered or intended to be steered, expressed as angular distance 000 north, clockwise through 359 degrees.  Not to be confused with Course-over-ground, Track, or Heading.";
CM_ SG_ 2314274302 CmdedRudderAngle "Rudder angle where positive values are starboard and negative values are port";
CM_ SG_ 2314274302 CmdedRudderDirection "MSB/LSB: 
000 = No Order, 
001 = Move to starboard, 
010 = Move to port.";
CM_ SG_ 2314274302 HeadingReference "0 = True, 
1 = Magnetic, 
2 = Error, 
3 = Null";
CM_ SG_ 2314274302 TurnMode "MSB/LSB:
000 = Rudder Limit Ctrlled,
001 = turn rate Ctrlled,
010 = radius Ctrlled.
Definitions:Rudder – An operator set rudder limit determines Max turning capability available,in which case system outputs rudderders up to and limited by rudder limit";
CM_ SG_ 2314274302 SteerMode "MSB/LSB:
000 = Main Steer,
001 = Non-Follow-up Device,
010 = Follow-up Device,
011 = Heading Ctrl Standalone,
100 = Heading Ctrl,
101 = Track Ctrl.
Definitions:Main Steer/Outside System – main Steer system is in use.
Non-Follow-up Device – system ";
CM_ SG_ 2314274302 Override "1 = Yes,0 = No.Yes means a temporary interruption of selected Steer mode.As long as this field is Yes,Steer Mode and Turn Mode shall be ignored by heading/track Ctrl and its computing parts shall operate as if manual Steer was selected.";
CM_ SG_ 2314274302 OffTrackLimitExceeded "MSB/LSB: 
00 = [No, Off, Disabled, Reset, '0'], 
01 = [Yes, On, Enabled, Set, '1'], 
10 = Error, 
11= [Unavailable, Unknown]";
CM_ SG_ 2314274302 OffHeadingLimitExceeded "MSB/LSB: 
00 = [No, Off, Disabled, Reset, '0'], 
01 = [Yes, On, Enabled, Set, '1'], 
10 = Error, 
11= [Unavailable, Unknown]";
CM_ SG_ 2314274302 RudderLimitExceeded "MSB/LSB: 
00 = [No, Off, Disabled, Reset, '0'], 
01 = [Yes, On, Enabled, Set, '1'], 
10 = Error, 
11= [Unavailable, Unknown]";
CM_ BO_ 2583299582 "This PGN provides a single Trans that contains relevant almanac data for GPS products.almanac contains satellite vehicle coursebital parameters.This information is not considered precise and is only valid for several months at a time.GPS products receive ";
CM_ SG_ 2583299582 ClockParameter2 "Clock Parameter 2.  Reference ICD-GPS-200 Table 20-VI for scaling factors and units.";
CM_ SG_ 2583299582 ClockParameter1 "Clock Parameter 1.  Reference ICD-GPS-200 Table 20-VI for scaling factors and units.";
CM_ SG_ 2583299582 MeanAnomaly "Mean anomaly.  Reference ICD-GPS-200 Table 20-VI for scaling factors and units.";
CM_ SG_ 2583299582 LongitudeOfAscensionNode "Longitude of ascension node.  Reference ICD-GPS-200 Table 20-VI for scaling factors and units.";
CM_ SG_ 2583299582 ArgumentOfPerigee "Argument of Perigee.  Reference ICD-GPS-200 Table 20-VI for scaling factors and units.";
CM_ SG_ 2583299582 RootOfSemimajorAxis "Root of semi-major axis.  Reference ICD-GPS-200 Table 20-VI for scaling factors and units.";
CM_ SG_ 2583299582 RateOfRightAscension "Rate of right ascension, OMEGADOT.  Reference ICD-GPS-200 Table 20-VI for scaling factors and units.";
CM_ SG_ 2583299582 InclinationAngle "Inclination angle.  Reference ICD-GPS-200 Table 20-VI for scaling factors and units.";
CM_ SG_ 2583299582 AlmanacReferenceTime "Almanac reference time.  Reference ICD-GPS-200 Table 20-VI for scaling factors and units.";
CM_ SG_ 2583299582 Eccentricity "Eccentricity, e.  Reference ICD-GPS-200 Table 20-VI for scaling factors and units.";
CM_ SG_ 2583299582 SVHealthBits "SV health, bits 17-24 of each almanac page.  Reference ICD-GPS-200 paragraph 20.3.3.5.1.3, Table 20-VII and Table 20-VIII";
CM_ SG_ 2583299582 GPSWeekNumber "GPS week number. Starting on 6 Jan., 1980.  The GPS week number roll over will not affect this value, i.e., it will continue to count up 1022, 1023, 1024, 1025.";
CM_ SG_ 2583299582 PRN "0 = value not used,
  1-32 = GPS,
33-64 = SBAS,Satellite,Based Augmentation System(ie WAAS)
65-96 = GLONASS.
For GLONASS,satellites are identified by 64+satellite slot number.slot numbers are 1 through 24 for full GLONASS constellation of 24 satellite";
BA_DEF_ BO_  "GenMsgCycleTimeFast" INT 0 3600000;
BA_DEF_ SG_  "SigType" ENUM  "Default","Range","RangeSigned","ASCII","Discrete","Control","ReferencePGN","DTC","StringDelimiter","StringLength","StringLengthControl";
BA_DEF_ SG_  "GenSigStartValue" INT 0 10000;
BA_DEF_ SG_  "GenSigSendType" ENUM  "Cyclic","OnWrite","reserved","OnChange","reserved","reserved","reserved","NoSigSendType";
BA_DEF_ SG_  "GenSigILSupport" ENUM  "Yes","No";
BA_DEF_ SG_  "GenSigEVName" STRING ;
BA_DEF_ SG_  "SPN" INT 0 524287;
BA_DEF_ SG_  "DDI" INT 0 65535;
BA_DEF_ SG_  "SAEDocument" STRING ;
BA_DEF_ BO_  "GenMsgStartDelayTime" INT 0 100000;
BA_DEF_ BO_  "GenMsgILSupport" ENUM  "Yes","No";
BA_DEF_ BO_  "GenMsgRequestable" INT 0 1;
BA_DEF_ BO_  "GenMsgSendType" ENUM  "cyclic","reserved","cyclicIfActive","reserved","reserved","reserved","reserved","reserved","noMsgSendType";
BA_DEF_ BO_  "VFrameFormat" ENUM  "StandardCAN","ExtendedCAN","reserved","J1939PG";
BA_DEF_ BO_  "SingleFrame" INT 0 1;
BA_DEF_ BO_  "GenMsgCycleTime" INT 0 3600000;
BA_DEF_ BO_  "SAE_Document" STRING ;
BA_DEF_ SG_  "SystemSignalLongSymbol" STRING ;
BA_DEF_DEF_  "GenMsgCycleTimeFast" 0;
BA_DEF_DEF_  "SigType" "Default";
BA_DEF_DEF_  "GenSigStartValue" 0;
BA_DEF_DEF_  "GenSigSendType" "NoSigSendType";
BA_DEF_DEF_  "GenSigILSupport" "Yes";
BA_DEF_DEF_  "GenSigEVName" "Env@Nodename_@Signame";
BA_DEF_DEF_  "SPN" 0;
BA_DEF_DEF_  "DDI" 0;
BA_DEF_DEF_  "SAEDocument" "";
BA_DEF_DEF_  "GenMsgStartDelayTime" 0;
BA_DEF_DEF_  "GenMsgILSupport" "Yes";
BA_DEF_DEF_  "GenMsgRequestable" 1;
BA_DEF_DEF_  "GenMsgSendType" "noMsgSendType";
BA_DEF_DEF_  "VFrameFormat" "J1939PG";
BA_DEF_DEF_  "SingleFrame" 1;
BA_DEF_DEF_  "GenMsgCycleTime" 0;
BA_DEF_DEF_  "SAE_Document" "";
BA_DEF_DEF_  "SystemSignalLongSymbol" "";
BA_ "GenMsgCycleTime" BO_ 2566706686 500;
BA_ "GenMsgCycleTime" BO_ 2566704126 100;
BA_ "GenMsgCycleTime" BO_ 2566703870 100;
BA_ "GenMsgCycleTime" BO_ 2566703614 100;
BA_ "GenMsgCycleTime" BO_ 2566703358 1000;
BA_ "GenMsgCycleTime" BO_ 2566702590 500;
BA_ "GenMsgCycleTime" BO_ 2566702334 500;
BA_ "GenMsgCycleTime" BO_ 2566702078 200;
BA_ "GenMsgCycleTime" BO_ 2566701822 1000;
BA_ "GenMsgCycleTime" BO_ 2431661310 50;
BA_ "GenMsgCycleTime" BO_ 2431661054 50;
BA_ "GenMsgCycleTime" BO_ 2230334206 20;
BA_ "GenMsgCycleTime" BO_ 2230333950 20;
BA_ "GenMsgCycleTime" BO_ 2364551422 50;
BA_ "GenMsgCycleTime" BO_ 2566730238 1000;
BA_ "GenMsgCycleTime" BO_ 2566711038 500;
BA_ "GenMsgCycleTime" BO_ 2566710782 30000;
BA_ "GenMsgCycleTime" BO_ 2566710526 30000;
BA_ "GenMsgCycleTime" BO_ 2432492542 100;
BA_ "GenMsgCycleTime" BO_ 2566710014 1000;
BA_ "GenMsgCycleTime" BO_ 2566709758 100;
BA_ "GenMsgCycleTime" BO_ 2566709502 100;
BA_ "GenMsgCycleTime" BO_ 2566709246 500;
BA_ "GenMsgCycleTime" BO_ 2566708990 500;
BA_ "GenMsgCycleTime" BO_ 2566708734 500;
BA_ "GenMsgCycleTime" BO_ 2566708478 1000;
BA_ "GenMsgCycleTime" BO_ 2566708222 1000;
BA_ "GenMsgCycleTime" BO_ 2566707966 1000;
BA_ "GenMsgCycleTime" BO_ 2566707710 1000;
BA_ "SAE_Document" BO_ 2315059966 "NMEA2000";
BA_ "GenMsgCycleTime" BO_ 2315059966 100;
BA_ "SAE_Document" BO_ 2381646846 "NMEA2000";
BA_ "GenMsgCycleTime" BO_ 2381646846 1000;
BA_ "SAE_Document" BO_ 2315129598 "NMEA2000";
BA_ "GenMsgCycleTime" BO_ 2315129598 250;
BA_ "SingleFrame" BO_ 2315129598 0;
BA_ "SAE_Document" BO_ 2314277630 "NMEA2000";
BA_ "GenMsgCycleTime" BO_ 2314277630 100;
BA_ "SAE_Document" BO_ 2583172606 "NMEA2000";
BA_ "SingleFrame" BO_ 2583172606 0;
BA_ "SAE_Document" BO_ 2515667198 "NMEA2000";
BA_ "GenMsgCycleTime" BO_ 2515667198 1000;
BA_ "SingleFrame" BO_ 2515667198 0;
BA_ "GenMsgRequestable" BO_ 2515667198 0;
BA_ "SAE_Document" BO_ 2515667454 "NMEA2000";
BA_ "GenMsgCycleTime" BO_ 2515667454 1000;
BA_ "SingleFrame" BO_ 2515667454 0;
BA_ "SAE_Document" BO_ 2314339838 "NMEA2000";
BA_ "GenMsgCycleTime" BO_ 2314339838 100;
BA_ "SAE_Document" BO_ 2314602750 "NMEA2000";
BA_ "GenMsgCycleTime" BO_ 2314602750 1000;
BA_ "SingleFrame" BO_ 2314602750 0;
BA_ "SAE_Document" BO_ 2381842942 "NMEA2000";
BA_ "GenMsgCycleTime" BO_ 2381842942 1000;
BA_ "SAE_Document" BO_ 2381911550 "NMEA2000";
BA_ "GenMsgCycleTime" BO_ 2381911550 1000;
BA_ "SingleFrame" BO_ 2381911550 0;
BA_ "SAE_Document" BO_ 2583499006 "NMEA2000";
BA_ "GenMsgCycleTime" BO_ 2583499006 1000;
BA_ "SingleFrame" BO_ 2583499006 0;
BA_ "SAE_Document" BO_ 2381320446 "NMEA2000";
BA_ "GenMsgCycleTime" BO_ 2381320446 1000;
BA_ "SAE_Document" BO_ 2381451006 "NMEA2000";
BA_ "SAE_Document" BO_ 2314535934 "NMEA2000";
BA_ "GenMsgCycleTime" BO_ 2314535934 1000;
BA_ "SAE_Document" BO_ 2315129086 "NMEA2000";
BA_ "GenMsgCycleTime" BO_ 2315129086 200;
BA_ "SAE_Document" BO_ 2381908990 "NMEA2000";
BA_ "GenMsgCycleTime" BO_ 2381908990 1000;
BA_ "SAE_Document" BO_ 2583499262 "NMEA2000";
BA_ "GenMsgCycleTime" BO_ 2583499262 1000;
BA_ "SingleFrame" BO_ 2583499262 0;
BA_ "SAE_Document" BO_ 2650544894 "NMEA2000";
BA_ "SingleFrame" BO_ 2650544894 0;
BA_ "SAE_Document" BO_ 2650544382 "NMEA2000";
BA_ "SingleFrame" BO_ 2650544382 0;
BA_ "SAE_Document" BO_ 2314276350 "NMEA2000";
BA_ "GenMsgCycleTime" BO_ 2314276350 100;
BA_ "SAE_Document" BO_ 2650543614 "NMEA2000";
BA_ "SingleFrame" BO_ 2650543614 0;
BA_ "SAE_Document" BO_ 2650542846 "NMEA2000";
BA_ "SingleFrame" BO_ 2650542846 0;
BA_ "SAE_Document" BO_ 2650543870 "NMEA2000";
BA_ "SingleFrame" BO_ 2650543870 0;
BA_ "SAE_Document" BO_ 2650543102 "NMEA2000";
BA_ "SingleFrame" BO_ 2650543102 0;
BA_ "SAE_Document" BO_ 2650543358 "NMEA2000";
BA_ "SingleFrame" BO_ 2650543358 0;
BA_ "SAE_Document" BO_ 2650542590 "NMEA2000";
BA_ "SingleFrame" BO_ 2650542590 0;
BA_ "SAE_Document" BO_ 2650544126 "NMEA2000";
BA_ "SingleFrame" BO_ 2650544126 0;
BA_ "SAE_Document" BO_ 2650544638 "NMEA2000";
BA_ "SingleFrame" BO_ 2650544638 0;
BA_ "SAE_Document" BO_ 2650542334 "NMEA2000";
BA_ "SingleFrame" BO_ 2650542334 0;
BA_ "SAE_Document" BO_ 2314277886 "NMEA2000";
BA_ "GenMsgCycleTime" BO_ 2314277886 100;
BA_ "SAE_Document" BO_ 2382039038 "NMEA2000";
BA_ "SingleFrame" BO_ 2382039038 0;
BA_ "SAE_Document" BO_ 2314732542 "NMEA2000";
BA_ "GenMsgCycleTime" BO_ 2314732542 100;
BA_ "GenMsgRequestable" BO_ 2314732542 0;
BA_ "SAE_Document" BO_ 2582648062 "NMEA2000";
BA_ "SingleFrame" BO_ 2582648062 0;
BA_ "SAE_Document" BO_ 2314732030 "NMEA2000";
BA_ "GenMsgCycleTime" BO_ 2314732030 100;
BA_ "SAE_Document" BO_ 2582576894 "NMEA2000";
BA_ "SingleFrame" BO_ 2582576894 0;
BA_ "SAE_Document" BO_ 2583234046 "NMEA2000";
BA_ "SingleFrame" BO_ 2583234046 0;
BA_ "GenMsgRequestable" BO_ 2583234046 0;
BA_ "SAE_Document" BO_ 2381907198 "NMEA2000";
BA_ "GenMsgCycleTime" BO_ 2381907198 1000;
BA_ "SingleFrame" BO_ 2381907198 0;
BA_ "SAE_Document" BO_ 2381184766 "NMEA2000";
BA_ "SingleFrame" BO_ 2381184766 0;
BA_ "SAE_Document" BO_ 2583500030 "NMEA2000";
BA_ "GenMsgCycleTime" BO_ 2583500030 1000;
BA_ "SingleFrame" BO_ 2583500030 0;
BA_ "SAE_Document" BO_ 2583499774 "NMEA2000";
BA_ "GenMsgCycleTime" BO_ 2583499774 1000;
BA_ "SingleFrame" BO_ 2583499774 0;
BA_ "SAE_Document" BO_ 2649823998 "NMEA2000";
BA_ "GenMsgCycleTime" BO_ 2649823998 1000;
BA_ "GenMsgRequestable" BO_ 2649823998 0;
BA_ "SAE_Document" BO_ 2382103806 "NMEA2000";
BA_ "GenMsgCycleTime" BO_ 2382103806 1000;
BA_ "SingleFrame" BO_ 2382103806 0;
BA_ "SAE_Document" BO_ 2382104318 "NMEA2000";
BA_ "GenMsgCycleTime" BO_ 2382104318 1000;
BA_ "SingleFrame" BO_ 2382104318 0;
BA_ "SAE_Document" BO_ 2382104062 "NMEA2000";
BA_ "GenMsgCycleTime" BO_ 2382104062 1000;
BA_ "SingleFrame" BO_ 2382104062 0;
BA_ "SAE_Document" BO_ 2314274302 "NMEA2000";
BA_ "GenMsgCycleTime" BO_ 2314274302 250;
BA_ "SingleFrame" BO_ 2314274302 0;
BA_ "SAE_Document" BO_ 2583299582 "NMEA2000";
BA_ "SingleFrame" BO_ 2583299582 0;
BA_ "SPN" SG_ 2349596414 AEBS2MessageChecksum 5683;
BA_ "SPN" SG_ 2349596414 AEBS2MessageCounter 5682;
BA_ "SigType" SG_ 2349596414 DrvrActvtnDmndFrAdvncdEmrgncyBrk 5;
BA_ "SPN" SG_ 2349596414 DrvrActvtnDmndFrAdvncdEmrgncyBrk 5681;
BA_ "SPN" SG_ 2566767358 FuelType 5837;
BA_ "SigType" SG_ 2566767358 EngFuelMassFlowRate 1;
BA_ "SPN" SG_ 2566767358 EngFuelMassFlowRate 5833;
BA_ "SPN" SG_ 2566767358 EngExhstGsRcrcltn1Valve2PosError 5830;
BA_ "SPN" SG_ 2566767358 EngExhstGsRcrcltn1Valve1PosError 5829;
BA_ "SigType" SG_ 2566706686 Aftrtrtmnt1DslExhstFldPumpHeater 1;
BA_ "SPN" SG_ 2566706686 Aftrtrtmnt1DslExhstFldPumpHeater 5706;
BA_ "SigType" SG_ 2566705406 Aftertreatment2ParticulateSensor 1;
BA_ "SPN" SG_ 2566705406 Aftertreatment2ParticulateSensor 5836;
BA_ "SigType" SG_ 2566705406 Aftertreatment1ParticulateSensor 1;
BA_ "SPN" SG_ 2566705406 Aftertreatment1ParticulateSensor 5835;
BA_ "SPN" SG_ 2566705150 NOxSnsorATI2SelfdiagnosisTrigger 5712;
BA_ "SPN" SG_ 2566705150 NOxSnsorATO2SelfdiagnosisTrigger 5711;
BA_ "SPN" SG_ 2566705150 NOxSnsorATI1SelfdiagnosisTrigger 5710;
BA_ "SPN" SG_ 2566705150 NOxSnsorATO1SelfdiagnosisTrigger 5709;
BA_ "SigType" SG_ 2566704382 Aftrtrtmnt2OtltGsSnsrPowerSupply 5;
BA_ "SPN" SG_ 2566704382 Aftrtrtmnt2OtltGsSnsrPowerSupply 5761;
BA_ "SigType" SG_ 2566704382 Aftrtrtmnt2IntkGsSnsrPowerSupply 5;
BA_ "SPN" SG_ 2566704382 Aftrtrtmnt2IntkGsSnsrPowerSupply 5760;
BA_ "SigType" SG_ 2566704382 Aftrtrtmnt1OtltGsSnsrPowerSupply 5;
BA_ "SPN" SG_ 2566704382 Aftrtrtmnt1OtltGsSnsrPowerSupply 5759;
BA_ "SigType" SG_ 2566704382 Aftrtrtmnt1IntkGsSnsrPowerSupply 5;
BA_ "SPN" SG_ 2566704382 Aftrtrtmnt1IntkGsSnsrPowerSupply 5758;
BA_ "SPN" SG_ 2566704126 EngExhstGsRcrcltn1Acttr2PrlmnryF 5767;
BA_ "SPN" SG_ 2566704126 EngExhstGsRcrcltn1Acttr2OprtnStt 5772;
BA_ "SPN" SG_ 2566704126 EngExhstGsRcrcltn1Acttr1OprtnStt 5771;
BA_ "SPN" SG_ 2566704126 EngExhstGsRcrcltn1Acttr2DsredPos 5770;
BA_ "SigType" SG_ 2566704126 EngExhstGsRcrclton1Actuator2Temp 1;
BA_ "SPN" SG_ 2566704126 EngExhstGsRcrclton1Actuator2Temp 5769;
BA_ "SPN" SG_ 2566704126 EngExhstGsRcrcltn1Acttr2TmpSttus 5768;
BA_ "SPN" SG_ 2566704126 EngExhstGsRcrcltn1Acttr1DsredPos 5766;
BA_ "SigType" SG_ 2566704126 EngExhstGsRcrclton1Actuator1Temp 1;
BA_ "SPN" SG_ 2566704126 EngExhstGsRcrclton1Actuator1Temp 5765;
BA_ "SPN" SG_ 2566704126 EngExhstGsRcrcltn1Acttr1TmpSttus 5764;
BA_ "SPN" SG_ 2566704126 EngExhstGsRcrcltn1Acttr1PrlmnryF 5763;
BA_ "SPN" SG_ 2566703870 EngExhstGsRcrcltn2Acttr2OprtnStt 5782;
BA_ "SPN" SG_ 2566703870 EngExhstGsRcrcltn2Acttr1OprtnStt 5781;
BA_ "SPN" SG_ 2566703870 EngExhstGsRcrcltn2Acttr2DsredPos 5780;
BA_ "SigType" SG_ 2566703870 EngExhstGsRcrclton2Actuator2Temp 1;
BA_ "SPN" SG_ 2566703870 EngExhstGsRcrclton2Actuator2Temp 5779;
BA_ "SPN" SG_ 2566703870 EngExhstGsRcrcltn2Acttr2TmpSttus 5778;
BA_ "SPN" SG_ 2566703870 EngExhstGsRcrcltn2Acttr2PrlmnryF 5777;
BA_ "SPN" SG_ 2566703870 EngExhstGsRcrcltn2Acttr1DsredPos 5776;
BA_ "SigType" SG_ 2566703870 EngExhstGsRcrclton2Actuator1Temp 1;
BA_ "SPN" SG_ 2566703870 EngExhstGsRcrclton2Actuator1Temp 5775;
BA_ "SPN" SG_ 2566703870 EngExhstGsRcrcltn2Acttr1TmpSttus 5774;
BA_ "SPN" SG_ 2566703870 EngExhstGsRcrcltn2Acttr1PrlmnryF 5773;
BA_ "SigType" SG_ 2566703614 EngTurboWastegateActuator2Temp 1;
BA_ "SPN" SG_ 2566703614 EngTurboWastegateActuator2Temp 5787;
BA_ "SigType" SG_ 2566703614 EngFuelValve2Temp 1;
BA_ "SPN" SG_ 2566703614 EngFuelValve2Temp 5786;
BA_ "SigType" SG_ 2566703614 EngFuelValve1Temp 1;
BA_ "SPN" SG_ 2566703614 EngFuelValve1Temp 5785;
BA_ "SigType" SG_ 2566703614 EngThrottleValve2Temp 1;
BA_ "SPN" SG_ 2566703614 EngThrottleValve2Temp 5784;
BA_ "SigType" SG_ 2566703614 EngThrottleValve1Temp 1;
BA_ "SPN" SG_ 2566703614 EngThrottleValve1Temp 5783;
BA_ "SPN" SG_ 2566703358 EngFuelingInhibitPreventedReason 5866;
BA_ "SigType" SG_ 2566703358 EngFuelingInhibitAllowed 5;
BA_ "SPN" SG_ 2566703358 EngFuelingInhibitAllowed 5795;
BA_ "SigType" SG_ 2566703358 FeedbackEngFuelingState 5;
BA_ "SPN" SG_ 2566703358 FeedbackEngFuelingState 5794;
BA_ "SPN" SG_ 2566702590 Aftrtrtmnt1SCRIntrmdtGsTmpPrlmnr 5863;
BA_ "SigType" SG_ 2566702590 Aftrtrtmnt1SCRIntrmediateGasTemp 1;
BA_ "SPN" SG_ 2566702590 Aftrtrtmnt1SCRIntrmediateGasTemp 5862;
BA_ "SPN" SG_ 2566702334 Aftrtrtmnt2SCRIntrmdtGsTmpPrlmnr 5865;
BA_ "SigType" SG_ 2566702334 Aftrtrtmnt2SCRIntrmediateGasTemp 1;
BA_ "SPN" SG_ 2566702334 Aftrtrtmnt2SCRIntrmediateGasTemp 5864;
BA_ "SigType" SG_ 2566702078 SupplyGasMethanePercentage 1;
BA_ "SPN" SG_ 2566702078 SupplyGasMethanePercentage 5867;
BA_ "SigType" SG_ 2566701822 HybridSystemStopIndicator 5;
BA_ "SPN" SG_ 2566701822 HybridSystemStopIndicator 5874;
BA_ "SigType" SG_ 2566701822 HybridSystemOverheatIndicator 5;
BA_ "SPN" SG_ 2566701822 HybridSystemOverheatIndicator 5873;
BA_ "SigType" SG_ 2566701822 HybridSystemWarningIndicator 5;
BA_ "SPN" SG_ 2566701822 HybridSystemWarningIndicator 5872;
BA_ "SigType" SG_ 2431661310 Aftrtrtmnt2SCRIntrmdtNH3GsSn5861 5;
BA_ "SPN" SG_ 2431661310 Aftrtrtmnt2SCRIntrmdtNH3GsSn5861 5861;
BA_ "SPN" SG_ 2431661310 Aftrtrtmnt2SCRIntrmdtNH3GsSnsrHt 5860;
BA_ "SPN" SG_ 2431661310 Aftrtrtmnt2SCRIntrmdtNH3GsSnsrAt 5859;
BA_ "SigType" SG_ 2431661310 Aftrtrtmnt2SCRIntrmdtNH3GsSnsrPw 5;
BA_ "SPN" SG_ 2431661310 Aftrtrtmnt2SCRIntrmdtNH3GsSnsrPw 5858;
BA_ "SigType" SG_ 2431661310 Aftrtrtmnt2SCRIntrmdtNH3RdngStbl 5;
BA_ "SPN" SG_ 2431661310 Aftrtrtmnt2SCRIntrmdtNH3RdngStbl 5857;
BA_ "SPN" SG_ 2431661310 Aftrtrtmnt2SCRIntrmdtNH3SnsrPrlm 5856;
BA_ "SigType" SG_ 2431661310 Aftrtreatment2SCRIntermediateNH3 1;
BA_ "SPN" SG_ 2431661310 Aftrtreatment2SCRIntermediateNH3 5855;
BA_ "SigType" SG_ 2431661054 Aftrtrtmnt1SCRIntrmdtNH3GsSn5854 5;
BA_ "SPN" SG_ 2431661054 Aftrtrtmnt1SCRIntrmdtNH3GsSn5854 5854;
BA_ "SPN" SG_ 2431661054 Aftrtrtmnt1SCRIntrmdtNH3GsSnsrHt 5853;
BA_ "SigType" SG_ 2431661054 Aftrtrtmnt1SCRIntrmdtNH3GsSnsrAt 5;
BA_ "SPN" SG_ 2431661054 Aftrtrtmnt1SCRIntrmdtNH3GsSnsrAt 5852;
BA_ "SigType" SG_ 2431661054 Aftrtrtmnt1SCRIntrmdtNH3GsSnsrPw 5;
BA_ "SPN" SG_ 2431661054 Aftrtrtmnt1SCRIntrmdtNH3GsSnsrPw 5851;
BA_ "SigType" SG_ 2431661054 Aftrtrtmnt1SCRIntrmdtNH3RdngStbl 5;
BA_ "SPN" SG_ 2431661054 Aftrtrtmnt1SCRIntrmdtNH3RdngStbl 5850;
BA_ "SPN" SG_ 2431661054 Aftrtrtmnt1SCRIntrmdtNH3SnsrPrlm 5849;
BA_ "SigType" SG_ 2431661054 Aftrtreatment1SCRIntermediateNH3 1;
BA_ "SPN" SG_ 2431661054 Aftrtreatment1SCRIntermediateNH3 5848;
BA_ "SigType" SG_ 2230334206 LnrDsplcmntSnsrSnsrFigureOfMerit 5;
BA_ "SPN" SG_ 2230334206 LnrDsplcmntSnsrSnsrFigureOfMerit 5824;
BA_ "SigType" SG_ 2230334206 MeasuredLinearDisplacement 1;
BA_ "SPN" SG_ 2230334206 MeasuredLinearDisplacement 5823;
BA_ "SigType" SG_ 2230333950 WandSensorFigureOfMerit 5;
BA_ "SPN" SG_ 2230333950 WandSensorFigureOfMerit 5822;
BA_ "SigType" SG_ 2230333950 WandAngle 1;
BA_ "SPN" SG_ 2230333950 WandAngle 5821;
BA_ "SigType" SG_ 2364551422 WirelessSignalStrength 1;
BA_ "SPN" SG_ 2364551422 WirelessSignalStrength 5753;
BA_ "SPN" SG_ 2364551422 TransmitterID 5752;
BA_ "SPN" SG_ 2364551422 TransmitterCmdState 5751;
BA_ "SPN" SG_ 2364551422 WirelessRollingMessageCounter 5750;
BA_ "SPN" SG_ 2364551166 TmeToCollisionWithRelevantObject 5680;
BA_ "SPN" SG_ 2364551166 BndOffPrbabilityOfRelevantObject 5679;
BA_ "SPN" SG_ 2364551166 RlvntObjctDtctdFrAdvncdEmrgncyBr 5678;
BA_ "SPN" SG_ 2364551166 CollisionWarningStatus 5677;
BA_ "SPN" SG_ 2364551166 AdvncdEmrgencyBrakingSystemState 5676;
BA_ "SPN" SG_ 2566730238 Fan2DriveBypassCmdStatus 1708;
BA_ "SigType" SG_ 2566730238 HydFan2MotorPress 1;
BA_ "SPN" SG_ 2566730238 HydFan2MotorPress 1707;
BA_ "SigType" SG_ 2566730238 Fan2Speed 1;
BA_ "SPN" SG_ 2566730238 Fan2Speed 1598;
BA_ "SPN" SG_ 2566730238 Fan2DriveState 1557;
BA_ "SPN" SG_ 2566730238 EstPercentFan2Speed 1550;
BA_ "SigType" SG_ 2566711038 LubricationTimingCycleStatus 5;
BA_ "SPN" SG_ 2566711038 LubricationTimingCycleStatus 5520;
BA_ "SigType" SG_ 2566711038 LubricationReservoirLevel 4;
BA_ "SPN" SG_ 2566711038 LubricationReservoirLevel 5519;
BA_ "SigType" SG_ 2566711038 LubricationPumpEnableStatus 5;
BA_ "SPN" SG_ 2566711038 LubricationPumpEnableStatus 5518;
BA_ "SPN" SG_ 2566711038 LubricationOperationModeStatus 5517;
BA_ "SPN" SG_ 2566711038 LubricationCycleModeStatus 5516;
BA_ "SigType" SG_ 2566711038 LubricationCycleModeLockStatus 5;
BA_ "SPN" SG_ 2566711038 LubricationCycleModeLockStatus 5515;
BA_ "SigType" SG_ 2566710782 HydOilTemp 1;
BA_ "SPN" SG_ 2566710782 HydOilTemp 5536;
BA_ "SigType" SG_ 2566710782 HydOilRelativeDielectricity 1;
BA_ "SPN" SG_ 2566710782 HydOilRelativeDielectricity 5535;
BA_ "SigType" SG_ 2566710782 HydOilDensity 1;
BA_ "SPN" SG_ 2566710782 HydOilDensity 5534;
BA_ "SigType" SG_ 2566710782 HydOilDynamicViscosity 1;
BA_ "SPN" SG_ 2566710782 HydOilDynamicViscosity 5533;
BA_ "SigType" SG_ 2566710526 EngFuelTemp 1;
BA_ "SPN" SG_ 2566710526 EngFuelTemp 5540;
BA_ "SigType" SG_ 2566710526 EngFuelDielectricity 1;
BA_ "SPN" SG_ 2566710526 EngFuelDielectricity 5539;
BA_ "SigType" SG_ 2566710526 EngFuelDensity 1;
BA_ "SPN" SG_ 2566710526 EngFuelDensity 5538;
BA_ "SigType" SG_ 2566710526 EngFuelDynamicViscosity 1;
BA_ "SPN" SG_ 2566710526 EngFuelDynamicViscosity 5537;
BA_ "SigType" SG_ 2432492542 DsredEngTurbo2TurbineOutletPress 1;
BA_ "SPN" SG_ 2432492542 DsredEngTurbo2TurbineOutletPress 5545;
BA_ "SigType" SG_ 2432492542 EngTurbo2TurbineOutletPress 1;
BA_ "SPN" SG_ 2432492542 EngTurbo2TurbineOutletPress 5544;
BA_ "SigType" SG_ 2432492542 EngExhaustBrakeActuatorCmd 1;
BA_ "SPN" SG_ 2432492542 EngExhaustBrakeActuatorCmd 5543;
BA_ "SigType" SG_ 2432492542 DsredEngTurbo1TurbineOutletPress 1;
BA_ "SPN" SG_ 2432492542 DsredEngTurbo1TurbineOutletPress 5542;
BA_ "SigType" SG_ 2432492542 EngTurbo1TurbineOutletPress 1;
BA_ "SPN" SG_ 2432492542 EngTurbo1TurbineOutletPress 5541;
BA_ "SigType" SG_ 2566710014 SupplementalFanPower 1;
BA_ "SPN" SG_ 2566710014 SupplementalFanPower 5564;
BA_ "SigType" SG_ 2566710014 SupplementalFanCurrent 1;
BA_ "SPN" SG_ 2566710014 SupplementalFanCurrent 5563;
BA_ "SigType" SG_ 2566710014 SupplementalFanSpeed 1;
BA_ "SPN" SG_ 2566710014 SupplementalFanSpeed 5562;
BA_ "SigType" SG_ 2566710014 SupplementalFanCtrlECUTemp 1;
BA_ "SPN" SG_ 2566710014 SupplementalFanCtrlECUTemp 5561;
BA_ "SPN" SG_ 2566710014 SupplementalFanDriveStatus 5560;
BA_ "SPN" SG_ 2566710014 SupplementalFanCtrlTempStatus 5559;
BA_ "SPN" SG_ 2566710014 SupplementalFanVelocityStatus 5558;
BA_ "SigType" SG_ 2566710014 SupplementalFanDirectionStatus 5;
BA_ "SPN" SG_ 2566710014 SupplementalFanDirectionStatus 5557;
BA_ "SigType" SG_ 2566710014 SupplementalFanEnableStatus 5;
BA_ "SPN" SG_ 2566710014 SupplementalFanEnableStatus 5556;
BA_ "SigType" SG_ 2566709758 HighResolutionEngFuelRate 1;
BA_ "SPN" SG_ 2566709758 HighResolutionEngFuelRate 1600;
BA_ "SigType" SG_ 2566709502 Aftertreatment2FuelMassRate 1;
BA_ "SPN" SG_ 2566709502 Aftertreatment2FuelMassRate 5834;
BA_ "SigType" SG_ 2566709502 Aftertreatment1FuelMassRate 1;
BA_ "SPN" SG_ 2566709502 Aftertreatment1FuelMassRate 5503;
BA_ "SigType" SG_ 2566709502 RelativeUnburnedFuelMassFromEng 1;
BA_ "SPN" SG_ 2566709502 RelativeUnburnedFuelMassFromEng 5502;
BA_ "SPN" SG_ 2566709502 Aftrtrtmnt1DslPrtcltFltrIntkTmpS 5501;
BA_ "SPN" SG_ 2566709246 EngFuelFilterDegradation 5584;
BA_ "SigType" SG_ 2566709246 EngFilteredFuelDeliveryAbsPress 1;
BA_ "SPN" SG_ 2566709246 EngFilteredFuelDeliveryAbsPress 5580;
BA_ "SigType" SG_ 2566709246 EngFilteredFuelDeliveryPress 1;
BA_ "SPN" SG_ 2566709246 EngFilteredFuelDeliveryPress 5579;
BA_ "SigType" SG_ 2566709246 EngFuelDeliveryAbsPress 1;
BA_ "SPN" SG_ 2566709246 EngFuelDeliveryAbsPress 5578;
BA_ "SigType" SG_ 2566708990 Aftertreatment1SecondAirAbsPress 1;
BA_ "SPN" SG_ 2566708990 Aftertreatment1SecondAirAbsPress 5589;
BA_ "SigType" SG_ 2566708734 Aftertreatment2SecondAirAbsPress 1;
BA_ "SPN" SG_ 2566708734 Aftertreatment2SecondAirAbsPress 5590;
BA_ "SPN" SG_ 2566708478 SrcAddrssOfCntrllngDvcFrPsngCrsC 5609;
BA_ "SPN" SG_ 2566708478 SrcAddrssOfCntrllngDvcFrDsblngCr 5608;
BA_ "SPN" SG_ 2566708478 CruiseCtrlSystemCmdState 5607;
BA_ "SigType" SG_ 2566708478 AdptiveCruiseCtrlReadinessStatus 5;
BA_ "SPN" SG_ 2566708478 AdptiveCruiseCtrlReadinessStatus 5606;
BA_ "SPN" SG_ 2566708222 Aftrtrtmnt1DslPrtcltFltr1StS5635 5635;
BA_ "SPN" SG_ 2566708222 Aftrtrtmnt1DslPrtcltFltr1StS5634 5634;
BA_ "SPN" SG_ 2566708222 Aftrtrtmnt1DslPrtcltFltr1StS5633 5633;
BA_ "SPN" SG_ 2566708222 Aftrtrtmnt1DslPrtcltFltr1StSnsrA 5640;
BA_ "SPN" SG_ 2566707966 Aftrtrtmnt1DslPrtcltFltr1StS5639 5639;
BA_ "SPN" SG_ 2566707966 Aftrtrtmnt1DslPrtcltFltr1StS5638 5638;
BA_ "SPN" SG_ 2566707966 Aftrtrtmnt1DslPrtcltFltr1StSnsrF 5641;
BA_ "SPN" SG_ 2566707966 Aftrtrtmnt1DslPrtcltFltr1StSnsrA 5640;
BA_ "SPN" SG_ 2566707710 Aftrtrtmnt1DslPrtcltFltr1StS5643 5643;
BA_ "SPN" SG_ 2566707710 Aftrtrtmnt1DslPrtcltFltr1StS5642 5642;
BA_ "SPN" SG_ 2566707710 Aftrtrtmnt1DslPrtcltFltr1StSnsrF 5641;
BA_ "SPN" SG_ 2566707710 Aftrtrtmnt1DslPrtcltFltr1StSnsrA 5640;
BA_ "SAEDocument" SG_ 2315059966 WindReference "NMEA2000";
BA_ "SAEDocument" SG_ 2315059966 WindDirection "NMEA2000";
BA_ "SigType" SG_ 2315059966 WindDirection 1;
BA_ "DDI" SG_ 2315059966 WindDirection 208;
BA_ "SAEDocument" SG_ 2315059966 WindSpeed "NMEA2000";
BA_ "SigType" SG_ 2315059966 WindSpeed 1;
BA_ "DDI" SG_ 2315059966 WindSpeed 207;
BA_ "SAEDocument" SG_ 2315059966 SequenceID_ "NMEA2000";
BA_ "SigType" SG_ 2315059966 SequenceID_ 1;
BA_ "SAEDocument" SG_ 2381646846 Offset "NMEA2000";
BA_ "SigType" SG_ 2381646846 Offset 2;
BA_ "SAEDocument" SG_ 2381646846 WaterDepthTransducer "NMEA2000";
BA_ "SigType" SG_ 2381646846 WaterDepthTransducer 1;
BA_ "SAEDocument" SG_ 2381646846 SID "NMEA2000";
BA_ "SigType" SG_ 2381646846 SID 1;
BA_ "SAEDocument" SG_ 2315129598 SternSpeedGroundreferenced "NMEA2000";
BA_ "SigType" SG_ 2315129598 SternSpeedGroundreferenced 2;
BA_ "SAEDocument" SG_ 2315129598 SternSpeedWaterreferenced "NMEA2000";
BA_ "SigType" SG_ 2315129598 SternSpeedWaterreferenced 2;
BA_ "SAEDocument" SG_ 2315129598 TransverseSpeedGroundreferenced "NMEA2000";
BA_ "SigType" SG_ 2315129598 TransverseSpeedGroundreferenced 2;
BA_ "SAEDocument" SG_ 2315129598 LngtudinalSpeedGroundreferenced "NMEA2000";
BA_ "SigType" SG_ 2315129598 LngtudinalSpeedGroundreferenced 2;
BA_ "SAEDocument" SG_ 2315129598 TransverseSpeedWaterreferenced "NMEA2000";
BA_ "SigType" SG_ 2315129598 TransverseSpeedWaterreferenced 2;
BA_ "SAEDocument" SG_ 2315129598 LngitudinalSpeedWaterreferenced "NMEA2000";
BA_ "SigType" SG_ 2315129598 LngitudinalSpeedWaterreferenced 2;
BA_ "SAEDocument" SG_ 2314277630 HeadingSensorReference "NMEA2000";
BA_ "SigType" SG_ 2314277630 HeadingSensorReference 4;
BA_ "SAEDocument" SG_ 2314277630 Variation "NMEA2000";
BA_ "SigType" SG_ 2314277630 Variation 2;
BA_ "SAEDocument" SG_ 2314277630 Deviation "NMEA2000";
BA_ "SigType" SG_ 2314277630 Deviation 2;
BA_ "SAEDocument" SG_ 2314277630 HeadingSensorReading "NMEA2000";
BA_ "SigType" SG_ 2314277630 HeadingSensorReading 1;
BA_ "SAEDocument" SG_ 2314277630 SID "NMEA2000";
BA_ "SigType" SG_ 2314277630 SID 1;
BA_ "SAEDocument" SG_ 2583172606 DatumName "NMEA2000";
BA_ "SigType" SG_ 2583172606 DatumName 1;
BA_ "SAEDocument" SG_ 2583172606 EllipsoidFlatteningInverse "NMEA2000";
BA_ "SigType" SG_ 2583172606 EllipsoidFlatteningInverse 2;
BA_ "SAEDocument" SG_ 2583172606 EllipsoidSemimajorAxis "NMEA2000";
BA_ "SigType" SG_ 2583172606 EllipsoidSemimajorAxis 2;
BA_ "SAEDocument" SG_ 2583172606 Scale "NMEA2000";
BA_ "SigType" SG_ 2583172606 Scale 2;
BA_ "SAEDocument" SG_ 2583172606 RotationInZ "NMEA2000";
BA_ "SigType" SG_ 2583172606 RotationInZ 2;
BA_ "SAEDocument" SG_ 2583172606 RotationInY "NMEA2000";
BA_ "SigType" SG_ 2583172606 RotationInY 2;
BA_ "SAEDocument" SG_ 2583172606 RotationInX "NMEA2000";
BA_ "SigType" SG_ 2583172606 RotationInX 2;
BA_ "SAEDocument" SG_ 2583172606 DeltaZ "NMEA2000";
BA_ "SigType" SG_ 2583172606 DeltaZ 2;
BA_ "SAEDocument" SG_ 2583172606 DeltaY "NMEA2000";
BA_ "SigType" SG_ 2583172606 DeltaY 2;
BA_ "SAEDocument" SG_ 2583172606 DeltaX "NMEA2000";
BA_ "SigType" SG_ 2583172606 DeltaX 2;
BA_ "SAEDocument" SG_ 2515667198 TripRunTime "NMEA2000";
BA_ "SigType" SG_ 2515667198 TripRunTime 1;
BA_ "SAEDocument" SG_ 2515667198 EstFuelRemaining "NMEA2000";
BA_ "SigType" SG_ 2515667198 EstFuelRemaining 1;
BA_ "SAEDocument" SG_ 2515667198 DistanceToEmpty "NMEA2000";
BA_ "SigType" SG_ 2515667198 DistanceToEmpty 1;
BA_ "SAEDocument" SG_ 2515667198 TimeToEmpty "NMEA2000";
BA_ "SigType" SG_ 2515667198 TimeToEmpty 1;
BA_ "SAEDocument" SG_ 2515667454 InstantaneousFuelEconomy "NMEA2000";
BA_ "SigType" SG_ 2515667454 InstantaneousFuelEconomy 2;
BA_ "SAEDocument" SG_ 2515667454 FuelRateEconomy "NMEA2000";
BA_ "SigType" SG_ 2515667454 FuelRateEconomy 2;
BA_ "SAEDocument" SG_ 2515667454 FuelRateAverage "NMEA2000";
BA_ "SigType" SG_ 2515667454 FuelRateAverage 2;
BA_ "SAEDocument" SG_ 2515667454 TripFuelUsed "NMEA2000";
BA_ "SigType" SG_ 2515667454 TripFuelUsed 1;
BA_ "SAEDocument" SG_ 2515667454 EngInstance "NMEA2000";
BA_ "SigType" SG_ 2515667454 EngInstance 1;
BA_ "SAEDocument" SG_ 2314339838 TransDiscreteStatus "NMEA2000";
BA_ "SigType" SG_ 2314339838 TransDiscreteStatus 1;
BA_ "SAEDocument" SG_ 2314339838 TransOilTemp_ "NMEA2000";
BA_ "SigType" SG_ 2314339838 TransOilTemp_ 1;
BA_ "SAEDocument" SG_ 2314339838 TransOilPress_ "NMEA2000";
BA_ "SigType" SG_ 2314339838 TransOilPress_ 1;
BA_ "SAEDocument" SG_ 2314339838 TransGear "NMEA2000";
BA_ "SAEDocument" SG_ 2314339838 TransInstance "NMEA2000";
BA_ "SigType" SG_ 2314339838 TransInstance 1;
BA_ "SAEDocument" SG_ 2314602750 CPA "NMEA2000";
BA_ "SigType" SG_ 2314602750 CPA 2;
BA_ "SAEDocument" SG_ 2314602750 Speed "NMEA2000";
BA_ "SigType" SG_ 2314602750 Speed 1;
BA_ "SAEDocument" SG_ 2314602750 Course "NMEA2000";
BA_ "SigType" SG_ 2314602750 Course 1;
BA_ "SAEDocument" SG_ 2314602750 Distance "NMEA2000";
BA_ "SigType" SG_ 2314602750 Distance 2;
BA_ "SAEDocument" SG_ 2314602750 Bearing "NMEA2000";
BA_ "SigType" SG_ 2314602750 Bearing 1;
BA_ "SAEDocument" SG_ 2314602750 BearingReference "NMEA2000";
BA_ "SAEDocument" SG_ 2314602750 TrackStatus "NMEA2000";
BA_ "SAEDocument" SG_ 2314602750 TargetID "NMEA2000";
BA_ "SigType" SG_ 2314602750 TargetID 1;
BA_ "SAEDocument" SG_ 2314602750 SequenceID_ "NMEA2000";
BA_ "SigType" SG_ 2314602750 SequenceID_ 1;
BA_ "SAEDocument" SG_ 2314602750 Name "NMEA2000";
BA_ "SigType" SG_ 2314602750 Name 1;
BA_ "SAEDocument" SG_ 2314602750 UTCOfFix "NMEA2000";
BA_ "SigType" SG_ 2314602750 UTCOfFix 1;
BA_ "SAEDocument" SG_ 2314602750 TCPA "NMEA2000";
BA_ "SigType" SG_ 2314602750 TCPA 2;
BA_ "SAEDocument" SG_ 2381842942 LocalOffsetMinutes "NMEA2000";
BA_ "SigType" SG_ 2381842942 LocalOffsetMinutes 2;
BA_ "SAEDocument" SG_ 2381842942 Time "NMEA2000";
BA_ "SigType" SG_ 2381842942 Time 1;
BA_ "SAEDocument" SG_ 2381842942 Date "NMEA2000";
BA_ "SigType" SG_ 2381842942 Date 1;
BA_ "SAEDocument" SG_ 2381911550 MarkID "NMEA2000";
BA_ "SigType" SG_ 2381911550 MarkID 1;
BA_ "SAEDocument" SG_ 2381911550 MarkType "NMEA2000";
BA_ "SAEDocument" SG_ 2381911550 TimeElapsedTogoToMark "NMEA2000";
BA_ "SigType" SG_ 2381911550 TimeElapsedTogoToMark 2;
BA_ "SAEDocument" SG_ 2381911550 SID "NMEA2000";
BA_ "SigType" SG_ 2381911550 SID 1;
BA_ "SAEDocument" SG_ 2583499006 StationIDString "NMEA2000";
BA_ "SigType" SG_ 2583499006 StationIDString 1;
BA_ "SAEDocument" SG_ 2583499006 TideLevelStandardDeviation "NMEA2000";
BA_ "SigType" SG_ 2583499006 TideLevelStandardDeviation 1;
BA_ "SAEDocument" SG_ 2583499006 TideLevel "NMEA2000";
BA_ "SigType" SG_ 2583499006 TideLevel 2;
BA_ "SAEDocument" SG_ 2583499006 StationLocationLongitude "NMEA2000";
BA_ "SigType" SG_ 2583499006 StationLocationLongitude 2;
BA_ "SAEDocument" SG_ 2583499006 StationLocationLatitude "NMEA2000";
BA_ "SigType" SG_ 2583499006 StationLocationLatitude 2;
BA_ "SAEDocument" SG_ 2583499006 MeasurementTime "NMEA2000";
BA_ "SigType" SG_ 2583499006 MeasurementTime 1;
BA_ "SAEDocument" SG_ 2583499006 MeasurementDate "NMEA2000";
BA_ "SigType" SG_ 2583499006 MeasurementDate 1;
BA_ "SAEDocument" SG_ 2583499006 TideTendency "NMEA2000";
BA_ "SigType" SG_ 2583499006 TideTendency 4;
BA_ "SAEDocument" SG_ 2583499006 Mode "NMEA2000";
BA_ "SAEDocument" SG_ 2381320446 Time "NMEA2000";
BA_ "SigType" SG_ 2381320446 Time 1;
BA_ "SAEDocument" SG_ 2381320446 Date "NMEA2000";
BA_ "SigType" SG_ 2381320446 Date 1;
BA_ "SAEDocument" SG_ 2381320446 Source "NMEA2000";
BA_ "SAEDocument" SG_ 2381320446 SID "NMEA2000";
BA_ "SigType" SG_ 2381320446 SID 1;
BA_ "SAEDocument" SG_ 2381451006 Switch28 "NMEA2000";
BA_ "SigType" SG_ 2381451006 Switch28 4;
BA_ "SAEDocument" SG_ 2381451006 Switch27 "NMEA2000";
BA_ "SigType" SG_ 2381451006 Switch27 4;
BA_ "SAEDocument" SG_ 2381451006 Switch26 "NMEA2000";
BA_ "SigType" SG_ 2381451006 Switch26 4;
BA_ "SAEDocument" SG_ 2381451006 Switch25 "NMEA2000";
BA_ "SigType" SG_ 2381451006 Switch25 4;
BA_ "SAEDocument" SG_ 2381451006 Switch24 "NMEA2000";
BA_ "SigType" SG_ 2381451006 Switch24 4;
BA_ "SAEDocument" SG_ 2381451006 Switch23 "NMEA2000";
BA_ "SigType" SG_ 2381451006 Switch23 4;
BA_ "SAEDocument" SG_ 2381451006 Switch22 "NMEA2000";
BA_ "SigType" SG_ 2381451006 Switch22 4;
BA_ "SAEDocument" SG_ 2381451006 Switch21 "NMEA2000";
BA_ "SigType" SG_ 2381451006 Switch21 4;
BA_ "SAEDocument" SG_ 2381451006 Switch20 "NMEA2000";
BA_ "SigType" SG_ 2381451006 Switch20 4;
BA_ "SAEDocument" SG_ 2381451006 Switch19 "NMEA2000";
BA_ "SigType" SG_ 2381451006 Switch19 4;
BA_ "SAEDocument" SG_ 2381451006 Switch18 "NMEA2000";
BA_ "SigType" SG_ 2381451006 Switch18 4;
BA_ "SAEDocument" SG_ 2381451006 Switch17 "NMEA2000";
BA_ "SigType" SG_ 2381451006 Switch17 4;
BA_ "SAEDocument" SG_ 2381451006 Switch16 "NMEA2000";
BA_ "SigType" SG_ 2381451006 Switch16 4;
BA_ "SAEDocument" SG_ 2381451006 Switch15 "NMEA2000";
BA_ "SigType" SG_ 2381451006 Switch15 4;
BA_ "SAEDocument" SG_ 2381451006 Switch14 "NMEA2000";
BA_ "SigType" SG_ 2381451006 Switch14 4;
BA_ "SAEDocument" SG_ 2381451006 Switch13 "NMEA2000";
BA_ "SigType" SG_ 2381451006 Switch13 4;
BA_ "SAEDocument" SG_ 2381451006 Switch12 "NMEA2000";
BA_ "SigType" SG_ 2381451006 Switch12 4;
BA_ "SAEDocument" SG_ 2381451006 Switch11 "NMEA2000";
BA_ "SigType" SG_ 2381451006 Switch11 4;
BA_ "SAEDocument" SG_ 2381451006 Switch10 "NMEA2000";
BA_ "SigType" SG_ 2381451006 Switch10 4;
BA_ "SAEDocument" SG_ 2381451006 Switch9 "NMEA2000";
BA_ "SigType" SG_ 2381451006 Switch9 4;
BA_ "SAEDocument" SG_ 2381451006 Switch8 "NMEA2000";
BA_ "SigType" SG_ 2381451006 Switch8 4;
BA_ "SAEDocument" SG_ 2381451006 Switch7 "NMEA2000";
BA_ "SigType" SG_ 2381451006 Switch7 4;
BA_ "SAEDocument" SG_ 2381451006 Switch6 "NMEA2000";
BA_ "SigType" SG_ 2381451006 Switch6 4;
BA_ "SAEDocument" SG_ 2381451006 Switch5 "NMEA2000";
BA_ "SigType" SG_ 2381451006 Switch5 4;
BA_ "SAEDocument" SG_ 2381451006 Switch4 "NMEA2000";
BA_ "SigType" SG_ 2381451006 Switch4 4;
BA_ "SAEDocument" SG_ 2381451006 Switch3 "NMEA2000";
BA_ "SigType" SG_ 2381451006 Switch3 4;
BA_ "SAEDocument" SG_ 2381451006 Switch2 "NMEA2000";
BA_ "SigType" SG_ 2381451006 Switch2 4;
BA_ "SAEDocument" SG_ 2381451006 Switch1 "NMEA2000";
BA_ "SigType" SG_ 2381451006 Switch1 4;
BA_ "SAEDocument" SG_ 2381451006 SwitchBankInstance "NMEA2000";
BA_ "SigType" SG_ 2381451006 SwitchBankInstance 1;
BA_ "SAEDocument" SG_ 2314535934 SpeedGroundReferenced "NMEA2000";
BA_ "SigType" SG_ 2314535934 SpeedGroundReferenced 1;
BA_ "SAEDocument" SG_ 2314535934 SpeedWaterReferenced "NMEA2000";
BA_ "SigType" SG_ 2314535934 SpeedWaterReferenced 1;
BA_ "SAEDocument" SG_ 2314535934 SequenceID_ "NMEA2000";
BA_ "SigType" SG_ 2314535934 SequenceID_ 1;
BA_ "SAEDocument" SG_ 2315129086 StarboardTrimTab "NMEA2000";
BA_ "SigType" SG_ 2315129086 StarboardTrimTab 2;
BA_ "SAEDocument" SG_ 2315129086 PortTrimTab "NMEA2000";
BA_ "SigType" SG_ 2315129086 PortTrimTab 2;
BA_ "SAEDocument" SG_ 2381908990 Drift "NMEA2000";
BA_ "SigType" SG_ 2381908990 Drift 1;
BA_ "SAEDocument" SG_ 2381908990 Set "NMEA2000";
BA_ "SigType" SG_ 2381908990 Set 1;
BA_ "SAEDocument" SG_ 2381908990 SetReference "NMEA2000";
BA_ "SigType" SG_ 2381908990 SetReference 4;
BA_ "SAEDocument" SG_ 2381908990 SID "NMEA2000";
BA_ "SigType" SG_ 2381908990 SID 1;
BA_ "SAEDocument" SG_ 2583499262 StationIDString "NMEA2000";
BA_ "SigType" SG_ 2583499262 StationIDString 1;
BA_ "SAEDocument" SG_ 2583499262 WaterTemp "NMEA2000";
BA_ "SigType" SG_ 2583499262 WaterTemp 1;
BA_ "SAEDocument" SG_ 2583499262 Salinity "NMEA2000";
BA_ "SigType" SG_ 2583499262 Salinity 2;
BA_ "SAEDocument" SG_ 2583499262 StationLocationLongitude "NMEA2000";
BA_ "SigType" SG_ 2583499262 StationLocationLongitude 2;
BA_ "SAEDocument" SG_ 2583499262 StationLocationLatitude "NMEA2000";
BA_ "SigType" SG_ 2583499262 StationLocationLatitude 2;
BA_ "SAEDocument" SG_ 2583499262 MeasurementTime "NMEA2000";
BA_ "SigType" SG_ 2583499262 MeasurementTime 1;
BA_ "SAEDocument" SG_ 2583499262 MeasurementDate "NMEA2000";
BA_ "SigType" SG_ 2583499262 MeasurementDate 1;
BA_ "SAEDocument" SG_ 2583499262 Mode "NMEA2000";
BA_ "SAEDocument" SG_ 2650544894 WPName "NMEA2000";
BA_ "SigType" SG_ 2650544894 WPName 1;
BA_ "SAEDocument" SG_ 2650544894 WPID "NMEA2000";
BA_ "SigType" SG_ 2650544894 WPID 1;
BA_ "SAEDocument" SG_ 2650544894 reserved "NMEA2000";
BA_ "SigType" SG_ 2650544894 reserved 1;
BA_ "SAEDocument" SG_ 2650544894 DatabaseID "NMEA2000";
BA_ "SigType" SG_ 2650544894 DatabaseID 1;
BA_ "SAEDocument" SG_ 2650544894 NumberOfValidWPsInWPList "NMEA2000";
BA_ "SigType" SG_ 2650544894 NumberOfValidWPsInWPList 1;
BA_ "SAEDocument" SG_ 2650544894 nItems "NMEA2000";
BA_ "SigType" SG_ 2650544894 nItems 1;
BA_ "SAEDocument" SG_ 2650544894 StartWPID "NMEA2000";
BA_ "SigType" SG_ 2650544894 StartWPID 1;
BA_ "SAEDocument" SG_ 2650544382 CommentText "NMEA2000";
BA_ "SigType" SG_ 2650544382 CommentText 1;
BA_ "SAEDocument" SG_ 2650544382 DatabaseID "NMEA2000";
BA_ "SigType" SG_ 2650544382 DatabaseID 1;
BA_ "SAEDocument" SG_ 2650544382 NumberOfDatabasesWithComments "NMEA2000";
BA_ "SigType" SG_ 2650544382 NumberOfDatabasesWithComments 1;
BA_ "SAEDocument" SG_ 2650544382 nItems "NMEA2000";
BA_ "SigType" SG_ 2650544382 nItems 1;
BA_ "SAEDocument" SG_ 2650544382 StartDatabaseID "NMEA2000";
BA_ "SigType" SG_ 2650544382 StartDatabaseID 1;
BA_ "SAEDocument" SG_ 2314276350 Pos "NMEA2000";
BA_ "SigType" SG_ 2314276350 Pos 2;
BA_ "SAEDocument" SG_ 2314276350 Angleder "NMEA2000";
BA_ "SigType" SG_ 2314276350 Angleder 2;
BA_ "SAEDocument" SG_ 2314276350 Directionder "NMEA2000";
BA_ "SAEDocument" SG_ 2314276350 RudderInstance "NMEA2000";
BA_ "SigType" SG_ 2314276350 RudderInstance 1;
BA_ "SAEDocument" SG_ 2650543614 NavMethodInLegAfterWP "NMEA2000";
BA_ "SigType" SG_ 2650543614 NavMethodInLegAfterWP 4;
BA_ "SAEDocument" SG_ 2650543614 XTELimitInLegAfterWP "NMEA2000";
BA_ "SigType" SG_ 2650543614 XTELimitInLegAfterWP 2;
BA_ "SAEDocument" SG_ 2650543614 RPS "NMEA2000";
BA_ "SigType" SG_ 2650543614 RPS 1;
BA_ "SAEDocument" SG_ 2650543614 RouteID "NMEA2000";
BA_ "SigType" SG_ 2650543614 RouteID 1;
BA_ "SAEDocument" SG_ 2650543614 DatabaseID "NMEA2000";
BA_ "SigType" SG_ 2650543614 DatabaseID 1;
BA_ "SAEDocument" SG_ 2650543614 NmbrOfWypntsWthASpcfcXTELmtNvMth "NMEA2000";
BA_ "SigType" SG_ 2650543614 NmbrOfWypntsWthASpcfcXTELmtNvMth 1;
BA_ "SAEDocument" SG_ 2650543614 nItems "NMEA2000";
BA_ "SigType" SG_ 2650543614 nItems 1;
BA_ "SAEDocument" SG_ 2650543614 StartRPS "NMEA2000";
BA_ "SigType" SG_ 2650543614 StartRPS 1;
BA_ "SAEDocument" SG_ 2650542846 Route_WPListName "NMEA2000";
BA_ "SigType" SG_ 2650542846 Route_WPListName 1;
BA_ "SAEDocument" SG_ 2650542846 RouteID "NMEA2000";
BA_ "SigType" SG_ 2650542846 RouteID 1;
BA_ "SAEDocument" SG_ 2650542846 DatabaseID "NMEA2000";
BA_ "SigType" SG_ 2650542846 DatabaseID 1;
BA_ "SAEDocument" SG_ 2650543870 Comment "NMEA2000";
BA_ "SigType" SG_ 2650543870 Comment 1;
BA_ "SAEDocument" SG_ 2650543870 WPID_RPS "NMEA2000";
BA_ "SigType" SG_ 2650543870 WPID_RPS 1;
BA_ "SAEDocument" SG_ 2650543870 RouteID "NMEA2000";
BA_ "SigType" SG_ 2650543870 RouteID 1;
BA_ "SAEDocument" SG_ 2650543870 DatabaseID "NMEA2000";
BA_ "SigType" SG_ 2650543870 DatabaseID 1;
BA_ "SAEDocument" SG_ 2650543870 NumberOfWPsWithComments "NMEA2000";
BA_ "SigType" SG_ 2650543870 NumberOfWPsWithComments 1;
BA_ "SAEDocument" SG_ 2650543870 nItems "NMEA2000";
BA_ "SigType" SG_ 2650543870 nItems 1;
BA_ "SAEDocument" SG_ 2650543870 StartID "NMEA2000";
BA_ "SigType" SG_ 2650543870 StartID 1;
BA_ "SAEDocument" SG_ 2650543102 WPName "NMEA2000";
BA_ "SigType" SG_ 2650543102 WPName 1;
BA_ "SAEDocument" SG_ 2650543102 WPID "NMEA2000";
BA_ "SigType" SG_ 2650543102 WPID 1;
BA_ "SAEDocument" SG_ 2650543102 RouteID "NMEA2000";
BA_ "SigType" SG_ 2650543102 RouteID 1;
BA_ "SAEDocument" SG_ 2650543102 DatabaseID "NMEA2000";
BA_ "SigType" SG_ 2650543102 DatabaseID 1;
BA_ "SAEDocument" SG_ 2650543102 NumberOfWPsInRoute "NMEA2000";
BA_ "SigType" SG_ 2650543102 NumberOfWPsInRoute 1;
BA_ "SAEDocument" SG_ 2650543102 nItems "NMEA2000";
BA_ "SigType" SG_ 2650543102 nItems 1;
BA_ "SAEDocument" SG_ 2650543102 StartRPS "NMEA2000";
BA_ "SigType" SG_ 2650543102 StartRPS 1;
BA_ "SAEDocument" SG_ 2650543358 WPName "NMEA2000";
BA_ "SigType" SG_ 2650543358 WPName 1;
BA_ "SAEDocument" SG_ 2650543358 WPID "NMEA2000";
BA_ "SigType" SG_ 2650543358 WPID 1;
BA_ "SAEDocument" SG_ 2650543358 RouteID "NMEA2000";
BA_ "SigType" SG_ 2650543358 RouteID 1;
BA_ "SAEDocument" SG_ 2650543358 DatabaseID "NMEA2000";
BA_ "SigType" SG_ 2650543358 DatabaseID 1;
BA_ "SAEDocument" SG_ 2650543358 NumberOfWPsInRoute "NMEA2000";
BA_ "SigType" SG_ 2650543358 NumberOfWPsInRoute 1;
BA_ "SAEDocument" SG_ 2650543358 nItems "NMEA2000";
BA_ "SigType" SG_ 2650543358 nItems 1;
BA_ "SAEDocument" SG_ 2650543358 StartRPS "NMEA2000";
BA_ "SigType" SG_ 2650543358 StartRPS 1;
BA_ "SAEDocument" SG_ 2650542590 RouteName "NMEA2000";
BA_ "SigType" SG_ 2650542590 RouteName 1;
BA_ "SAEDocument" SG_ 2650542590 RouteID "NMEA2000";
BA_ "SigType" SG_ 2650542590 RouteID 1;
BA_ "SAEDocument" SG_ 2650542590 DatabaseID "NMEA2000";
BA_ "SigType" SG_ 2650542590 DatabaseID 1;
BA_ "SAEDocument" SG_ 2650542590 NmbrOfRoutesAvailableInDatabase "NMEA2000";
BA_ "SigType" SG_ 2650542590 NmbrOfRoutesAvailableInDatabase 1;
BA_ "SAEDocument" SG_ 2650542590 nItems "NMEA2000";
BA_ "SigType" SG_ 2650542590 nItems 1;
BA_ "SAEDocument" SG_ 2650542590 StartRouteID "NMEA2000";
BA_ "SigType" SG_ 2650542590 StartRouteID 1;
BA_ "SAEDocument" SG_ 2650544126 Comment "NMEA2000";
BA_ "SigType" SG_ 2650544126 Comment 1;
BA_ "SAEDocument" SG_ 2650544126 RouteID "NMEA2000";
BA_ "SigType" SG_ 2650544126 RouteID 1;
BA_ "SAEDocument" SG_ 2650544126 DatabaseID "NMEA2000";
BA_ "SigType" SG_ 2650544126 DatabaseID 1;
BA_ "SAEDocument" SG_ 2650544126 NumberOfRoutesWithComments "NMEA2000";
BA_ "SigType" SG_ 2650544126 NumberOfRoutesWithComments 1;
BA_ "SAEDocument" SG_ 2650544126 nItems "NMEA2000";
BA_ "SigType" SG_ 2650544126 nItems 1;
BA_ "SAEDocument" SG_ 2650544126 StartRouteID "NMEA2000";
BA_ "SigType" SG_ 2650544126 StartRouteID 1;
BA_ "SAEDocument" SG_ 2650544638 RadiusOfTurn "NMEA2000";
BA_ "SigType" SG_ 2650544638 RadiusOfTurn 2;
BA_ "SAEDocument" SG_ 2650544638 RPS "NMEA2000";
BA_ "SigType" SG_ 2650544638 RPS 1;
BA_ "SAEDocument" SG_ 2650544638 RouteID "NMEA2000";
BA_ "SigType" SG_ 2650544638 RouteID 1;
BA_ "SAEDocument" SG_ 2650544638 DatabaseID "NMEA2000";
BA_ "SigType" SG_ 2650544638 DatabaseID 1;
BA_ "SAEDocument" SG_ 2650544638 NmbrOfWypntsWthASpcfcRdusOfTurn "NMEA2000";
BA_ "SigType" SG_ 2650544638 NmbrOfWypntsWthASpcfcRdusOfTurn 1;
BA_ "SAEDocument" SG_ 2650544638 nItems "NMEA2000";
BA_ "SigType" SG_ 2650544638 nItems 1;
BA_ "SAEDocument" SG_ 2650544638 StartRPS "NMEA2000";
BA_ "SigType" SG_ 2650544638 StartRPS 1;
BA_ "SAEDocument" SG_ 2650542334 DatabaseName "NMEA2000";
BA_ "SigType" SG_ 2650542334 DatabaseName 1;
BA_ "SAEDocument" SG_ 2650542334 DatabaseID "NMEA2000";
BA_ "SigType" SG_ 2650542334 DatabaseID 1;
BA_ "SAEDocument" SG_ 2650542334 NumberOfDatabasesAvailable "NMEA2000";
BA_ "SigType" SG_ 2650542334 NumberOfDatabasesAvailable 1;
BA_ "SAEDocument" SG_ 2650542334 nItems "NMEA2000";
BA_ "SigType" SG_ 2650542334 nItems 1;
BA_ "SAEDocument" SG_ 2650542334 StartDatabaseID "NMEA2000";
BA_ "SigType" SG_ 2650542334 StartDatabaseID 1;
BA_ "SAEDocument" SG_ 2314277886 RateOfTurn "NMEA2000";
BA_ "SigType" SG_ 2314277886 RateOfTurn 2;
BA_ "SAEDocument" SG_ 2314277886 SequenceID_ "NMEA2000";
BA_ "SigType" SG_ 2314277886 SequenceID_ 1;
BA_ "SAEDocument" SG_ 2382039038 RadioChannel "NMEA2000";
BA_ "SigType" SG_ 2382039038 RadioChannel 1;
BA_ "SAEDocument" SG_ 2382039038 TxFrequency "NMEA2000";
BA_ "SigType" SG_ 2382039038 TxFrequency 1;
BA_ "SAEDocument" SG_ 2382039038 RxFrequency "NMEA2000";
BA_ "SigType" SG_ 2382039038 RxFrequency 1;
BA_ "SAEDocument" SG_ 2314732542 LongitudeDelta "NMEA2000";
BA_ "SigType" SG_ 2314732542 LongitudeDelta 2;
BA_ "SAEDocument" SG_ 2314732542 LatitudeDelta "NMEA2000";
BA_ "SigType" SG_ 2314732542 LatitudeDelta 2;
BA_ "SAEDocument" SG_ 2314732542 TimeDelta "NMEA2000";
BA_ "SigType" SG_ 2314732542 TimeDelta 1;
BA_ "SAEDocument" SG_ 2314732542 SequenceID_ "NMEA2000";
BA_ "SigType" SG_ 2314732542 SequenceID_ 1;
BA_ "SAEDocument" SG_ 2582648062 ManufacturersModelID "NMEA2000";
BA_ "SigType" SG_ 2582648062 ManufacturersModelID 1;
BA_ "SAEDocument" SG_ 2582648062 NMEAManufacturersProductCode "NMEA2000";
BA_ "SigType" SG_ 2582648062 NMEAManufacturersProductCode 1;
BA_ "SAEDocument" SG_ 2582648062 NMEA2000DatabaseVersion "NMEA2000";
BA_ "SigType" SG_ 2582648062 NMEA2000DatabaseVersion 1;
BA_ "SAEDocument" SG_ 2314732030 Longitude_ "NMEA2000";
BA_ "SigType" SG_ 2314732030 Longitude_ 2;
BA_ "SAEDocument" SG_ 2314732030 Latitude_ "NMEA2000";
BA_ "SigType" SG_ 2314732030 Latitude_ 2;
BA_ "SAEDocument" SG_ 2582576894 VrblNmbrOfFldsFldNmber2Repeated2 "NMEA2000";
BA_ "SigType" SG_ 2582576894 VrblNmbrOfFldsFldNmber2Repeated2 1;
BA_ "SAEDocument" SG_ 2582576894 FirstPGNSupported2 "NMEA2000";
BA_ "SigType" SG_ 2582576894 FirstPGNSupported2 6;
BA_ "SAEDocument" SG_ 2582576894 VrblNmbrOfFldsFldNmber2Repeated "NMEA2000";
BA_ "SigType" SG_ 2582576894 VrblNmbrOfFldsFldNmber2Repeated 1;
BA_ "SAEDocument" SG_ 2582576894 FirstPGNSupported "NMEA2000";
BA_ "SigType" SG_ 2582576894 FirstPGNSupported 6;
BA_ "SAEDocument" SG_ 2582576894 GrpFnctnTrnsmtAndReceivePGNList "NMEA2000";
BA_ "SigType" SG_ 2582576894 GrpFnctnTrnsmtAndReceivePGNList 1;
BA_ "SAEDocument" SG_ 2583234046 RouteName "NMEA2000";
BA_ "SigType" SG_ 2583234046 RouteName 1;
BA_ "SAEDocument" SG_ 2583234046 SpplmntaryRoute_WPDataAvailable "NMEA2000";
BA_ "SigType" SG_ 2583234046 SpplmntaryRoute_WPDataAvailable 4;
BA_ "SAEDocument" SG_ 2583234046 NavigationDirectionInRoute "NMEA2000";
BA_ "SAEDocument" SG_ 2583234046 RouteID "NMEA2000";
BA_ "SigType" SG_ 2583234046 RouteID 1;
BA_ "SAEDocument" SG_ 2583234046 DatabaseID "NMEA2000";
BA_ "SigType" SG_ 2583234046 DatabaseID 1;
BA_ "SAEDocument" SG_ 2583234046 nItems "NMEA2000";
BA_ "SigType" SG_ 2583234046 nItems 1;
BA_ "SAEDocument" SG_ 2583234046 StartRPS "NMEA2000";
BA_ "SigType" SG_ 2583234046 StartRPS 1;
BA_ "SAEDocument" SG_ 2381907198 WaypointClosingVelocity "NMEA2000";
BA_ "SigType" SG_ 2381907198 WaypointClosingVelocity 2;
BA_ "SAEDocument" SG_ 2381907198 DestinationWptLongitude "NMEA2000";
BA_ "SigType" SG_ 2381907198 DestinationWptLongitude 2;
BA_ "SAEDocument" SG_ 2381907198 DestinationWptLatitude "NMEA2000";
BA_ "SigType" SG_ 2381907198 DestinationWptLatitude 2;
BA_ "SAEDocument" SG_ 2381907198 DestinationWaypointNumber "NMEA2000";
BA_ "SigType" SG_ 2381907198 DestinationWaypointNumber 1;
BA_ "SAEDocument" SG_ 2381907198 OriginWaypointNumber "NMEA2000";
BA_ "SigType" SG_ 2381907198 OriginWaypointNumber 1;
BA_ "SAEDocument" SG_ 2381907198 BearingPosToDestinationWaypoint "NMEA2000";
BA_ "SigType" SG_ 2381907198 BearingPosToDestinationWaypoint 1;
BA_ "SAEDocument" SG_ 2381907198 BaringiginToDestinationWaypoint "NMEA2000";
BA_ "SigType" SG_ 2381907198 BaringiginToDestinationWaypoint 1;
BA_ "SAEDocument" SG_ 2381907198 ETADate "NMEA2000";
BA_ "SigType" SG_ 2381907198 ETADate 1;
BA_ "SAEDocument" SG_ 2381907198 ETATime "NMEA2000";
BA_ "SigType" SG_ 2381907198 ETATime 1;
BA_ "SAEDocument" SG_ 2381907198 CalculationType "NMEA2000";
BA_ "SigType" SG_ 2381907198 CalculationType 4;
BA_ "SAEDocument" SG_ 2381907198 ArrivalCircleEntered "NMEA2000";
BA_ "SigType" SG_ 2381907198 ArrivalCircleEntered 4;
BA_ "SAEDocument" SG_ 2381907198 PerpendicularCrossed "NMEA2000";
BA_ "SigType" SG_ 2381907198 PerpendicularCrossed 4;
BA_ "SAEDocument" SG_ 2381907198 Course_BearingRef "NMEA2000";
BA_ "SigType" SG_ 2381907198 Course_BearingRef 4;
BA_ "SAEDocument" SG_ 2381907198 DistanceToDestinationWaypoint "NMEA2000";
BA_ "SigType" SG_ 2381907198 DistanceToDestinationWaypoint 1;
BA_ "SAEDocument" SG_ 2381907198 SID "NMEA2000";
BA_ "SigType" SG_ 2381907198 SID 1;
BA_ "SAEDocument" SG_ 2381184766 NumberOfRqedCmdedParameters "NMEA2000";
BA_ "SigType" SG_ 2381184766 NumberOfRqedCmdedParameters 1;
BA_ "SAEDocument" SG_ 2381184766 VrblNmbrOfFldsFldNmber6Repeated3 "NMEA2000";
BA_ "SAEDocument" SG_ 2381184766 FirstParameterErrorCode "NMEA2000";
BA_ "SAEDocument" SG_ 2381184766 TransInterval_PriorityErrorCode "NMEA2000";
BA_ "SAEDocument" SG_ 2381184766 RqedCmdedPGNBeingAcknowledged "NMEA2000";
BA_ "SigType" SG_ 2381184766 RqedCmdedPGNBeingAcknowledged 6;
BA_ "SAEDocument" SG_ 2381184766 PGNErrorCode "NMEA2000";
BA_ "SAEDocument" SG_ 2381184766 VrblNmbrOfFldsFldNmber6Repeated2 "NMEA2000";
BA_ "SigType" SG_ 2381184766 VrblNmbrOfFldsFldNmber6Repeated2 1;
BA_ "SAEDocument" SG_ 2381184766 FeldNumberOfFirstCmdedParameter "NMEA2000";
BA_ "SigType" SG_ 2381184766 FeldNumberOfFirstCmdedParameter 1;
BA_ "SAEDocument" SG_ 2381184766 NmbrOfPrsOfCmddPrmetersToFollow "NMEA2000";
BA_ "SigType" SG_ 2381184766 NmbrOfPrsOfCmddPrmetersToFollow 1;
BA_ "SAEDocument" SG_ 2381184766 PrioritySetting "NMEA2000";
BA_ "SAEDocument" SG_ 2381184766 CmdedPGN "NMEA2000";
BA_ "SigType" SG_ 2381184766 CmdedPGN 6;
BA_ "SAEDocument" SG_ 2381184766 VrblNmbrOfFldsFldNmber6Repeated "NMEA2000";
BA_ "SigType" SG_ 2381184766 VrblNmbrOfFldsFldNmber6Repeated 1;
BA_ "SAEDocument" SG_ 2381184766 FieldNumberOfFirstRqedParameter "NMEA2000";
BA_ "SigType" SG_ 2381184766 FieldNumberOfFirstRqedParameter 1;
BA_ "SAEDocument" SG_ 2381184766 NmbrOfPrsOfRqParametersToFollow "NMEA2000";
BA_ "SigType" SG_ 2381184766 NmbrOfPrsOfRqParametersToFollow 1;
BA_ "SAEDocument" SG_ 2381184766 TransIntervalOffset "NMEA2000";
BA_ "SigType" SG_ 2381184766 TransIntervalOffset 1;
BA_ "SAEDocument" SG_ 2381184766 TransInterval "NMEA2000";
BA_ "SigType" SG_ 2381184766 TransInterval 1;
BA_ "SAEDocument" SG_ 2381184766 RqedPGN "NMEA2000";
BA_ "SigType" SG_ 2381184766 RqedPGN 6;
BA_ "SAEDocument" SG_ 2381184766 GroupFunctionRq_Cmd_Acknowledge "NMEA2000";
BA_ "SigType" SG_ 2381184766 GroupFunctionRq_Cmd_Acknowledge 1;
BA_ "SAEDocument" SG_ 2583500030 StationIDString "NMEA2000";
BA_ "SigType" SG_ 2583500030 StationIDString 1;
BA_ "SAEDocument" SG_ 2583500030 WaterTemp "NMEA2000";
BA_ "SigType" SG_ 2583500030 WaterTemp 1;
BA_ "SAEDocument" SG_ 2583500030 AirTemp "NMEA2000";
BA_ "SigType" SG_ 2583500030 AirTemp 1;
BA_ "SAEDocument" SG_ 2583500030 PressTendencyRate "NMEA2000";
BA_ "SigType" SG_ 2583500030 PressTendencyRate 2;
BA_ "SAEDocument" SG_ 2583500030 AtmosphericPress "NMEA2000";
BA_ "SigType" SG_ 2583500030 AtmosphericPress 1;
BA_ "SAEDocument" SG_ 2583500030 DominateWavePeriod "NMEA2000";
BA_ "SigType" SG_ 2583500030 DominateWavePeriod 1;
BA_ "SAEDocument" SG_ 2583500030 WaveHeight "NMEA2000";
BA_ "SigType" SG_ 2583500030 WaveHeight 1;
BA_ "SAEDocument" SG_ 2583500030 WindGusts "NMEA2000";
BA_ "SigType" SG_ 2583500030 WindGusts 1;
BA_ "SAEDocument" SG_ 2583500030 WindReference "NMEA2000";
BA_ "SAEDocument" SG_ 2583500030 WindDirection "NMEA2000";
BA_ "SigType" SG_ 2583500030 WindDirection 1;
BA_ "DDI" SG_ 2583500030 WindDirection 208;
BA_ "SAEDocument" SG_ 2583500030 WindSpeed "NMEA2000";
BA_ "SigType" SG_ 2583500030 WindSpeed 1;
BA_ "DDI" SG_ 2583500030 WindSpeed 207;
BA_ "SAEDocument" SG_ 2583500030 StationLocationLongitude "NMEA2000";
BA_ "SigType" SG_ 2583500030 StationLocationLongitude 2;
BA_ "SAEDocument" SG_ 2583500030 StationLocationLatitude "NMEA2000";
BA_ "SigType" SG_ 2583500030 StationLocationLatitude 2;
BA_ "SAEDocument" SG_ 2583500030 MeasurementTime "NMEA2000";
BA_ "SigType" SG_ 2583500030 MeasurementTime 1;
BA_ "SAEDocument" SG_ 2583500030 MeasurementDate "NMEA2000";
BA_ "SigType" SG_ 2583500030 MeasurementDate 1;
BA_ "SAEDocument" SG_ 2583500030 Mode "NMEA2000";
BA_ "SAEDocument" SG_ 2583499774 StationIDString "NMEA2000";
BA_ "SigType" SG_ 2583499774 StationIDString 1;
BA_ "SAEDocument" SG_ 2583499774 AirTemp "NMEA2000";
BA_ "SigType" SG_ 2583499774 AirTemp 1;
BA_ "SAEDocument" SG_ 2583499774 AtmosphericPress "NMEA2000";
BA_ "SigType" SG_ 2583499774 AtmosphericPress 1;
BA_ "SAEDocument" SG_ 2583499774 WindGusts "NMEA2000";
BA_ "SigType" SG_ 2583499774 WindGusts 1;
BA_ "SAEDocument" SG_ 2583499774 WindReference "NMEA2000";
BA_ "SAEDocument" SG_ 2583499774 WindDirection "NMEA2000";
BA_ "SigType" SG_ 2583499774 WindDirection 1;
BA_ "DDI" SG_ 2583499774 WindDirection 208;
BA_ "SAEDocument" SG_ 2583499774 WindSpeed "NMEA2000";
BA_ "SigType" SG_ 2583499774 WindSpeed 1;
BA_ "DDI" SG_ 2583499774 WindSpeed 207;
BA_ "SAEDocument" SG_ 2583499774 StationLocationLongitude "NMEA2000";
BA_ "SigType" SG_ 2583499774 StationLocationLongitude 2;
BA_ "SAEDocument" SG_ 2583499774 StationLocationLatitude "NMEA2000";
BA_ "SigType" SG_ 2583499774 StationLocationLatitude 2;
BA_ "SAEDocument" SG_ 2583499774 MeasurementTime "NMEA2000";
BA_ "SigType" SG_ 2583499774 MeasurementTime 1;
BA_ "SAEDocument" SG_ 2583499774 MeasurementDate "NMEA2000";
BA_ "SigType" SG_ 2583499774 MeasurementDate 1;
BA_ "SAEDocument" SG_ 2583499774 Mode "NMEA2000";
BA_ "SAEDocument" SG_ 2649823998 Variation "NMEA2000";
BA_ "SigType" SG_ 2649823998 Variation 2;
BA_ "SAEDocument" SG_ 2649823998 AgeOfService "NMEA2000";
BA_ "SigType" SG_ 2649823998 AgeOfService 1;
BA_ "SAEDocument" SG_ 2649823998 VariationSource "NMEA2000";
BA_ "SAEDocument" SG_ 2649823998 SequenceID_ "NMEA2000";
BA_ "SigType" SG_ 2649823998 SequenceID_ 1;
BA_ "SAEDocument" SG_ 2382103806 Mode "NMEA2000";
BA_ "SAEDocument" SG_ 2382103806 StationStatusZ "NMEA2000";
BA_ "SAEDocument" SG_ 2382103806 StationStatusY "NMEA2000";
BA_ "SAEDocument" SG_ 2382103806 StationStatusX "NMEA2000";
BA_ "SAEDocument" SG_ 2382103806 StationStatusW "NMEA2000";
BA_ "SAEDocument" SG_ 2382103806 StationStatusV "NMEA2000";
BA_ "SAEDocument" SG_ 2382103806 StationStatusMaster "NMEA2000";
BA_ "SAEDocument" SG_ 2382103806 ZSecondTD "NMEA2000";
BA_ "SigType" SG_ 2382103806 ZSecondTD 2;
BA_ "SAEDocument" SG_ 2382103806 YSecondTD "NMEA2000";
BA_ "SigType" SG_ 2382103806 YSecondTD 2;
BA_ "SAEDocument" SG_ 2382103806 XSecondTD "NMEA2000";
BA_ "SigType" SG_ 2382103806 XSecondTD 2;
BA_ "SAEDocument" SG_ 2382103806 WSecondTD "NMEA2000";
BA_ "SigType" SG_ 2382103806 WSecondTD 2;
BA_ "SAEDocument" SG_ 2382103806 VSecondTD "NMEA2000";
BA_ "SigType" SG_ 2382103806 VSecondTD 2;
BA_ "SAEDocument" SG_ 2382103806 MasterRange "NMEA2000";
BA_ "SigType" SG_ 2382103806 MasterRange 2;
BA_ "SAEDocument" SG_ 2382103806 GroupRepetitionInterval "NMEA2000";
BA_ "SigType" SG_ 2382103806 GroupRepetitionInterval 2;
BA_ "SAEDocument" SG_ 2382104318 StationIdentifier "NMEA2000";
BA_ "SigType" SG_ 2382104318 StationIdentifier 1;
BA_ "SAEDocument" SG_ 2382104318 GroupRepetitionInterval "NMEA2000";
BA_ "SigType" SG_ 2382104318 GroupRepetitionInterval 2;
BA_ "SAEDocument" SG_ 2382104062 Mode "NMEA2000";
BA_ "SAEDocument" SG_ 2382104062 StationStatusZ "NMEA2000";
BA_ "SAEDocument" SG_ 2382104062 StationStatusY "NMEA2000";
BA_ "SAEDocument" SG_ 2382104062 StationStatusX "NMEA2000";
BA_ "SAEDocument" SG_ 2382104062 StationStatusW "NMEA2000";
BA_ "SAEDocument" SG_ 2382104062 StationStatusV "NMEA2000";
BA_ "SAEDocument" SG_ 2382104062 StationStatusMaster "NMEA2000";
BA_ "SAEDocument" SG_ 2382104062 ZSecondRange "NMEA2000";
BA_ "SigType" SG_ 2382104062 ZSecondRange 2;
BA_ "SAEDocument" SG_ 2382104062 YSecondRange "NMEA2000";
BA_ "SigType" SG_ 2382104062 YSecondRange 2;
BA_ "SAEDocument" SG_ 2382104062 XSecondRange "NMEA2000";
BA_ "SigType" SG_ 2382104062 XSecondRange 2;
BA_ "SAEDocument" SG_ 2382104062 WSecondRange "NMEA2000";
BA_ "SigType" SG_ 2382104062 WSecondRange 2;
BA_ "SAEDocument" SG_ 2382104062 VSecondRange "NMEA2000";
BA_ "SigType" SG_ 2382104062 VSecondRange 2;
BA_ "SAEDocument" SG_ 2382104062 MasterRange "NMEA2000";
BA_ "SigType" SG_ 2382104062 MasterRange 2;
BA_ "SAEDocument" SG_ 2382104062 GroupRepetitionInterval "NMEA2000";
BA_ "SigType" SG_ 2382104062 GroupRepetitionInterval 2;
BA_ "SAEDocument" SG_ 2314274302 VesselHeading "NMEA2000";
BA_ "SigType" SG_ 2314274302 VesselHeading 1;
BA_ "SAEDocument" SG_ 2314274302 OffTrackLimit "NMEA2000";
BA_ "SigType" SG_ 2314274302 OffTrackLimit 2;
BA_ "SAEDocument" SG_ 2314274302 RateOfTurnder "NMEA2000";
BA_ "SigType" SG_ 2314274302 RateOfTurnder 2;
BA_ "SAEDocument" SG_ 2314274302 RadiusOfTurnder "NMEA2000";
BA_ "SigType" SG_ 2314274302 RadiusOfTurnder 2;
BA_ "SAEDocument" SG_ 2314274302 OffHeadingLimit "NMEA2000";
BA_ "SigType" SG_ 2314274302 OffHeadingLimit 1;
BA_ "SAEDocument" SG_ 2314274302 RudderLimit "NMEA2000";
BA_ "SigType" SG_ 2314274302 RudderLimit 1;
BA_ "SAEDocument" SG_ 2314274302 Track "NMEA2000";
BA_ "SigType" SG_ 2314274302 Track 1;
BA_ "SAEDocument" SG_ 2314274302 HeadingToSteer "NMEA2000";
BA_ "SigType" SG_ 2314274302 HeadingToSteer 1;
BA_ "SAEDocument" SG_ 2314274302 CmdedRudderAngle "NMEA2000";
BA_ "SigType" SG_ 2314274302 CmdedRudderAngle 2;
BA_ "SAEDocument" SG_ 2314274302 CmdedRudderDirection "NMEA2000";
BA_ "SAEDocument" SG_ 2314274302 HeadingReference "NMEA2000";
BA_ "SigType" SG_ 2314274302 HeadingReference 4;
BA_ "SAEDocument" SG_ 2314274302 TurnMode "NMEA2000";
BA_ "SAEDocument" SG_ 2314274302 SteerMode "NMEA2000";
BA_ "SAEDocument" SG_ 2314274302 Override "NMEA2000";
BA_ "SigType" SG_ 2314274302 Override 4;
BA_ "SAEDocument" SG_ 2314274302 OffTrackLimitExceeded "NMEA2000";
BA_ "SigType" SG_ 2314274302 OffTrackLimitExceeded 4;
BA_ "SAEDocument" SG_ 2314274302 OffHeadingLimitExceeded "NMEA2000";
BA_ "SigType" SG_ 2314274302 OffHeadingLimitExceeded 4;
BA_ "SAEDocument" SG_ 2314274302 RudderLimitExceeded "NMEA2000";
BA_ "SigType" SG_ 2314274302 RudderLimitExceeded 4;
BA_ "SAEDocument" SG_ 2583299582 ClockParameter2 "NMEA2000";
BA_ "SigType" SG_ 2583299582 ClockParameter2 1;
BA_ "SAEDocument" SG_ 2583299582 ClockParameter1 "NMEA2000";
BA_ "SigType" SG_ 2583299582 ClockParameter1 1;
BA_ "SAEDocument" SG_ 2583299582 MeanAnomaly "NMEA2000";
BA_ "SigType" SG_ 2583299582 MeanAnomaly 1;
BA_ "SAEDocument" SG_ 2583299582 LongitudeOfAscensionNode "NMEA2000";
BA_ "SigType" SG_ 2583299582 LongitudeOfAscensionNode 1;
BA_ "SAEDocument" SG_ 2583299582 ArgumentOfPerigee "NMEA2000";
BA_ "SigType" SG_ 2583299582 ArgumentOfPerigee 1;
BA_ "SAEDocument" SG_ 2583299582 RootOfSemimajorAxis "NMEA2000";
BA_ "SigType" SG_ 2583299582 RootOfSemimajorAxis 1;
BA_ "SAEDocument" SG_ 2583299582 RateOfRightAscension "NMEA2000";
BA_ "SigType" SG_ 2583299582 RateOfRightAscension 1;
BA_ "SAEDocument" SG_ 2583299582 InclinationAngle "NMEA2000";
BA_ "SigType" SG_ 2583299582 InclinationAngle 1;
BA_ "SAEDocument" SG_ 2583299582 AlmanacReferenceTime "NMEA2000";
BA_ "SigType" SG_ 2583299582 AlmanacReferenceTime 1;
BA_ "SAEDocument" SG_ 2583299582 Eccentricity "NMEA2000";
BA_ "SigType" SG_ 2583299582 Eccentricity 1;
BA_ "SAEDocument" SG_ 2583299582 SVHealthBits "NMEA2000";
BA_ "SigType" SG_ 2583299582 SVHealthBits 1;
BA_ "SAEDocument" SG_ 2583299582 GPSWeekNumber "NMEA2000";
BA_ "SigType" SG_ 2583299582 GPSWeekNumber 1;
BA_ "SAEDocument" SG_ 2583299582 PRN "NMEA2000";
BA_ "SigType" SG_ 2583299582 PRN 1;
VAL_ 2349596414 DrvrActvtnDmndFrAdvncdEmrgncyBrk 3 "dont care / take no action" 2 "reserved" 1 "the driver wants the Advanced Emergency Braking System to warn or intervene if necessary no deactivation of" 0 "the driver does not want the Advanced Emergency Braking System to warn or intervene at any time deactivation of" ;
VAL_ 2566705150 NOxSnsorATI2SelfdiagnosisTrigger 15 "Not supported" 5 "1110 Reserved" 4 "NOx Sensor ATI2 Self Diagnosis Request at After Run" 3 "NOx Sensor ATI2 Self Diagnosis Request at fuel cut" 2 "NOx Sensor ATI2 Self Diagnosis Request at partial load" 1 "NOx Sensor ATI2 Self Diagnosis Request at Lambda10" 0 "Diagnostic mode disabled" ;
VAL_ 2566705150 NOxSnsorATO2SelfdiagnosisTrigger 15 "Not supported" 5 "1110 Reserved" 4 "NOx Sensor ATO2 Self Diagnosis Request at After Run" 3 "NOx Sensor ATO2 Self Diagnosis Request at fuel cut" 2 "NOx Sensor ATO2 Self Diagnosis Request at partial load" 1 "NOx Sensor ATO2 Self Diagnosis Request at Lambda10" 0 "Diagnostic mode disabled" ;
VAL_ 2566705150 NOxSnsorATI1SelfdiagnosisTrigger 15 "Not supported" 5 "1110 Reserved" 4 "NOx Sensor ATI1 Self Diagnosis Request at After Run" 3 "NOx Sensor ATI1 Self Diagnosis Request at fuel cut" 2 "NOx Sensor ATI1 Self Diagnosis Request at partial load" 1 "NOx Sensor ATI1 Self Diagnosis Request at Lambda10" 0 "Diagnostic mode disabled" ;
VAL_ 2566705150 NOxSnsorATO1SelfdiagnosisTrigger 15 "Not supported" 5 "1110 Reserved" 4 "NOx Sensor ATO1 Self Diagnosis Request at After Run" 3 "NOx Sensor ATO1 Self Diagnosis Request at fuel cut" 2 "NOx Sensor ATO1 Self Diagnosis Request at partial load" 1 "NOx Sensor ATO1 Self Diagnosis Request at Lambda10" 0 "Diagnostic mode disabled" ;
VAL_ 2566704382 Aftrtrtmnt2OtltGsSnsrPowerSupply 3 "Unavailable" 2 "Error" 1 "On The ECU is powering the Aftertreatment 2 Outlet Gas Sensor" 0 "Off" ;
VAL_ 2566704382 Aftrtrtmnt2IntkGsSnsrPowerSupply 3 "Unavailable" 2 "Error" 1 "On The ECU is powering the Aftertreatment 2 Intake Gas Sensor" 0 "Off" ;
VAL_ 2566704382 Aftrtrtmnt1OtltGsSnsrPowerSupply 3 "Unavailable" 2 "Error" 1 "On The ECU is powering the Aftertreatment 1 Outlet Gas Sensor" 0 "Off" ;
VAL_ 2566704382 Aftrtrtmnt1IntkGsSnsrPowerSupply 3 "Unavailable" 2 "Error" 1 "On The ECU is powering the Aftertreatment 1 Intake Gas Sensor" 0 "Off" ;
VAL_ 2566704126 EngExhstGsRcrcltn1Acttr2OprtnStt 15 "Not available" 14 "Error" 6 "1101 Reserved for future assignment" 5 "Uncontrolled Shutdown Active actuator current is off so it is limp" 4 "Controlled Shutdown Active driving to the default position  usually this means closed" 3 "Derate Active torque output reduced due to environmental conditions" 2 "Alarm High Severity functional but transient performance may be reduced" 1 "Alarm fully operational but needs service" 0 "Normal" ;
VAL_ 2566704126 EngExhstGsRcrcltn1Acttr1OprtnStt 15 "Not available" 14 "Error" 6 "1101 Reserved for future assignment" 5 "Uncontrolled Shutdown Active actuator current is off so it is limp" 4 "Controlled Shutdown Active driving to the default position  usually this means closed" 3 "Derate Active torque output reduced due to environmental conditions" 2 "Alarm High Severity functional but transient performance may be reduced" 1 "Alarm fully operational but needs service" 0 "Normal" ;
VAL_ 2566704126 EngExhstGsRcrcltn1Acttr2TmpSttus 7 "Not available" 6 "Error" 5 "Not Defined" 4 "Low Most severe" 3 "Low Least severe" 2 "In Range" 1 "High Least severe" 0 "High Most severe" ;
VAL_ 2566704126 EngExhstGsRcrcltn1Acttr1TmpSttus 7 "Not available" 6 "Error" 5 "Not Defined" 4 "Low Most severe" 3 "Low Least severe" 2 "In Range" 1 "High Least severe" 0 "High Most severe" ;
VAL_ 2566703870 EngExhstGsRcrcltn2Acttr2OprtnStt 15 "Not available" 14 "Error" 6 "1101 Reserved for future assignment" 5 "Uncontrolled Shutdown Active actuator current is off so it is limp" 4 "Controlled Shutdown Active driving to the default position  usually this means closed" 3 "Derate Active torque output reduced due to environmental conditions" 2 "Alarm High Severity functional but transient performance may be reduced" 1 "Alarm fully operational but needs service" 0 "Normal" ;
VAL_ 2566703870 EngExhstGsRcrcltn2Acttr1OprtnStt 5 "Uncontrolled Shutdown Active actuator current is off so it is limp" 4 "Controlled Shutdown Active driving to the default position  usually this means closed" 3 "Derate Active torque output reduced due to environmental conditions" 2 "Alarm High Severity functional but transient performance may be reduced" 1 "Alarm fully operational but needs service" 0 "Normal" 15 "Not available" 14 "Error" 6 "1101 Reserved for future assignment" ;
VAL_ 2566703870 EngExhstGsRcrcltn2Acttr2TmpSttus 7 "Not available" 6 "Error" 5 "Not Defined" 4 "Low Most severe" 3 "Low Least severe" 2 "In Range" 1 "High Least severe" 0 "High Most severe" ;
VAL_ 2566703870 EngExhstGsRcrcltn2Acttr1TmpSttus 7 "Not available" 6 "Error" 5 "Not Defined" 4 "Low Most severe" 3 "Low Least severe" 2 "In Range" 1 "High Least severe" 0 "High Most severe" ;
VAL_ 2566703358 EngFuelingInhibitAllowed 3 "Not Supported" 2 "SAE Reserved" 1 "Engine will stop fueling in response to SPN 5793 Desired Engine Fueling State" 0 "Engine currently will not stop fueling in response to SPN 5793 Desired Engine Fueling State" ;
VAL_ 2566703358 FeedbackEngFuelingState 3 "Not Supported" 2 "No active request per SPN 5793 Desired Engine Fueling State" 1 "Engine will be kept running SPN 5793 Desired Engine Fueling State  01" 0 "Fueling is or will be inhibited SPN 5793 Desired Engine Fueling State  00" ;
VAL_ 2566701822 HybridSystemStopIndicator 3 "Not available" 2 "Hybrid System Stop Indicator is flashing" 1 "Hybrid System Stop Indicator is on continuously" 0 "Hybrid System Stop Indicator is off" ;
VAL_ 2566701822 HybridSystemOverheatIndicator 3 "Not available" 2 "Hybrid System Temperature Indicator is flashing" 1 "Hybrid System Temperature Indicator is on continuously" 0 "Hybrid System Temperature Indicator is off" ;
VAL_ 2566701822 HybridSystemWarningIndicator 3 "Not available" 2 "Hybrid System Warning Indicator is flashing" 1 "Hybrid System Warning Indicator is on continuously" 0 "Hybrid System Warning Indicator is off" ;
VAL_ 2431661310 Aftrtrtmnt2SCRIntrmdtNH3GsSn5861 3 "Heater off or Not available" 2 "Preheat 1" 1 "Preheat 2" 0 "Automatic" ;
VAL_ 2431661310 Aftrtrtmnt2SCRIntrmdtNH3GsSnsrAt 3 "Not available" 2 "Error" 1 "Heater element is in range" 0 "Heater element is not in range" ;
VAL_ 2431661310 Aftrtrtmnt2SCRIntrmdtNH3GsSnsrPw 3 "Not available" 2 "Error" 1 "Heater element is in range" 0 "Heater element is not in range" ;
VAL_ 2431661310 Aftrtrtmnt2SCRIntrmdtNH3RdngStbl 3 "Not available" 2 "Error" 1 "Reading is stable" 0 "Reading is not stable" ;
VAL_ 2431661054 Aftrtrtmnt1SCRIntrmdtNH3GsSn5854 3 "Heater off or not available" 2 "Preheat 1" 1 "Preheat 2" 0 "Automatic" ;
VAL_ 2431661054 Aftrtrtmnt1SCRIntrmdtNH3GsSnsrAt 3 "Not available" 2 "Error" 1 "Heater element is in range" 0 "Heater element is not in range" ;
VAL_ 2431661054 Aftrtrtmnt1SCRIntrmdtNH3GsSnsrPw 3 "Not available" 2 "Error" 1 "Power is in range" 0 "Power is not in range" ;
VAL_ 2431661054 Aftrtrtmnt1SCRIntrmdtNH3RdngStbl 3 "Not available" 2 "Error" 1 "Reading is stable" 0 "Reading is not stable" ;
VAL_ 2230334206 LnrDsplcmntSnsrSnsrFigureOfMerit 3 "Sensor not available" 2 "Sensor failed" 1 "Sensor degraded" 0 "Sensor fully functional" ;
VAL_ 2230333950 WandSensorFigureOfMerit 3 "Sensor not available" 2 "Sensor failed" 1 "Sensor degraded" 0 "Sensor fully functional" ;
VAL_ 2364551166 BndOffPrbabilityOfRelevantObject 7 "signal not available / not installed" 6 "error indication" 5 "relevant object is already in a turning maneuver" 4 "highest probability for a bend off maneuver of the relevant object" 3 "high probability for a bend off maneuver of the relevant object" 2 "medium probability for a bend off maneuver of the relevant object" 1 "low probability for a bend off maneuver of the relevant object" 0 "no indication for a bend off maneuver of the relevant object" ;
VAL_ 2364551166 RlvntObjctDtctdFrAdvncdEmrgncyBr 7 "signal not available / not installed" 6 "error indication" 2 "relevant object is not being detected reliably" 1 "relevant object is being monitored" 0 "no relevant object monitored" ;
VAL_ 2364551166 CollisionWarningStatus 15 "dont care / take no action" 7 "warning level 7  highest" 6 "warning level 6" 5 "warning level 5" 4 "warning level 4" 3 "warning level 3" 2 "warning level 2" 1 "warning level 1  lowest" 0 "no warning" ;
VAL_ 2364551166 AdvncdEmrgencyBrakingSystemState 15 "not available / not installed" 14 "error indication" 7 "emergency braking active" 6 "collision warning with braking eg brake jerk or partial braking" 5 "collision warning active not affecting vehicle dynamics" 4 "driver overrides system" 3 "system is ready no warning and no braking active" 2 "system is deactivated by driver" 1 "system is temporarily not available eg due to boundary conditions necessary for operation" 0 "system is not ready initialization not finished" ;
VAL_ 2566730238 Fan2DriveState 15 "Not available" 14 "Other" 13 "Engine brake" 12 "Timer" 11 "A/C system" 10 "Transmission retarder" 9 "Manual control" 8 "Reverse Operation" 7 "Default Operation" 6 "Excessive hydraulic oil temperature" 5 "Excessive transmission oil temperature" 4 "Excessive engine coolant temperature" 3 "Excessive engine oil temperature" 2 "Excessive engine air temperature" 1 "Engine systemGeneral" 0 "Fan off" ;
VAL_ 2566711038 LubricationTimingCycleStatus 3 "Not available or not installed" 2 "Error" 1 "Enabled" 0 "Paused" ;
VAL_ 2566711038 LubricationReservoirLevel 3 "Not available or not installed" 2 "Error" 1 "Reservoir Low" 0 "Reservoir Not Low" ;
VAL_ 2566711038 LubricationPumpEnableStatus 3 "Not available" 2 "Error" 1 "Enabled" 0 "Disabled" ;
VAL_ 2566711038 LubricationOperationModeStatus 7 "Not Available" 6 "Error" 5 "Reserved" 4 "Test Mode  3" 3 "Test Mode  2" 2 "Test Mode  1" 1 "Manual Service Mode" 0 "Automatic Mode" ;
VAL_ 2566711038 LubricationCycleModeStatus 7 "Not available" 6 "Error" 3 "to 101  Reserved" 2 "Cycle mode  3 Highest Lubrication Frequency" 1 "Cycle mode  2" 0 "Cycle mode  1 Lowest Lubrication Frequency" ;
VAL_ 2566711038 LubricationCycleModeLockStatus 3 "Not available" 2 "Error" 1 "Locked" 0 "Not Locked" ;
VAL_ 2566710014 SupplementalFanDriveStatus 15 "Not available" 14 "Error" 6 "1101   Reserved for future assignment  Not used" 5 "Uncontrolled Shutdown Active  Actuator current is off so it is limp" 4 "Controlled Shutdown Active  Driving to the default position  usually this means closed" 3 "Derate Active  Torque output reduced due to environmental conditions" 2 "Alarm High Severity  Functional but transient performance may be reduced" 1 "Alarm  Fully operational but needs service" 0 "Normal  OK" ;
VAL_ 2566710014 SupplementalFanCtrlTempStatus 7 "Not available" 6 "Error" 5 "Not Defined" 4 "Low Most severe" 3 "Low Least severe" 2 "In Range" 1 "High Least severe" 0 "High most severe" ;
VAL_ 2566710014 SupplementalFanVelocityStatus 15 "Not available" 14 "Error" 4 "Fan Stall" 3 "Fan Spin Down" 2 "Fan Spin Up" 1 "Velocity Error  unable to achieve commanded speed" 0 "At Velocity Fan OK" ;
VAL_ 2566710014 SupplementalFanDirectionStatus 3 "Not available/Not installed" 2 "Error" 1 "Reverse" 0 "Forward" ;
VAL_ 2566710014 SupplementalFanEnableStatus 3 "Not available/Not installed" 2 "Error" 1 "Enabled" 0 "Disabled" ;
VAL_ 2566708478 CruiseCtrlSystemCmdState 3 "Cruise control has been reactivated by Cruise Control Resume Command SPN 5604 and Cruise Control States" 2 "Cruise control  has been disabled by Cruise Control Pause Command SPN 5605" 1 "Cruise control has been disabled by Cruise Control Disable Command SPN 5603" 0 "No Cruise Control System Command" 7 "Not Supported" 5 "110  SAE Reserved" 4 "Cruise control device has received a Cruise Control Resume Command SPN 5604 but there is no previous set" ;
VAL_ 2566708478 AdptiveCruiseCtrlReadinessStatus 3 "Not Available/Not Supported" 2 "Error Condition  Prevents system from responding to adaptive cruise controller commands even though it is" 1 "On  Cruise Control System is configured to accept commands from an adaptive cruise controller" 0 "Off  Cruise Control System is not configured to accept commands from an adaptive cruise controller" ;
VAL_ 2315059966 WindReference 7 "Null" 6 "Error" 5 "Reserved" 3 "True (boat referenced)" 2 "Apparent" 1 "Magnetic" 0 "True (referenced to North)" ;
VAL_ 2315059966 SequenceID_ 255 "nVldPsFxTTItTRng0T250FrVldPstnFx" ;
VAL_ 2381646846 SID 255 "nVldPsFxTTItTRng0T250FrVldPstnFx" ;
VAL_ 2314277630 HeadingSensorReference 3 "Null" 2 "Error" 1 "Magnetic" 0 "True" ;
VAL_ 2314277630 SID 255 "nVldPsFxTTItTRng0T250FrVldPstnFx" ;
VAL_ 2515667454 EngInstance 255 "Not available" 254 "Error" 253 "Reserve" 1 "DlEngStrBrdTStrnStrbrdNInstncNWh" 0 "SingleEngDualEnginePort" ;
VAL_ 2314339838 TransGear 3 "[Unavailable, Unknown]" 2 "Reverse" 1 "Neutral" 0 "Forward" ;
VAL_ 2314339838 TransInstance 255 "Not available" 254 "Error" 253 "Reserve" 1 "DlEngStrBrdTStrnStrbrdNInstncNWh" 0 "SingleEngDualEnginePort" ;
VAL_ 2314602750 BearingReference 3 "Releative" 2 "Error" 1 "Magnetic" 0 "True" ;
VAL_ 2314602750 SequenceID_ 255 "nVldPsFxTTItTRng0T250FrVldPstnFx" ;
VAL_ 2314602750 UTCOfFix 0 "midnight,  time is in UTC" ;
VAL_ 2381842942 Time 0 "midnight,  time is in UTC" ;
VAL_ 2381911550 MarkType 15 "Null" 14 "Error" 5 "Reserved" 4 "Waypoint" 3 "Wheelover" 2 "Reference (general)" 1 "Turning Point" 0 "Collision" ;
VAL_ 2381911550 SID 255 "nVldPsFxTTItTRng0T250FrVldPstnFx" ;
VAL_ 2583499006 MeasurementTime 0 "midnight,  time is in UTC" ;
VAL_ 2583499006 TideTendency 11 "Unavailable, Unknown" 10 "Error" 1 "Rising" 0 "Falling" ;
VAL_ 2583499006 Mode 15 "Data not available" 14 "Error" 4 "Manual mode" 3 "Simulator mode" 2 "Estimated mode" 1 "Differential, enhanced mode" 0 "Autonomous mode" ;
VAL_ 2381320446 Time 0 "midnight,  time is in UTC" ;
VAL_ 2381320446 Source 15 "Null" 14 "reserved" 5 "Local Crystal clock, 

0x6 -" 4 "Local Rubidium clock" 3 "Local Cesium clock" 2 "WWVEqvalentRadioStationTimeSync" 1 "GLONASS" 0 "GPS" ;
VAL_ 2381320446 SID 255 "nVldPsFxTTItTRng0T250FrVldPstnFx" ;
VAL_ 2381451006 Switch28 3 "No action" 2 "Reserved" 1 "TurnOnEnableSetMake1" 0 "TurnOffDisableResetMake0" ;
VAL_ 2381451006 Switch27 3 "No action" 2 "Reserved" 1 "TurnOnEnableSetMake1" 0 "TurnOffDisableResetMake0" ;
VAL_ 2381451006 Switch26 3 "No action" 2 "Reserved" 1 "TurnOnEnableSetMake1" 0 "TurnOffDisableResetMake0" ;
VAL_ 2381451006 Switch25 3 "No action" 2 "Reserved" 1 "TurnOnEnableSetMake1" 0 "TurnOffDisableResetMake0" ;
VAL_ 2381451006 Switch24 3 "No action" 2 "Reserved" 1 "TurnOnEnableSetMake1" 0 "TurnOffDisableResetMake0" ;
VAL_ 2381451006 Switch23 3 "No action" 2 "Reserved" 1 "TurnOnEnableSetMake1" 0 "TurnOffDisableResetMake0" ;
VAL_ 2381451006 Switch22 3 "No action" 2 "Reserved" 1 "TurnOnEnableSetMake1" 0 "TurnOffDisableResetMake0" ;
VAL_ 2381451006 Switch21 3 "No action" 2 "Reserved" 1 "TurnOnEnableSetMake1" 0 "TurnOffDisableResetMake0" ;
VAL_ 2381451006 Switch20 3 "No action" 2 "Reserved" 1 "TurnOnEnableSetMake1" 0 "TurnOffDisableResetMake0" ;
VAL_ 2381451006 Switch19 3 "No action" 2 "Reserved" 1 "TurnOnEnableSetMake1" 0 "TurnOffDisableResetMake0" ;
VAL_ 2381451006 Switch18 3 "No action" 2 "Reserved" 1 "TurnOnEnableSetMake1" 0 "TurnOffDisableResetMake0" ;
VAL_ 2381451006 Switch17 3 "No action" 2 "Reserved" 1 "TurnOnEnableSetMake1" 0 "TurnOffDisableResetMake0" ;
VAL_ 2381451006 Switch16 3 "No action" 2 "Reserved" 1 "TurnOnEnableSetMake1" 0 "TurnOffDisableResetMake0" ;
VAL_ 2381451006 Switch15 3 "No action" 2 "Reserved" 1 "TurnOnEnableSetMake1" 0 "TurnOffDisableResetMake0" ;
VAL_ 2381451006 Switch14 3 "No action" 2 "Reserved" 1 "TurnOnEnableSetMake1" 0 "TurnOffDisableResetMake0" ;
VAL_ 2381451006 Switch13 3 "No action" 2 "Reserved" 1 "TurnOnEnableSetMake1" 0 "TurnOffDisableResetMake0" ;
VAL_ 2381451006 Switch12 3 "No action" 2 "Reserved" 1 "TurnOnEnableSetMake1" 0 "TurnOffDisableResetMake0" ;
VAL_ 2381451006 Switch11 3 "No action" 2 "Reserved" 1 "TurnOnEnableSetMake1" 0 "TurnOffDisableResetMake0" ;
VAL_ 2381451006 Switch10 3 "No action" 2 "Reserved" 1 "TurnOnEnableSetMake1" 0 "TurnOffDisableResetMake0" ;
VAL_ 2381451006 Switch9 3 "No action" 2 "Reserved" 1 "TurnOnEnableSetMake1" 0 "TurnOffDisableResetMake0" ;
VAL_ 2381451006 Switch8 3 "No action" 2 "Reserved" 1 "TurnOnEnableSetMake1" 0 "TurnOffDisableResetMake0" ;
VAL_ 2381451006 Switch7 3 "No action" 2 "Reserved" 1 "TurnOnEnableSetMake1" 0 "TurnOffDisableResetMake0" ;
VAL_ 2381451006 Switch6 3 "No action" 2 "Reserved" 1 "TurnOnEnableSetMake1" 0 "TurnOffDisableResetMake0" ;
VAL_ 2381451006 Switch5 3 "No action" 2 "Reserved" 1 "TurnOnEnableSetMake1" 0 "TurnOffDisableResetMake0" ;
VAL_ 2381451006 Switch4 3 "No action" 2 "Reserved" 1 "TurnOnEnableSetMake1" 0 "TurnOffDisableResetMake0" ;
VAL_ 2381451006 Switch3 3 "No action" 2 "Reserved" 1 "TurnOnEnableSetMake1" 0 "TurnOffDisableResetMake0" ;
VAL_ 2381451006 Switch2 3 "No action" 2 "Reserved" 1 "TurnOnEnableSetMake1" 0 "TurnOffDisableResetMake0" ;
VAL_ 2381451006 Switch1 3 "No action" 2 "Reserved" 1 "TurnOnEnableSetMake1" 0 "TurnOffDisableResetMake0" ;
VAL_ 2314535934 SequenceID_ 255 "nVldPsFxTTItTRng0T250FrVldPstnFx" ;
VAL_ 2381908990 SetReference 3 "Null" 2 "Error" 1 "Magnetic" 0 "True" ;
VAL_ 2381908990 SID 255 "nVldPsFxTTItTRng0T250FrVldPstnFx" ;
VAL_ 2583499262 MeasurementTime 0 "midnight,  time is in UTC" ;
VAL_ 2583499262 Mode 15 "Data not available" 14 "Error" 4 "Manual mode" 3 "Simulator mode" 2 "Estimated mode" 1 "Differential, enhanced mode" 0 "Autonomous mode" ;
VAL_ 2314276350 Directionder 2 "Move to port" 1 "Move to starboard" 0 "No Order" ;
VAL_ 2314276350 RudderInstance 255 "Not available" 254 "Error" 253 "Reserve" 1 "DlEngStrBrdTStrnStrbrdNInstncNWh" 0 "SingleEngDualEnginePort" ;
VAL_ 2650543614 NavMethodInLegAfterWP 3 "Null" 2 "Error" 1 "Rhumb Line calculations" 0 "Great Circle calculations" ;
VAL_ 2314277886 SequenceID_ 255 "nVldPsFxTTItTRng0T250FrVldPstnFx" ;
VAL_ 2314732542 SequenceID_ 255 "nVldPsFxTTItTRng0T250FrVldPstnFx" ;
VAL_ 2582576894 GrpFnctnTrnsmtAndReceivePGNList 1 "Receive PGN List Message" 0 "Transmit PGN List Message" ;
VAL_ 2583234046 SpplmntaryRoute_WPDataAvailable 3 "[Unavailable, Unknown]" 2 "Error" 1 "[Yes, On, Enabled, Set, '1']" 0 "[No, Off, Disabled, Reset, '0']" ;
VAL_ 2381907198 ETATime 0 "midnight,  time is in UTC" ;
VAL_ 2381907198 CalculationType 3 "Null" 2 "Error" 1 "Rhumb Line calculations" 0 "Great Circle calculations" ;
VAL_ 2381907198 ArrivalCircleEntered 3 "[Unavailable, Unknown]" 2 "Error" 1 "[Yes, On, Enabled, Set, '1']" 0 "[No, Off, Disabled, Reset, '0']" ;
VAL_ 2381907198 PerpendicularCrossed 3 "[Unavailable, Unknown]" 2 "Error" 1 "[Yes, On, Enabled, Set, '1']" 0 "[No, Off, Disabled, Reset, '0']" ;
VAL_ 2381907198 Course_BearingRef 3 "Null" 2 "Error" 1 "Magnetic" 0 "True" ;
VAL_ 2381907198 SID 255 "nVldPsFxTTItTRng0T250FrVldPstnFx" ;
VAL_ 2381184766 VrblNmbrOfFldsFldNmber6Repeated3 5 "RqCmdGroupFunctionNotSupported" 4 "Access denied" 3 "RqCmdParameterOutofrange" 2 "Temporarily unable to comply" 1 "InvalidRqCmdParameterField" 0 "No Error/Acknowledge" ;
VAL_ 2381184766 FirstParameterErrorCode 5 "RqCmdGroupFunctionNotSupported" 4 "Access denied" 3 "RqCmdParameterOutofrange" 2 "Temporarily unable to comply" 1 "InvalidRqCmdParameterField" 0 "No Error/Acknowledge" ;
VAL_ 2381184766 TransInterval_PriorityErrorCode 4 "Request is not supported" 3 "Access denied" 2 "TrnsmtIntrvlIsLssThnMsrmnt_Clclt" 1 "TrnsmtIntrvl_PrrityNotSupported" 0 "No Error/Acknowledge" ;
VAL_ 2381184766 PGNErrorCode 4 "Request is not supported" 3 "Access denied" 2 "PGN temporarily not available" 1 "PGN not supported" 0 "No Error/Acknowledge" ;
VAL_ 2381184766 PrioritySetting 15 "reserved" 9 "returnPriorityToDefault0xATo" 8 "do not change priority" 7 "commanded priority value" ;
VAL_ 2381184766 TransIntervalOffset 65535 "Do not change offset" 0 "transmit immediately" ;
VAL_ 2381184766 TransInterval 65535 "Do not change interval" 0 "Turn-off transmission" ;
VAL_ 2381184766 GroupFunctionRq_Cmd_Acknowledge 2 "Acknowledge Message" 1 "Command Message" 0 "Request Message" ;
VAL_ 2583500030 WindReference 7 "Null" 6 "Error" 5 "Reserved" 3 "True (boat referenced)" 2 "Apparent" 1 "Magnetic" 0 "True (referenced to North)" ;
VAL_ 2583500030 MeasurementTime 0 "midnight,  time is in UTC" ;
VAL_ 2583500030 Mode 15 "Data not available" 14 "Error" 4 "Manual mode" 3 "Simulator mode" 2 "Estimated mode" 1 "Differential, enhanced mode" 0 "Autonomous mode" ;
VAL_ 2583499774 WindReference 7 "Null" 6 "Error" 5 "Reserved" 3 "True (boat referenced)" 2 "Apparent" 1 "Magnetic" 0 "True (referenced to North)" ;
VAL_ 2583499774 MeasurementTime 0 "midnight,  time is in UTC" ;
VAL_ 2583499774 Mode 15 "Data not available" 14 "Error" 4 "Manual mode" 3 "Simulator mode" 2 "Estimated mode" 1 "Differential, enhanced mode" 0 "Autonomous mode" ;
VAL_ 2649823998 VariationSource 63 "Data Not Available" 62 "Reserve" 9 "Reserve,

 thru" 8 "WMM 2020" 7 "WMM 2015" 6 "WMM 2010" 5 "WMM 2005" 4 "WMM 2000" 3 "Automatic Calculation" 2 "Automatic Table" 1 "Automatic - Chart" 0 "Manual Entry" ;
VAL_ 2649823998 SequenceID_ 255 "nVldPsFxTTItTRng0T250FrVldPstnFx" ;
VAL_ 2382103806 Mode 15 "Data not available" 14 "Error" 4 "Manual mode" 3 "Simulator mode" 2 "Estimated mode" 1 "Differential, enhanced mode" 0 "Autonomous mode" ;
VAL_ 2382103806 GroupRepetitionInterval 9960 "99,600,000 ns)" ;
VAL_ 2382104318 GroupRepetitionInterval 9960 "99,600,000 ns)" ;
VAL_ 2382104062 Mode 15 "Data not available" 14 "Error" 4 "Manual mode" 3 "Simulator mode" 2 "Estimated mode" 1 "Differential, enhanced mode" 0 "Autonomous mode" ;
VAL_ 2382104062 GroupRepetitionInterval 9960 "99,600,000 ns)" ;
VAL_ 2314274302 CmdedRudderDirection 2 "Move to port" 1 "Move to starboard" 0 "No Order" ;
VAL_ 2314274302 HeadingReference 3 "Null" 2 "Error" 1 "Magnetic" 0 "True" ;
VAL_ 2314274302 TurnMode 2 "rdsCtrlldDfntnsRddrAnOprtrStRddr" 1 "turn rate controlled" 0 "Rudder Limit controlled" ;
VAL_ 2314274302 SteerMode 2 "Follow-up Device" 1 "Non-Follow-up Device" 0 "Main Steering" 5 "TrckCtrlDfntnsMnStr_OtsdSystmMnS" 4 "Heading Control" 3 "Heading Control Standalone" ;
VAL_ 2314274302 Override 0 "NYsMnsATmprryIntrrptnOfSlctdStrM" 1 "Yes" ;
VAL_ 2314274302 OffTrackLimitExceeded 3 "[Unavailable, Unknown]" 2 "Error" 1 "[Yes, On, Enabled, Set, '1']" 0 "[No, Off, Disabled, Reset, '0']" ;
VAL_ 2314274302 OffHeadingLimitExceeded 3 "[Unavailable, Unknown]" 2 "Error" 1 "[Yes, On, Enabled, Set, '1']" 0 "[No, Off, Disabled, Reset, '0']" ;
VAL_ 2314274302 RudderLimitExceeded 3 "[Unavailable, Unknown]" 2 "Error" 1 "[Yes, On, Enabled, Set, '1']" 0 "[No, Off, Disabled, Reset, '0']" ;
VAL_ 2583299582 PRN 96 "GLONASSFrGLONASSStlltsArIdntfdBy" 64 "SBASStlltBsdAgmentationSystem65" 1 "GPS, 

33-" 0 "value not used" ;
SIG_VALTYPE_ 2583172606 EllipsoidFlatteningInverse : 1;
SIG_VALTYPE_ 2583172606 Scale : 1;
SIG_VALTYPE_ 2583172606 RotationInZ : 1;
SIG_VALTYPE_ 2583172606 RotationInY : 1;
SIG_VALTYPE_ 2583172606 RotationInX : 1;
SIG_VALTYPE_ 2583499262 Salinity : 1;
